[part 7 of 12: package /Cluster]
AUTOSAR XML (schema 4-3-0)
package /Cluster  (continued)
  can cluster HCP5_CANFD01: baudrate=500000, protocol-name=CAN, protocol-version=2.0, bus-off-recovery={bor-counter-l-1-to-l-2=1, bor-time-l-1=0.05, bor-time-l-2=0.2}, can-fd-baudrate=2000000  (continued)
    can physical channel CHNL: comm-connectors=CN_HCP5_CANFD01  (continued)
      frame XCP_Hybrid_01_DTO_01_FD_XIX_HCP5_CANFD01: id 0x1BFC6701, from BMC_HV, frame-length=64, can-addressing-mode=EXTENDED, can-frame-rx-behavior=CAN-FD, can-frame-tx-behavior=CAN-FD
        general purpose i pdu XCP_Hybrid_01_DTO_01_FD_XIX_HCP5_CANFD01: category=XCP, length=64
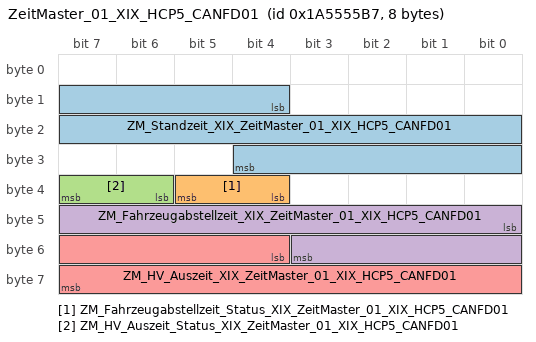
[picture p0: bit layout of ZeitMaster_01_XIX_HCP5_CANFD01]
      frame ZeitMaster_01_XIX_HCP5_CANFD01: id 0x1A5555B7, to BMC_HV, frame-length=8, can-addressing-mode=EXTENDED, can-frame-rx-behavior=CAN-FD, can-frame-tx-behavior=CAN-FD
        pdu ZeitMaster_01_XIX_HCP5_CANFD01: length=8, transmission-mode-true-timing=cyclic-timing={time-offset=0, time-period=1}, unused-bit-pattern=0
          signal ZM_Standzeit_XIX_ZeitMaster_01_XIX_HCP5_CANFD01: start 12, 17 bit, little-endian, data-type-policy=OVERRIDE, i-signal-type=PRIMITIVE, init-value=131070, base-type=BT_ZM_Standzeit, invalid-value=Invalid_ZM_Standzeit_XIX_ZeitMaster_01_XIX_HCP5_CANFD01:131071, compu {phys=raw for raw 0..131068, 131069=Cx1fffd_nicht_verfuegbar (CM_ZM_Standzeit_Cx1fffd_nicht_verfuegbar), 131070=Cx1fffe_Init (CM_ZM_Standzeit_Cx1fffe_Init), 131071=Cx1ffff_Fehler (CM_ZM_Standzeit_Cx1ffff_Fehler); unit Unit_Secon}, range phys 0..131068 Unit_Secon, raw 0..131071, unit=Unit_Secon, transfer-property=PENDING  # Standzeit des Fahrzeugs
          signal ZM_Fahrzeugabstellzeit_Status_XIX_ZeitMaster_01_XIX_HCP5_CANFD01: start 36, 2 bit, little-endian, data-type-policy=OVERRIDE, i-signal-type=PRIMITIVE, init-value=0, base-type=BT_ZM_Fahrzeugabstellzeit_Status, compu {0=Cx0_Abstellzeit_nicht_berechnet (CM_ZM_Fahrzeugabstellzeit_Status_Cx0_Abstellzeit_nicht_berechnet), 1=Cx1_Abstellzeit_berechnet (CM_ZM_Fahrzeugabstellzeit_Status_Cx1_Abstellzeit_berechnet), 2=Cx2_Abstellzeit_Minimalwert (CM_ZM_Fahrzeugabstellzeit_Status_Cx2_Abstellzeit_Minimalwert), 3=Cx3_Abstellzeit_ungueltig (CM_ZM_Fahrzeugabstellzeit_Status_Cx3_Abstellzeit_ungueltig)}, range raw 0..3, transfer-property=PENDING  # Status Fahrzeugabstellzeit
          signal ZM_HV_Auszeit_Status_XIX_ZeitMaster_01_XIX_HCP5_CANFD01: start 38, 2 bit, little-endian, data-type-policy=OVERRIDE, i-signal-type=PRIMITIVE, init-value=0, base-type=BT_ZM_HV_Auszeit_Status, compu {0=Cx0_nicht_berechnet (CM_ZM_HV_Auszeit_Status_Cx0_nicht_berechnet), 1=Cx1_berechnet (CM_ZM_HV_Auszeit_Status_Cx1_berechnet), 2=Cx2_Minimalwert (CM_ZM_HV_Auszeit_Status_Cx2_Minimalwert), 3=Cx3_ungueltig (CM_ZM_HV_Auszeit_Status_Cx3_ungueltig)}, range raw 0..3, transfer-property=PENDING, to BMC_HV(timeout 5 s)  # Status HV-Auszeit
          signal ZM_Fahrzeugabstellzeit_XIX_ZeitMaster_01_XIX_HCP5_CANFD01: start 40, 12 bit, little-endian, data-type-policy=OVERRIDE, i-signal-type=PRIMITIVE, init-value=4094, base-type=BT_ZM_Fahrzeugabstellzeit, invalid-value=Invalid_ZM_Fahrzeugabstellzeit_XIX_ZeitMaster_01_XIX_HCP5_CANFD01:4095, compu {phys=raw*4 for raw 0..4093, 4094=Cxffe_Init (CM_ZM_Fahrzeugabstellzeit_Cxffe_Init), 4095=Cxfff_Fehler (CM_ZM_Fahrzeugabstellzeit_Cxfff_Fehler); unit Unit_Minut}, range phys 0..16372 Unit_Minut, raw 0..4095, unit=Unit_Minut, transfer-property=PENDING  # Zeit seit letzter Fahrbereitschaft
          signal ZM_HV_Auszeit_XIX_ZeitMaster_01_XIX_HCP5_CANFD01: start 52, 12 bit, little-endian, data-type-policy=OVERRIDE, i-signal-type=PRIMITIVE, init-value=4094, base-type=BT_ZM_HV_Auszeit, invalid-value=Invalid_ZM_HV_Auszeit_XIX_ZeitMaster_01_XIX_HCP5_CANFD01:4095, compu {phys=raw*4 for raw 0..4093, 4094=Cxffe_Init (CM_ZM_HV_Auszeit_Cxffe_Init), 4095=Cxfff_Fehler (CM_ZM_HV_Auszeit_Cxfff_Fehler); unit Unit_Minut}, range phys 0..16372 Unit_Minut, raw 0..4095, unit=Unit_Minut, transfer-property=PENDING, to BMC_HV(timeout 5 s)  # Zeit seit letzter Hochvoltaktivität
      frame Zeitmaster_05_XIX_HCP5_CANFD01: id 0x1A5555AA, to BMC_HV, frame-length=8, can-addressing-mode=EXTENDED, can-frame-rx-behavior=CAN-FD, can-frame-tx-behavior=CAN-FD
        pdu Zeitmaster_05_XIX_HCP5_CANFD01: length=8, transmission-mode-true-timing=cyclic-timing={time-offset=0, time-period=0.5}, unused-bit-pattern=0
          signal ZM_HV_Auszeit_HiRes_XIX_Zeitmaster_05_XIX_HCP5_CANFD01: start 32, 16 bit, little-endian, data-type-policy=OVERRIDE, i-signal-type=PRIMITIVE, init-value=65534, base-type=BT_ZM_HV_Auszeit_HiRes, invalid-value=Invalid_ZM_HV_Auszeit_HiRes_XIX_Zeitmaster_05_XIX_HCP5_CANFD01:65535, compu {phys=raw*0.5 for raw 0..65533, 65534=Cxfffe_Init (CM_ZM_HV_Auszeit_HiRes_Cxfffe_Init), 65535=Cxffff_Fehler (CM_ZM_HV_Auszeit_HiRes_Cxffff_Fehler); unit Unit_Minut}, range phys 0..32766.5 Unit_Minut, raw 0..65535, unit=Unit_Minut, transfer-property=PENDING, to BMC_HV(timeout 5 s)  # Zeit seit letzter Hochvoltaktivität (Erweiterter Wertebereich)
          signal ZM_Fahrzeugabstellzeit_HiRes_XIX_Zeitmaster_05_XIX_HCP5_CANFD01: start 48, 16 bit, little-endian, data-type-policy=OVERRIDE, i-signal-type=PRIMITIVE, init-value=65534, base-type=BT_ZM_Fahrzeugabstellzeit_HiRes, invalid-value=Invalid_ZM_Fahrzeugabstellzeit_HiRes_XIX_Zeitmaster_05_XIX_HCP5_CANFD01:65535, compu {phys=raw*10 for raw 0..65330, 65534=Cxfffe_Init (CM_ZM_Fahrzeugabstellzeit_HiRes_Cxfffe_Init), 65535=Cxffff_Fehler (CM_ZM_Fahrzeugabstellzeit_HiRes_Cxffff_Fehler); unit Unit_Secon}, range phys 0..653300 Unit_Secon, raw 0..65535, unit=Unit_Secon, transfer-property=PENDING  # Zeit seit letzter Fahrbereitschaft (Erweiterter Wertebereich)
      pdu triggering PT_BMC_HV_01_E2E: pdu=BMC_HV_01_XIX_HCP5_CANFD01_E2E, from BMC_HV
      pdu triggering PT_BMC_HV_02_E2E: pdu=BMC_HV_02_XIX_HCP5_CANFD01_E2E, from BMC_HV
      pdu triggering PT_BMC_HV_{06..09}: pdu=BMC_HV_{06..09}_XIX_HCP5_CANFD01, from BMC_HV
      pdu triggering PT_BMC_HV_14: pdu=BMC_HV_14_XIX_HCP5_CANFD01, from BMC_HV
      pdu triggering PT_HCP5_CANFD01_XIX_TPCHType_CANFD_DAAP_XIX_0x1C403F7B_XIX_0x1C423F7B_XIX_Physical: pdu=CDD_HCP5_CANFD01_XIX_TPCHType_CANFD_DAAP_XIX_0x1C403F7B_XIX_0x1C423F7B_XIX_Physical, to BMC_HV
      pdu triggering PT_HCP5_CANFD01_XIX_TPCHType_CANFD_DAAP_XIX_0x1C413FDD_XIX_Functional: pdu=CDD_HCP5_CANFD01_XIX_TPCHType_CANFD_DAAP_XIX_0x1C413FDD_XIX_Functional, to BMC_HV
      pdu triggering PT_HCP5_CANFD01_XIX_TPCHType_CANFD_DAAP_XIX_0x1C423F7B_XIX_0x1C403F7B_XIX_Physical: pdu=CDD_HCP5_CANFD01_XIX_TPCHType_CANFD_DAAP_XIX_0x1C423F7B_XIX_0x1C403F7B_XIX_Physical, from BMC_HV
      pdu triggering PT_HCP5_CANFD01_XIX_TPCHType_CANFD_ISO_Diagnose_XIX_0x1C40007B_XIX_0x1C42007B_XIX_Physical: pdu=DCM_HCP5_CANFD01_XIX_TPCHType_CANFD_ISO_Diagnose_XIX_0x1C40007B_XIX_0x1C42007B_XIX_Physical, to BMC_HV
      pdu triggering PT_HCP5_CANFD01_XIX_TPCHType_CANFD_ISO_Diagnose_XIX_0x1C410000_XIX_Functional: pdu=DCM_HCP5_CANFD01_XIX_TPCHType_CANFD_ISO_Diagnose_XIX_0x1C410000_XIX_Functional, to BMC_HV
      pdu triggering PT_HCP5_CANFD01_XIX_TPCHType_CANFD_ISO_Diagnose_XIX_0x1C42007B_XIX_0x1C40007B_XIX_Physical: pdu=DCM_HCP5_CANFD01_XIX_TPCHType_CANFD_ISO_Diagnose_XIX_0x1C42007B_XIX_0x1C40007B_XIX_Physical, from BMC_HV
      pdu triggering PT_HCP5_CANFD01_XIX_TPCHType_CANFD_OBDC_Diagnose_XIX_0x1C40027B_XIX_0x1C42027B_XIX_Physical: pdu=DCM_HCP5_CANFD01_XIX_TPCHType_CANFD_OBDC_Diagnose_XIX_0x1C40027B_XIX_0x1C42027B_XIX_Physical, to BMC_HV
      pdu triggering PT_HCP5_CANFD01_XIX_TPCHType_CANFD_OBDC_Diagnose_XIX_0x1C410200_XIX_Functional: pdu=DCM_HCP5_CANFD01_XIX_TPCHType_CANFD_OBDC_Diagnose_XIX_0x1C410200_XIX_Functional, to BMC_HV
      pdu triggering PT_HCP5_CANFD01_XIX_TPCHType_CANFD_OBDC_Diagnose_XIX_0x1C42027B_XIX_0x1C40027B_XIX_Physical: pdu=DCM_HCP5_CANFD01_XIX_TPCHType_CANFD_OBDC_Diagnose_XIX_0x1C42027B_XIX_0x1C40027B_XIX_Physical, from BMC_HV
      pdu triggering PT_HCP5_CANFD01_XIX_TPCHType_CANHS_Flash_DIA_XIX_0x17FC16D0_XIX_0x17FE16D0_XIX_Physical: pdu=DCM_HCP5_CANFD01_XIX_TPCHType_CANHS_Flash_DIA_XIX_0x17FC16D0_XIX_0x17FE16D0_XIX_Physical, to BMC_HV
      pdu triggering PT_HCP5_CANFD01_XIX_TPCHType_CANHS_Flash_DIA_XIX_0x17FC17B1_XIX_0x17FE17B1_XIX_Physical: pdu=DCM_HCP5_CANFD01_XIX_TPCHType_CANHS_Flash_DIA_XIX_0x17FC17B1_XIX_0x17FE17B1_XIX_Physical, to BMC_HV
      pdu triggering PT_HCP5_CANFD01_XIX_TPCHType_CANHS_Flash_DIA_XIX_0x17FC17B2_XIX_0x17FE17B2_XIX_Physical: pdu=DCM_HCP5_CANFD01_XIX_TPCHType_CANHS_Flash_DIA_XIX_0x17FC17B2_XIX_0x17FE17B2_XIX_Physical, to BMC_HV
      pdu triggering PT_HCP5_CANFD01_XIX_TPCHType_CANHS_Flash_DIA_XIX_0x17FE16D0_XIX_0x17FC16D0_XIX_Physical: pdu=DCM_HCP5_CANFD01_XIX_TPCHType_CANHS_Flash_DIA_XIX_0x17FE16D0_XIX_0x17FC16D0_XIX_Physical, from BMC_HV
      pdu triggering PT_HCP5_CANFD01_XIX_TPCHType_CANHS_Flash_DIA_XIX_0x17FE17B1_XIX_0x17FC17B1_XIX_Physical: pdu=DCM_HCP5_CANFD01_XIX_TPCHType_CANHS_Flash_DIA_XIX_0x17FE17B1_XIX_0x17FC17B1_XIX_Physical, from BMC_HV
      pdu triggering PT_HCP5_CANFD01_XIX_TPCHType_CANHS_Flash_DIA_XIX_0x17FE17B2_XIX_0x17FC17B2_XIX_Physical: pdu=DCM_HCP5_CANFD01_XIX_TPCHType_CANHS_Flash_DIA_XIX_0x17FE17B2_XIX_0x17FC17B2_XIX_Physical, from BMC_HV
      pdu triggering PT_HCP5_CANFD01_XIX_TPCHType_CANHS_ISO_Diagnose_XIX_0x17FC007B_XIX_0x17FE007B_XIX_Physical: pdu=DCM_HCP5_CANFD01_XIX_TPCHType_CANHS_ISO_Diagnose_XIX_0x17FC007B_XIX_0x17FE007B_XIX_Physical, to BMC_HV
      pdu triggering PT_HCP5_CANFD01_XIX_TPCHType_CANHS_ISO_Diagnose_XIX_0x17FE007B_XIX_0x17FC007B_XIX_Physical: pdu=DCM_HCP5_CANFD01_XIX_TPCHType_CANHS_ISO_Diagnose_XIX_0x17FE007B_XIX_0x17FC007B_XIX_Physical, from BMC_HV
      pdu triggering PT_HCP5_CANFD01_XIX_TPCHType_CANHS_ISO_Diagnose_XIX_0x700_XIX_Functional: pdu=DCM_HCP5_CANFD01_XIX_TPCHType_CANHS_ISO_Diagnose_XIX_0x700_XIX_Functional, to BMC_HV
      pdu triggering PT_HCP5_CANFD01_XIX_TPCHType_CANHS_OBDC_SSN_Diagnose_XIX_0x17FC70D0_XIX_0x17FE70D0_XIX_Physical: pdu=DCM_HCP5_CANFD01_XIX_TPCHType_CANHS_OBDC_SSN_Diagnose_XIX_0x17FC70D0_XIX_0x17FE70D0_XIX_Physical, to BMC_HV
      pdu triggering PT_HCP5_CANFD01_XIX_TPCHType_CANHS_OBDC_SSN_Diagnose_XIX_0x17FC71B1_XIX_0x17FE71B1_XIX_Physical: pdu=DCM_HCP5_CANFD01_XIX_TPCHType_CANHS_OBDC_SSN_Diagnose_XIX_0x17FC71B1_XIX_0x17FE71B1_XIX_Physical, to BMC_HV
      pdu triggering PT_HCP5_CANFD01_XIX_TPCHType_CANHS_OBDC_SSN_Diagnose_XIX_0x17FC71B2_XIX_0x17FE71B2_XIX_Physical: pdu=DCM_HCP5_CANFD01_XIX_TPCHType_CANHS_OBDC_SSN_Diagnose_XIX_0x17FC71B2_XIX_0x17FE71B2_XIX_Physical, to BMC_HV
      pdu triggering PT_HCP5_CANFD01_XIX_TPCHType_CANHS_OBDC_SSN_Diagnose_XIX_0x17FE70D0_XIX_0x17FC70D0_XIX_Physical: pdu=DCM_HCP5_CANFD01_XIX_TPCHType_CANHS_OBDC_SSN_Diagnose_XIX_0x17FE70D0_XIX_0x17FC70D0_XIX_Physical, from BMC_HV
      pdu triggering PT_HCP5_CANFD01_XIX_TPCHType_CANHS_OBDC_SSN_Diagnose_XIX_0x17FE71B1_XIX_0x17FC71B1_XIX_Physical: pdu=DCM_HCP5_CANFD01_XIX_TPCHType_CANHS_OBDC_SSN_Diagnose_XIX_0x17FE71B1_XIX_0x17FC71B1_XIX_Physical, from BMC_HV
      pdu triggering PT_HCP5_CANFD01_XIX_TPCHType_CANHS_OBDC_SSN_Diagnose_XIX_0x17FE71B2_XIX_0x17FC71B2_XIX_Physical: pdu=DCM_HCP5_CANFD01_XIX_TPCHType_CANHS_OBDC_SSN_Diagnose_XIX_0x17FE71B2_XIX_0x17FC71B2_XIX_Physical, from BMC_HV
      pdu triggering PT_HCP5_CANFD01_XIX_TPCHType_CANHS_OBDx_XIX_0x18DA05F1_XIX_0x18DAF105_XIX_Physical: pdu=DCM_HCP5_CANFD01_XIX_TPCHType_CANHS_OBDx_XIX_0x18DA05F1_XIX_0x18DAF105_XIX_Physical, to BMC_HV
      pdu triggering PT_HCP5_CANFD01_XIX_TPCHType_CANHS_OBDx_XIX_0x18DAF105_XIX_0x18DA05F1_XIX_Physical: pdu=DCM_HCP5_CANFD01_XIX_TPCHType_CANHS_OBDx_XIX_0x18DAF105_XIX_0x18DA05F1_XIX_Physical, from BMC_HV
      pdu triggering PT_HCP5_CANFD01_XIX_TPCHType_CANHS_OBDx_XIX_0x18DB33F1_XIX_Functional: pdu=DCM_HCP5_CANFD01_XIX_TPCHType_CANHS_OBDx_XIX_0x18DB33F1_XIX_Functional, to BMC_HV
      pdu triggering PT_HVK_03_E2E: pdu=HVK_03_XIX_HCP5_CANFD01_E2E, to BMC_HV
      pdu triggering PT_OBD_HCP1: pdu=OBD_HCP1_XIX_HCP5_CANFD01, to BMC_HV
      pdu triggering PT_OBD_Hybrid_01: pdu=OBD_Hybrid_01_XIX_HCP5_CANFD01, from BMC_HV
      pdu triggering PT_SOK_Zeit_Hybrid_01_Resp_01: pdu=SOK_Zeit_Hybrid_01_Resp_01_XIX_HCP5_CANFD01, to BMC_HV
  can cluster BMC_CAN01: baudrate=500000, protocol-name=CAN, protocol-version=2.0, bus-off-recovery={bor-counter-l-1-to-l-2=1, bor-time-l-1=0.05, bor-time-l-2=0.2}
    can physical channel CHNL: comm-connectors=CN_BMC_CAN01
      frame BJB_08_XIX_BMC_CAN01: id 0x12DD556E, to BMC_HV, frame-length=8, can-addressing-mode=EXTENDED, can-frame-rx-behavior=CAN-20, can-frame-tx-behavior=CAN-20
        pdu BJB_08_XIX_BMC_CAN01: length=8, transmission-mode-true-timing=cyclic-timing={time-offset=0, time-period=0.1}, unused-bit-pattern=0
          signal BJB_ErrMem_State_XIX_BJB_08_XIX_BMC_CAN01: start 12, 2 bit, little-endian, data-type-policy=OVERRIDE, i-signal-type=PRIMITIVE, init-value=2, base-type=BT_BJB_ErrMem_State, compu {1=Cx1_ErrMem_Active (CM_BJB_ErrMem_State_Cx1_ErrMem_Active), 2=Cx2_ErrMem_Init_Progress (CM_BJB_ErrMem_State_Cx2_ErrMem_Init_Progress), 3=Cx3_ErrMem_Init_Done (CM_BJB_ErrMem_State_Cx3_ErrMem_Init_Done)}, range raw 1..3, transfer-property=PENDING, to BMC_HV(timeout 1 s)  # Error Memory State
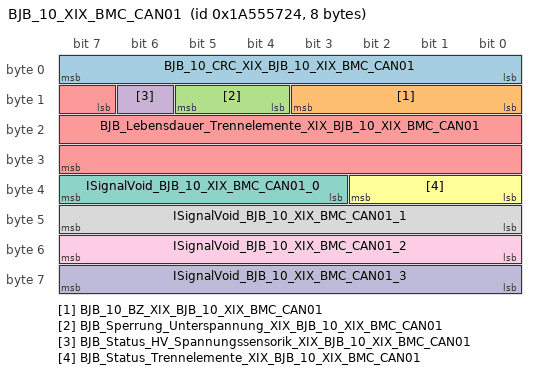
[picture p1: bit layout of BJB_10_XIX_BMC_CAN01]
      frame BJB_10_XIX_BMC_CAN01: id 0x1A555724, to BMC_HV, frame-length=8, can-addressing-mode=EXTENDED, can-frame-rx-behavior=CAN-20, can-frame-tx-behavior=CAN-20
        pdu BJB_10_XIX_BMC_CAN01_E2E: length=8, transmission-mode-true-timing=event-controlled-timing={number-of-repetitions=0, repetition-period=0}, unused-bit-pattern=0  # Fuer die Botschaft ist das Cyclic-Timing 1.0 zu verwenden.
          signal BJB_10_CRC_XIX_BJB_10_XIX_BMC_CAN01: start 0, 8 bit, little-endian, data-type-policy=OVERRIDE, i-signal-type=PRIMITIVE, init-value=0, base-type=BT_BJB_10_CRC, to BMC_HV(timeout 5 s)
          signal BJB_10_BZ_XIX_BJB_10_XIX_BMC_CAN01: start 8, 4 bit, little-endian, data-type-policy=OVERRIDE, i-signal-type=PRIMITIVE, init-value=0, base-type=BT_BJB_10_BZ, to BMC_HV(timeout 5 s)
          signal BJB_Sperrung_Unterspannung_XIX_BJB_10_XIX_BMC_CAN01: start 12, 2 bit, little-endian, data-type-policy=OVERRIDE, i-signal-type=PRIMITIVE, init-value=2, base-type=BT_BJB_Sperrung_Unterspannung, invalid-value=Invalid_BJB_Sperrung_Unterspannung_XIX_BJB_10_XIX_BMC_CAN01:3, compu {0=Cx0_keine_Sperrung (CM_BJB_Sperrung_Unterspannung_Cx0_keine_Sperrung), 1=Cx1_Sperrung (CM_BJB_Sperrung_Unterspannung_Cx1_Sperrung), 2=Cx2_InitWert (CM_BJB_Sperrung_Unterspannung_Cx2_InitWert), 3=Cx3_Fehler (CM_BJB_Sperrung_Unterspannung_Cx3_Fehler)}, range raw 0..3, to BMC_HV(timeout 5 s)  # Status Sperrung durch Unterspannung zum Datenaustausch für redundante Datenspeicherung
          signal BJB_Status_HV_Spannungssensorik_XIX_BJB_10_XIX_BMC_CAN01: start 14, 1 bit, little-endian, data-type-policy=OVERRIDE, i-signal-type=PRIMITIVE, init-value=0, base-type=BT_BJB_Status_HV_Spannungssensorik, invalid-value=Invalid_BJB_Status_HV_Spannungssensorik_XIX_BJB_10_XIX_BMC_CAN01:1, compu {0=Cx0_InitWert_kein_Fehler (CM_BJB_Status_HV_Spannungssensorik_Cx0_InitWert_kein_Fehler), 1=Cx1_Fehler (CM_BJB_Status_HV_Spannungssensorik_Cx1_Fehler)}, range raw 0..1, to BMC_HV(timeout 5 s)  # Status HV Spannungssensorik zum Datenaustausch für redundante Datenspeicherung
          signal BJB_Lebensdauer_Trennelemente_XIX_BJB_10_XIX_BMC_CAN01: start 15, 17 bit, little-endian, data-type-policy=OVERRIDE, i-signal-type=PRIMITIVE, init-value=131070, base-type=BT_BJB_Lebensdauer_Trennelemente, invalid-value=Invalid_BJB_Lebensdauer_Trennelemente_XIX_BJB_10_XIX_BMC_CAN01:131071, compu {phys=raw for raw 0..100000, 131070=Cx1fffe_InitWert (CM_BJB_Lebensdauer_Trennelemente_Cx1fffe_InitWert), 131071=Cx1ffff_Fehler (CM_BJB_Lebensdauer_Trennelemente_Cx1ffff_Fehler); unit Unit_None}, range phys 0..100000 Unit_None, raw 0..131071, unit=Unit_None, to BMC_HV(timeout 5 s)  # Lebensdauerzähler Trennelemente zum Datenaustausch für redundante Datenspeicherung
          signal BJB_Status_Trennelemente_XIX_BJB_10_XIX_BMC_CAN01: start 32, 3 bit, little-endian, data-type-policy=OVERRIDE, i-signal-type=PRIMITIVE, init-value=6, base-type=BT_BJB_Status_Trennelemente, invalid-value=Invalid_BJB_Status_Trennelemente_XIX_BJB_10_XIX_BMC_CAN01:7, compu {0=Cx0_kein_Fehler (CM_BJB_Status_Trennelemente_Cx0_kein_Fehler), 1=Cx1_Haupt_TrEl_klemmt_geschl (CM_BJB_Status_Trennelemente_Cx1_Haupt_TrEl_klemmt_geschl), 2=Cx2_AC_TrEl_klemmt_geschl (CM_BJB_Status_Trennelemente_Cx2_AC_TrEl_klemmt_geschl), 3=Cx3_Haupt_und_AC_TrEl_klemmt_geschl (CM_BJB_Status_Trennelemente_Cx3_Haupt_und_AC_TrEl_klemmt_geschl), 6=Cx6_InitWert (CM_BJB_Status_Trennelemente_Cx6_InitWert), 7=Cx7_Fehler (CM_BJB_Status_Trennelemente_Cx7_Fehler)}, range raw 0..7, to BMC_HV(timeout 5 s)  # Status Trennelemente zum Datenaustausch für redundante Datenspeicherung
          signal ISignalVoid_BJB_10_XIX_BMC_CAN01_0: start 35, 5 bit, little-endian, system signal SignalVoid_BJB_10_0, data-type-policy=OVERRIDE, i-signal-type=PRIMITIVE, base-type=BT_SignalVoid
          signal ISignalVoid_BJB_10_XIX_BMC_CAN01_1: start 40, 8 bit, little-endian, system signal SignalVoid_BJB_10_1, data-type-policy=OVERRIDE, i-signal-type=PRIMITIVE, base-type=BT_SignalVoid
          signal ISignalVoid_BJB_10_XIX_BMC_CAN01_2: start 48, 8 bit, little-endian, system signal SignalVoid_BJB_10_2, data-type-policy=OVERRIDE, i-signal-type=PRIMITIVE, base-type=BT_SignalVoid
          signal ISignalVoid_BJB_10_XIX_BMC_CAN01_3: start 56, 8 bit, little-endian, system signal SignalVoid_BJB_10_3, data-type-policy=OVERRIDE, i-signal-type=PRIMITIVE, base-type=BT_SignalVoid
          mapping SG_BJB_10_XIX_BMC_CAN01: i-signal-group=SG_BJB_10_XIX_BMC_CAN01, transfer-property=TRIGGERED-WITHOUT-REPETITION
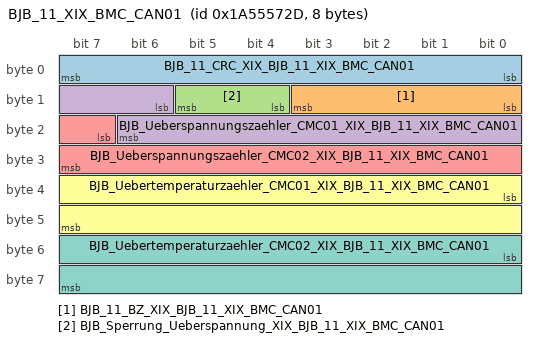
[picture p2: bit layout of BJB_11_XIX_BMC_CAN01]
      frame BJB_11_XIX_BMC_CAN01: id 0x1A55572D, to BMC_HV, frame-length=8, can-addressing-mode=EXTENDED, can-frame-rx-behavior=CAN-20, can-frame-tx-behavior=CAN-20
        pdu BJB_11_XIX_BMC_CAN01_E2E: length=8, transmission-mode-true-timing=event-controlled-timing={number-of-repetitions=0, repetition-period=0}, unused-bit-pattern=0  # Fuer die Botschaft ist das Cyclic-Timing 1.0 zu verwenden.
          signal BJB_11_CRC_XIX_BJB_11_XIX_BMC_CAN01: start 0, 8 bit, little-endian, data-type-policy=OVERRIDE, i-signal-type=PRIMITIVE, init-value=0, base-type=BT_BJB_11_CRC, to BMC_HV(timeout 5 s)
          signal BJB_11_BZ_XIX_BJB_11_XIX_BMC_CAN01: start 8, 4 bit, little-endian, data-type-policy=OVERRIDE, i-signal-type=PRIMITIVE, init-value=0, base-type=BT_BJB_11_BZ, to BMC_HV(timeout 5 s)
          signal BJB_Sperrung_Ueberspannung_XIX_BJB_11_XIX_BMC_CAN01: start 12, 2 bit, little-endian, data-type-policy=OVERRIDE, i-signal-type=PRIMITIVE, init-value=2, base-type=BT_BJB_Sperrung_Ueberspannung, invalid-value=Invalid_BJB_Sperrung_Ueberspannung_XIX_BJB_11_XIX_BMC_CAN01:3, compu {0=Cx0_keine_Sperrung (CM_BJB_Sperrung_Ueberspannung_Cx0_keine_Sperrung), 1=Cx1_Sperrung (CM_BJB_Sperrung_Ueberspannung_Cx1_Sperrung), 2=Cx2_InitWert (CM_BJB_Sperrung_Ueberspannung_Cx2_InitWert), 3=Cx3_Fehler (CM_BJB_Sperrung_Ueberspannung_Cx3_Fehler)}, range raw 0..3, to BMC_HV(timeout 5 s)  # Status Sperrung durch Ueberspannung zum Datenaustausch für redundante Datenspeicherung
          signal BJB_Ueberspannungszaehler_CMC01_XIX_BJB_11_XIX_BMC_CAN01: start 14, 9 bit, little-endian, data-type-policy=OVERRIDE, i-signal-type=PRIMITIVE, init-value=510, base-type=BT_BJB_Ueberspannungszaehler_CMC01, invalid-value=Invalid_BJB_Ueberspannungszaehler_CMC01_XIX_BJB_11_XIX_BMC_CAN01:511, compu {phys=raw for raw 0..400, 510=Cx1fe_InitWert (CM_BJB_Ueberspannungszaehler_CMC01_Cx1fe_InitWert), 511=Cx1ff_Fehler (CM_BJB_Ueberspannungszaehler_CMC01_Cx1ff_Fehler); unit Unit_None}, range phys 0..400 Unit_None, raw 0..511, unit=Unit_None, to BMC_HV(timeout 5 s)  # Überspannungszähler zum Datenaustausch für redundante Datenspeicherung
          signal BJB_Ueberspannungszaehler_CMC02_XIX_BJB_11_XIX_BMC_CAN01: start 23, 9 bit, little-endian, data-type-policy=OVERRIDE, i-signal-type=PRIMITIVE, init-value=510, base-type=BT_BJB_Ueberspannungszaehler_CMC02, invalid-value=Invalid_BJB_Ueberspannungszaehler_CMC02_XIX_BJB_11_XIX_BMC_CAN01:511, compu {phys=raw for raw 0..400, 510=Cx1fe_InitWert (CM_BJB_Ueberspannungszaehler_CMC02_Cx1fe_InitWert), 511=Cx1ff_Fehler (CM_BJB_Ueberspannungszaehler_CMC02_Cx1ff_Fehler); unit Unit_None}, range phys 0..400 Unit_None, raw 0..511, unit=Unit_None, to BMC_HV(timeout 5 s)  # Überspannungszähler zum Datenaustausch für redundante Datenspeicherung
          signal BJB_Uebertemperaturzaehler_CMC01_XIX_BJB_11_XIX_BMC_CAN01: start 32, 16 bit, little-endian, data-type-policy=OVERRIDE, i-signal-type=PRIMITIVE, init-value=65534, base-type=BT_BJB_Uebertemperaturzaehler_CMC01, invalid-value=Invalid_BJB_Uebertemperaturzaehler_CMC01_XIX_BJB_11_XIX_BMC_CAN01:65535, compu {phys=raw*10 for raw 0..60480, 65534=Cxfffe_InitWert (CM_BJB_Uebertemperaturzaehler_CMC01_Cxfffe_InitWert), 65535=Cxffff_Fehler (CM_BJB_Uebertemperaturzaehler_CMC01_Cxffff_Fehler); unit Unit_None}, range phys 0..604800 Unit_None, raw 0..65535, unit=Unit_None, to BMC_HV(timeout 5 s)  # Übertemperaturzähler zum Datenaustausch für redundante Datenspeicherung
          signal BJB_Uebertemperaturzaehler_CMC02_XIX_BJB_11_XIX_BMC_CAN01: start 48, 16 bit, little-endian, data-type-policy=OVERRIDE, i-signal-type=PRIMITIVE, init-value=65534, base-type=BT_BJB_Uebertemperaturzaehler_CMC02, invalid-value=Invalid_BJB_Uebertemperaturzaehler_CMC02_XIX_BJB_11_XIX_BMC_CAN01:65535, compu {phys=raw*10 for raw 0..60480, 65534=Cxfffe_InitWert (CM_BJB_Uebertemperaturzaehler_CMC02_Cxfffe_InitWert), 65535=Cxffff_Fehler (CM_BJB_Uebertemperaturzaehler_CMC02_Cxffff_Fehler); unit Unit_None}, range phys 0..604800 Unit_None, raw 0..65535, unit=Unit_None, to BMC_HV(timeout 5 s)  # Übertemperaturzähler zum Datenaustausch für redundante Datenspeicherung
          mapping SG_BJB_11_XIX_BMC_CAN01: i-signal-group=SG_BJB_11_XIX_BMC_CAN01, transfer-property=TRIGGERED-WITHOUT-REPETITION
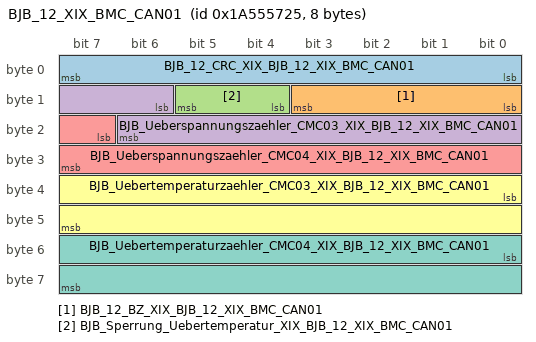
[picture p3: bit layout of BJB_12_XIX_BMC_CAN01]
      frame BJB_12_XIX_BMC_CAN01: id 0x1A555725, to BMC_HV, frame-length=8, can-addressing-mode=EXTENDED, can-frame-rx-behavior=CAN-20, can-frame-tx-behavior=CAN-20
        pdu BJB_12_XIX_BMC_CAN01_E2E: length=8, transmission-mode-true-timing=event-controlled-timing={number-of-repetitions=0, repetition-period=0}, unused-bit-pattern=0  # Fuer die Botschaft ist das Cyclic-Timing 1.0 zu verwenden.
          signal BJB_12_CRC_XIX_BJB_12_XIX_BMC_CAN01: start 0, 8 bit, little-endian, data-type-policy=OVERRIDE, i-signal-type=PRIMITIVE, init-value=0, base-type=BT_BJB_12_CRC, to BMC_HV(timeout 5 s)
          signal BJB_12_BZ_XIX_BJB_12_XIX_BMC_CAN01: start 8, 4 bit, little-endian, data-type-policy=OVERRIDE, i-signal-type=PRIMITIVE, init-value=0, base-type=BT_BJB_12_BZ, to BMC_HV(timeout 5 s)
          signal BJB_Sperrung_Uebertemperatur_XIX_BJB_12_XIX_BMC_CAN01: start 12, 2 bit, little-endian, data-type-policy=OVERRIDE, i-signal-type=PRIMITIVE, init-value=2, base-type=BT_BJB_Sperrung_Uebertemperatur, invalid-value=Invalid_BJB_Sperrung_Uebertemperatur_XIX_BJB_12_XIX_BMC_CAN01:3, compu {0=Cx0_keine_Sperrung (CM_BJB_Sperrung_Uebertemperatur_Cx0_keine_Sperrung), 1=Cx1_Sperrung (CM_BJB_Sperrung_Uebertemperatur_Cx1_Sperrung), 2=Cx2_InitWert (CM_BJB_Sperrung_Uebertemperatur_Cx2_InitWert), 3=Cx3_Fehler (CM_BJB_Sperrung_Uebertemperatur_Cx3_Fehler)}, range raw 0..3, to BMC_HV(timeout 5 s)  # Status Sperrung durch Uebertemperatur zum Datenaustausch für redundante Datenspeicherung
          signal BJB_Ueberspannungszaehler_CMC03_XIX_BJB_12_XIX_BMC_CAN01: start 14, 9 bit, little-endian, data-type-policy=OVERRIDE, i-signal-type=PRIMITIVE, init-value=510, base-type=BT_BJB_Ueberspannungszaehler_CMC03, invalid-value=Invalid_BJB_Ueberspannungszaehler_CMC03_XIX_BJB_12_XIX_BMC_CAN01:511, compu {phys=raw for raw 0..400, 510=Cx1fe_InitWert (CM_BJB_Ueberspannungszaehler_CMC03_Cx1fe_InitWert), 511=Cx1ff_Fehler (CM_BJB_Ueberspannungszaehler_CMC03_Cx1ff_Fehler); unit Unit_None}, range phys 0..400 Unit_None, raw 0..511, unit=Unit_None, to BMC_HV(timeout 5 s)  # Überspannungszähler zum Datenaustausch für redundante Datenspeicherung
          signal BJB_Ueberspannungszaehler_CMC04_XIX_BJB_12_XIX_BMC_CAN01: start 23, 9 bit, little-endian, data-type-policy=OVERRIDE, i-signal-type=PRIMITIVE, init-value=510, base-type=BT_BJB_Ueberspannungszaehler_CMC04, invalid-value=Invalid_BJB_Ueberspannungszaehler_CMC04_XIX_BJB_12_XIX_BMC_CAN01:511, compu {phys=raw for raw 0..400, 510=Cx1fe_InitWert (CM_BJB_Ueberspannungszaehler_CMC04_Cx1fe_InitWert), 511=Cx1ff_Fehler (CM_BJB_Ueberspannungszaehler_CMC04_Cx1ff_Fehler); unit Unit_None}, range phys 0..400 Unit_None, raw 0..511, unit=Unit_None, to BMC_HV(timeout 5 s)  # Überspannungszähler zum Datenaustausch für redundante Datenspeicherung
          signal BJB_Uebertemperaturzaehler_CMC03_XIX_BJB_12_XIX_BMC_CAN01: start 32, 16 bit, little-endian, data-type-policy=OVERRIDE, i-signal-type=PRIMITIVE, init-value=65534, base-type=BT_BJB_Uebertemperaturzaehler_CMC03, invalid-value=Invalid_BJB_Uebertemperaturzaehler_CMC03_XIX_BJB_12_XIX_BMC_CAN01:65535, compu {phys=raw*10 for raw 0..60480, 65534=Cxfffe_InitWert (CM_BJB_Uebertemperaturzaehler_CMC03_Cxfffe_InitWert), 65535=Cxffff_Fehler (CM_BJB_Uebertemperaturzaehler_CMC03_Cxffff_Fehler); unit Unit_None}, range phys 0..604800 Unit_None, raw 0..65535, unit=Unit_None, to BMC_HV(timeout 5 s)  # Übertemperaturzähler zum Datenaustausch für redundante Datenspeicherung
          signal BJB_Uebertemperaturzaehler_CMC04_XIX_BJB_12_XIX_BMC_CAN01: start 48, 16 bit, little-endian, data-type-policy=OVERRIDE, i-signal-type=PRIMITIVE, init-value=65534, base-type=BT_BJB_Uebertemperaturzaehler_CMC04, invalid-value=Invalid_BJB_Uebertemperaturzaehler_CMC04_XIX_BJB_12_XIX_BMC_CAN01:65535, compu {phys=raw*10 for raw 0..60480, 65534=Cxfffe_InitWert (CM_BJB_Uebertemperaturzaehler_CMC04_Cxfffe_InitWert), 65535=Cxffff_Fehler (CM_BJB_Uebertemperaturzaehler_CMC04_Cxffff_Fehler); unit Unit_None}, range phys 0..604800 Unit_None, raw 0..65535, unit=Unit_None, to BMC_HV(timeout 5 s)  # Übertemperaturzähler zum Datenaustausch für redundante Datenspeicherung
          mapping SG_BJB_12_XIX_BMC_CAN01: i-signal-group=SG_BJB_12_XIX_BMC_CAN01, transfer-property=TRIGGERED-WITHOUT-REPETITION
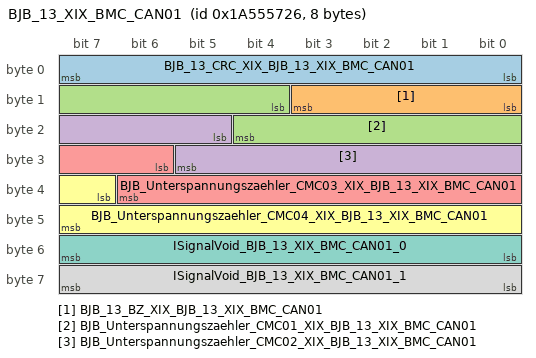
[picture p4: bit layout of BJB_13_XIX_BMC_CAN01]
      frame BJB_13_XIX_BMC_CAN01: id 0x1A555726, to BMC_HV, frame-length=8, can-addressing-mode=EXTENDED, can-frame-rx-behavior=CAN-20, can-frame-tx-behavior=CAN-20
        pdu BJB_13_XIX_BMC_CAN01_E2E: length=8, transmission-mode-true-timing=event-controlled-timing={number-of-repetitions=0, repetition-period=0}, unused-bit-pattern=0  # Fuer die Botschaft ist das Cyclic-Timing 1.0 zu verwenden.
          signal BJB_13_CRC_XIX_BJB_13_XIX_BMC_CAN01: start 0, 8 bit, little-endian, data-type-policy=OVERRIDE, i-signal-type=PRIMITIVE, init-value=0, base-type=BT_BJB_13_CRC, to BMC_HV(timeout 5 s)
          signal BJB_13_BZ_XIX_BJB_13_XIX_BMC_CAN01: start 8, 4 bit, little-endian, data-type-policy=OVERRIDE, i-signal-type=PRIMITIVE, init-value=0, base-type=BT_BJB_13_BZ, to BMC_HV(timeout 5 s)
          signal BJB_Unterspannungszaehler_CMC01_XIX_BJB_13_XIX_BMC_CAN01: start 12, 9 bit, little-endian, data-type-policy=OVERRIDE, i-signal-type=PRIMITIVE, init-value=510, base-type=BT_BJB_Unterspannungszaehler_CMC01, invalid-value=Invalid_BJB_Unterspannungszaehler_CMC01_XIX_BJB_13_XIX_BMC_CAN01:511, compu {phys=raw for raw 0..400, 510=Cx1fe_InitWert (CM_BJB_Unterspannungszaehler_CMC01_Cx1fe_InitWert), 511=Cx1ff_Fehler (CM_BJB_Unterspannungszaehler_CMC01_Cx1ff_Fehler); unit Unit_None}, range phys 0..400 Unit_None, raw 0..511, unit=Unit_None, to BMC_HV(timeout 5 s)  # Unterspannungszähler zum Datenaustausch für redundante Datenspeicherung
          signal BJB_Unterspannungszaehler_CMC02_XIX_BJB_13_XIX_BMC_CAN01: start 21, 9 bit, little-endian, data-type-policy=OVERRIDE, i-signal-type=PRIMITIVE, init-value=510, base-type=BT_BJB_Unterspannungszaehler_CMC02, invalid-value=Invalid_BJB_Unterspannungszaehler_CMC02_XIX_BJB_13_XIX_BMC_CAN01:511, compu {phys=raw for raw 0..400, 510=Cx1fe_InitWert (CM_BJB_Unterspannungszaehler_CMC02_Cx1fe_InitWert), 511=Cx1ff_Fehler (CM_BJB_Unterspannungszaehler_CMC02_Cx1ff_Fehler); unit Unit_None}, range phys 0..400 Unit_None, raw 0..511, unit=Unit_None, to BMC_HV(timeout 5 s)  # Unterspannungszähler zum Datenaustausch für redundante Datenspeicherung
          signal BJB_Unterspannungszaehler_CMC03_XIX_BJB_13_XIX_BMC_CAN01: start 30, 9 bit, little-endian, data-type-policy=OVERRIDE, i-signal-type=PRIMITIVE, init-value=510, base-type=BT_BJB_Unterspannungszaehler_CMC03, invalid-value=Invalid_BJB_Unterspannungszaehler_CMC03_XIX_BJB_13_XIX_BMC_CAN01:511, compu {phys=raw for raw 0..400, 510=Cx1fe_InitWert (CM_BJB_Unterspannungszaehler_CMC03_Cx1fe_InitWert), 511=Cx1ff_Fehler (CM_BJB_Unterspannungszaehler_CMC03_Cx1ff_Fehler); unit Unit_None}, range phys 0..400 Unit_None, raw 0..511, unit=Unit_None, to BMC_HV(timeout 5 s)  # Unterspannungszähler zum Datenaustausch für redundante Datenspeicherung
          signal BJB_Unterspannungszaehler_CMC04_XIX_BJB_13_XIX_BMC_CAN01: start 39, 9 bit, little-endian, data-type-policy=OVERRIDE, i-signal-type=PRIMITIVE, init-value=510, base-type=BT_BJB_Unterspannungszaehler_CMC04, invalid-value=Invalid_BJB_Unterspannungszaehler_CMC04_XIX_BJB_13_XIX_BMC_CAN01:511, compu {phys=raw for raw 0..400, 510=Cx1fe_InitWert (CM_BJB_Unterspannungszaehler_CMC04_Cx1fe_InitWert), 511=Cx1ff_Fehler (CM_BJB_Unterspannungszaehler_CMC04_Cx1ff_Fehler); unit Unit_None}, range phys 0..400 Unit_None, raw 0..511, unit=Unit_None, to BMC_HV(timeout 5 s)  # Unterspannungszähler zum Datenaustausch für redundante Datenspeicherung
          signal ISignalVoid_BJB_13_XIX_BMC_CAN01_0: start 48, 8 bit, little-endian, system signal SignalVoid_BJB_13_0, data-type-policy=OVERRIDE, i-signal-type=PRIMITIVE, base-type=BT_SignalVoid
          signal ISignalVoid_BJB_13_XIX_BMC_CAN01_1: start 56, 8 bit, little-endian, system signal SignalVoid_BJB_13_1, data-type-policy=OVERRIDE, i-signal-type=PRIMITIVE, base-type=BT_SignalVoid
          mapping SG_BJB_13_XIX_BMC_CAN01: i-signal-group=SG_BJB_13_XIX_BMC_CAN01, transfer-property=TRIGGERED-WITHOUT-REPETITION
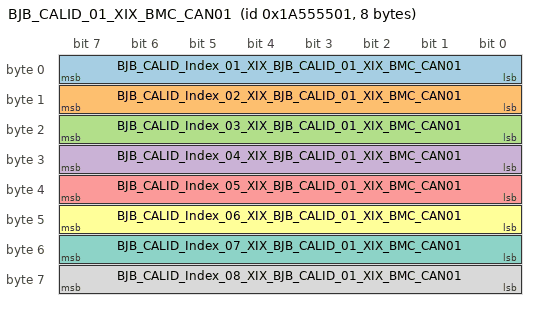
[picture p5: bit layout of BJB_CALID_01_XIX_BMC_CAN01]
      frame BJB_CALID_01_XIX_BMC_CAN01: id 0x1A555501, to BMC_HV, frame-length=8, can-addressing-mode=EXTENDED, can-frame-rx-behavior=CAN-20, can-frame-tx-behavior=CAN-20
        pdu BJB_CALID_01_XIX_BMC_CAN01: length=8, transmission-mode-true-timing=cyclic-timing={time-offset=0, time-period=1}, unused-bit-pattern=0
          signal BJB_CALID_Index_01_XIX_BJB_CALID_01_XIX_BMC_CAN01: start 0, 8 bit, little-endian, data-type-policy=OVERRIDE, i-signal-type=PRIMITIVE, init-value=63, base-type=BT_BJB_CALID_Index_01, compu {0=Cx0_Init (CM_BJB_CALID_Index_01_Cx0_Init)}, range raw 0, transfer-property=PENDING, to BMC_HV(timeout 5 s)  # Calibration-Identification Index_01
          signal BJB_CALID_Index_02_XIX_BJB_CALID_01_XIX_BMC_CAN01: start 8, 8 bit, little-endian, data-type-policy=OVERRIDE, i-signal-type=PRIMITIVE, init-value=63, base-type=BT_BJB_CALID_Index_02, compu {0=Cx0_Init (CM_BJB_CALID_Index_02_Cx0_Init)}, range raw 0, transfer-property=PENDING, to BMC_HV(timeout 5 s)  # Calibration-Identification Index_02
          signal BJB_CALID_Index_03_XIX_BJB_CALID_01_XIX_BMC_CAN01: start 16, 8 bit, little-endian, data-type-policy=OVERRIDE, i-signal-type=PRIMITIVE, init-value=63, base-type=BT_BJB_CALID_Index_03, compu {0=Cx0_Init (CM_BJB_CALID_Index_03_Cx0_Init)}, range raw 0, transfer-property=PENDING, to BMC_HV(timeout 5 s)  # Calibration-Identification Index_03
          signal BJB_CALID_Index_04_XIX_BJB_CALID_01_XIX_BMC_CAN01: start 24, 8 bit, little-endian, data-type-policy=OVERRIDE, i-signal-type=PRIMITIVE, init-value=63, base-type=BT_BJB_CALID_Index_04, compu {0=Cx0_Init (CM_BJB_CALID_Index_04_Cx0_Init)}, range raw 0, transfer-property=PENDING, to BMC_HV(timeout 5 s)  # Calibration-Identification Index_04
          signal BJB_CALID_Index_05_XIX_BJB_CALID_01_XIX_BMC_CAN01: start 32, 8 bit, little-endian, data-type-policy=OVERRIDE, i-signal-type=PRIMITIVE, init-value=63, base-type=BT_BJB_CALID_Index_05, compu {0=Cx0_Init (CM_BJB_CALID_Index_05_Cx0_Init)}, range raw 0, transfer-property=PENDING, to BMC_HV(timeout 5 s)  # Calibration-Identification Index_05
          signal BJB_CALID_Index_06_XIX_BJB_CALID_01_XIX_BMC_CAN01: start 40, 8 bit, little-endian, data-type-policy=OVERRIDE, i-signal-type=PRIMITIVE, init-value=63, base-type=BT_BJB_CALID_Index_06, compu {0=Cx0_Init (CM_BJB_CALID_Index_06_Cx0_Init)}, range raw 0, transfer-property=PENDING, to BMC_HV(timeout 5 s)  # Calibration-Identification Index_06
          signal BJB_CALID_Index_07_XIX_BJB_CALID_01_XIX_BMC_CAN01: start 48, 8 bit, little-endian, data-type-policy=OVERRIDE, i-signal-type=PRIMITIVE, init-value=63, base-type=BT_BJB_CALID_Index_07, compu {0=Cx0_Init (CM_BJB_CALID_Index_07_Cx0_Init)}, range raw 0, transfer-property=PENDING, to BMC_HV(timeout 5 s)  # Calibration-Identification Index_07
          signal BJB_CALID_Index_08_XIX_BJB_CALID_01_XIX_BMC_CAN01: start 56, 8 bit, little-endian, data-type-policy=OVERRIDE, i-signal-type=PRIMITIVE, init-value=63, base-type=BT_BJB_CALID_Index_08, compu {0=Cx0_Init (CM_BJB_CALID_Index_08_Cx0_Init)}, range raw 0, transfer-property=PENDING, to BMC_HV(timeout 5 s)  # Calibration-Identification Index_08
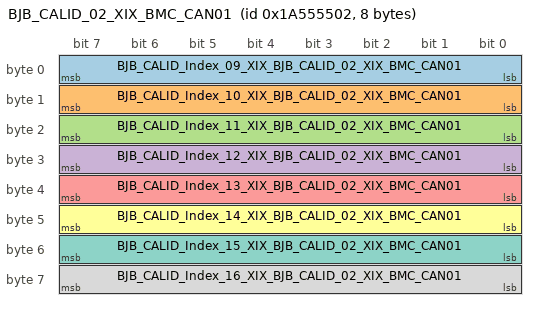
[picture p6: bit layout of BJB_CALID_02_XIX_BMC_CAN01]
      frame BJB_CALID_02_XIX_BMC_CAN01: id 0x1A555502, to BMC_HV, frame-length=8, can-addressing-mode=EXTENDED, can-frame-rx-behavior=CAN-20, can-frame-tx-behavior=CAN-20
        pdu BJB_CALID_02_XIX_BMC_CAN01: length=8, transmission-mode-true-timing=cyclic-timing={time-offset=0, time-period=1}, unused-bit-pattern=0
          signal BJB_CALID_Index_09_XIX_BJB_CALID_02_XIX_BMC_CAN01: start 0, 8 bit, little-endian, data-type-policy=OVERRIDE, i-signal-type=PRIMITIVE, init-value=63, base-type=BT_BJB_CALID_Index_09, compu {0=Cx0_Init (CM_BJB_CALID_Index_09_Cx0_Init)}, range raw 0, transfer-property=PENDING, to BMC_HV(timeout 5 s)  # Calibration-Identification Index_09
          signal BJB_CALID_Index_10_XIX_BJB_CALID_02_XIX_BMC_CAN01: start 8, 8 bit, little-endian, data-type-policy=OVERRIDE, i-signal-type=PRIMITIVE, init-value=63, base-type=BT_BJB_CALID_Index_10, compu {0=Cx0_Init (CM_BJB_CALID_Index_10_Cx0_Init)}, range raw 0, transfer-property=PENDING, to BMC_HV(timeout 5 s)  # Calibration-Identification Index_10
          signal BJB_CALID_Index_11_XIX_BJB_CALID_02_XIX_BMC_CAN01: start 16, 8 bit, little-endian, data-type-policy=OVERRIDE, i-signal-type=PRIMITIVE, init-value=63, base-type=BT_BJB_CALID_Index_11, compu {0=Cx0_Init (CM_BJB_CALID_Index_11_Cx0_Init)}, range raw 0, transfer-property=PENDING, to BMC_HV(timeout 5 s)  # Calibration-Identification Index_01
          signal BJB_CALID_Index_12_XIX_BJB_CALID_02_XIX_BMC_CAN01: start 24, 8 bit, little-endian, data-type-policy=OVERRIDE, i-signal-type=PRIMITIVE, init-value=63, base-type=BT_BJB_CALID_Index_12, compu {0=Cx0_Init (CM_BJB_CALID_Index_12_Cx0_Init)}, range raw 0, transfer-property=PENDING, to BMC_HV(timeout 5 s)  # Calibration-Identification Index_12
          signal BJB_CALID_Index_13_XIX_BJB_CALID_02_XIX_BMC_CAN01: start 32, 8 bit, little-endian, data-type-policy=OVERRIDE, i-signal-type=PRIMITIVE, init-value=63, base-type=BT_BJB_CALID_Index_13, compu {0=Cx0_Init (CM_BJB_CALID_Index_13_Cx0_Init)}, range raw 0, transfer-property=PENDING, to BMC_HV(timeout 5 s)  # Calibration-Identification Index_13
          signal BJB_CALID_Index_14_XIX_BJB_CALID_02_XIX_BMC_CAN01: start 40, 8 bit, little-endian, data-type-policy=OVERRIDE, i-signal-type=PRIMITIVE, init-value=63, base-type=BT_BJB_CALID_Index_14, compu {0=Cx0_Init (CM_BJB_CALID_Index_14_Cx0_Init)}, range raw 0, transfer-property=PENDING, to BMC_HV(timeout 5 s)  # Calibration-Identification Index_14
          signal BJB_CALID_Index_15_XIX_BJB_CALID_02_XIX_BMC_CAN01: start 48, 8 bit, little-endian, data-type-policy=OVERRIDE, i-signal-type=PRIMITIVE, init-value=63, base-type=BT_BJB_CALID_Index_15, compu {0=Cx0_Init (CM_BJB_CALID_Index_15_Cx0_Init)}, range raw 0, transfer-property=PENDING, to BMC_HV(timeout 5 s)  # Calibration-Identification Index_15
          signal BJB_CALID_Index_16_XIX_BJB_CALID_02_XIX_BMC_CAN01: start 56, 8 bit, little-endian, data-type-policy=OVERRIDE, i-signal-type=PRIMITIVE, init-value=63, base-type=BT_BJB_CALID_Index_16, compu {0=Cx0_Init (CM_BJB_CALID_Index_16_Cx0_Init)}, range raw 0, transfer-property=PENDING, to BMC_HV(timeout 5 s)  # Calibration-Identification Index_16
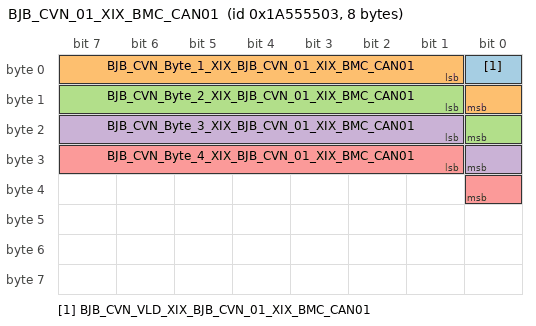
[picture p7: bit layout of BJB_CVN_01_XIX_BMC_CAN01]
      frame BJB_CVN_01_XIX_BMC_CAN01: id 0x1A555503, to BMC_HV, frame-length=8, can-addressing-mode=EXTENDED, can-frame-rx-behavior=CAN-20, can-frame-tx-behavior=CAN-20
        pdu BJB_CVN_01_XIX_BMC_CAN01: length=8, transmission-mode-true-timing=cyclic-timing={time-offset=0, time-period=1}, unused-bit-pattern=0
          signal BJB_CVN_VLD_XIX_BJB_CVN_01_XIX_BMC_CAN01: start 0, 1 bit, little-endian, data-type-policy=OVERRIDE, i-signal-type=PRIMITIVE, init-value=0, base-type=BT_BJB_CVN_VLD, compu {0=Cx0_Ungueltig (CM_BJB_CVN_VLD_Cx0_Ungueltig), 1=Cx1_Gueltig (CM_BJB_CVN_VLD_Cx1_Gueltig)}, range raw 0..1, transfer-property=PENDING, to BMC_HV(timeout 5 s)  # Über dieses Signal wird gekennzeichnet, ob die Berechnung der CVN im SecondaryOBDECU abgeschlossen ist.
          signal BJB_CVN_Byte_1_XIX_BJB_CVN_01_XIX_BMC_CAN01: start 1, 8 bit, little-endian, data-type-policy=OVERRIDE, i-signal-type=PRIMITIVE, init-value=0, base-type=BT_BJB_CVN_Byte_1, compu {phys=raw for raw 0..255}, range phys 0..255, raw 0..255, transfer-property=PENDING, to BMC_HV(timeout 5 s)  # Calibration Verification Number
          signal BJB_CVN_Byte_2_XIX_BJB_CVN_01_XIX_BMC_CAN01: start 9, 8 bit, little-endian, data-type-policy=OVERRIDE, i-signal-type=PRIMITIVE, init-value=0, base-type=BT_BJB_CVN_Byte_2, compu {phys=raw for raw 0..255}, range phys 0..255, raw 0..255, transfer-property=PENDING, to BMC_HV(timeout 5 s)  # Calibration Verification Number
          signal BJB_CVN_Byte_3_XIX_BJB_CVN_01_XIX_BMC_CAN01: start 17, 8 bit, little-endian, data-type-policy=OVERRIDE, i-signal-type=PRIMITIVE, init-value=0, base-type=BT_BJB_CVN_Byte_3, compu {phys=raw for raw 0..255}, range phys 0..255, raw 0..255, transfer-property=PENDING, to BMC_HV(timeout 5 s)  # Calibration Verification Number
          signal BJB_CVN_Byte_4_XIX_BJB_CVN_01_XIX_BMC_CAN01: start 25, 8 bit, little-endian, data-type-policy=OVERRIDE, i-signal-type=PRIMITIVE, init-value=0, base-type=BT_BJB_CVN_Byte_4, compu {phys=raw for raw 0..255}, range phys 0..255, raw 0..255, transfer-property=PENDING, to BMC_HV(timeout 5 s)  # Calibration Verification Number
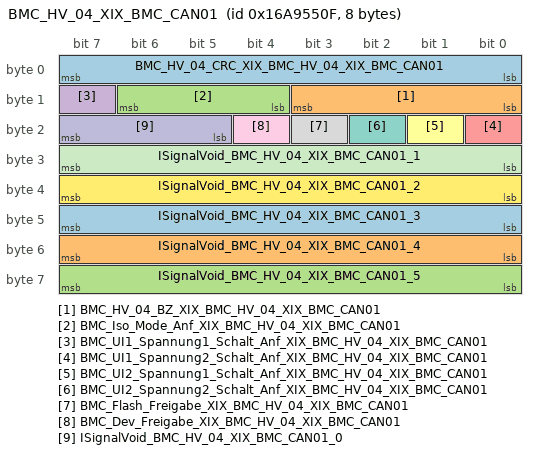
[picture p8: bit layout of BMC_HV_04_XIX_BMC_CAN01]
      frame BMC_HV_04_XIX_BMC_CAN01: id 0x16A9550F, from BMC_HV, frame-length=8, can-addressing-mode=EXTENDED, can-frame-rx-behavior=CAN-20, can-frame-tx-behavior=CAN-20
        pdu BMC_HV_04_XIX_BMC_CAN01_E2E: length=8, minimum-delay=0.05, transmission-mode-true-timing=event-controlled-timing={number-of-repetitions=0, repetition-period=0}, unused-bit-pattern=0  # Fuer die Botschaft ist das Cyclic-Timing 1.0 zu verwenden.
          signal BMC_HV_04_CRC_XIX_BMC_HV_04_XIX_BMC_CAN01: start 0, 8 bit, little-endian, data-type-policy=OVERRIDE, i-signal-type=PRIMITIVE, init-value=0, base-type=BT_BMC_HV_04_CRC, compu {phys=raw for raw 0..255}, range phys 0..255, raw 0..255
          signal BMC_HV_04_BZ_XIX_BMC_HV_04_XIX_BMC_CAN01: start 8, 4 bit, little-endian, data-type-policy=OVERRIDE, i-signal-type=PRIMITIVE, init-value=0, base-type=BT_BMC_HV_04_BZ, compu {phys=raw for raw 0..15}, range phys 0..15, raw 0..15
          signal BMC_Iso_Mode_Anf_XIX_BMC_HV_04_XIX_BMC_CAN01: start 12, 3 bit, little-endian, data-type-policy=OVERRIDE, i-signal-type=PRIMITIVE, init-value=0, base-type=BT_BMC_Iso_Mode_Anf, compu {0=Cx0_Init (CM_BMC_Iso_Mode_Anf_Cx0_Init), 1=Cx1_zyklisch_Zeit1 (CM_BMC_Iso_Mode_Anf_Cx1_zyklisch_Zeit1), 2=Cx2_zyklisch_Zeit2 (CM_BMC_Iso_Mode_Anf_Cx2_zyklisch_Zeit2), 3=Cx3_zyklisch_Zeit3 (CM_BMC_Iso_Mode_Anf_Cx3_zyklisch_Zeit3), 4=Cx4_Pause (CM_BMC_Iso_Mode_Anf_Cx4_Pause), 5=Cx5_Einzelmessung (CM_BMC_Iso_Mode_Anf_Cx5_Einzelmessung), 6=Cx6_Schnellmessung (CM_BMC_Iso_Mode_Anf_Cx6_Schnellmessung), 7=Cx7_Aus (CM_BMC_Iso_Mode_Anf_Cx7_Aus)}, range raw 0..7  # Anforderung Isolationsmessung an UI-Sensor
          signal BMC_UI1_Spannung1_Schalt_Anf_XIX_BMC_HV_04_XIX_BMC_CAN01: start 15, 1 bit, little-endian, data-type-policy=OVERRIDE, i-signal-type=PRIMITIVE, init-value=0, base-type=BT_BMC_UI1_Spannung1_Schalt_Anf, compu {0=Cx0_aus (CM_BMC_UI1_Spannung1_Schalt_Anf_Cx0_aus), 1=Cx1_ein (CM_BMC_UI1_Spannung1_Schalt_Anf_Cx1_ein)}, range raw 0..1  # Aktivierung des Spannungsmesskanals1
          signal BMC_UI1_Spannung2_Schalt_Anf_XIX_BMC_HV_04_XIX_BMC_CAN01: start 16, 1 bit, little-endian, data-type-policy=OVERRIDE, i-signal-type=PRIMITIVE, init-value=0, base-type=BT_BMC_UI1_Spannung2_Schalt_Anf, compu {0=Cx0_aus (CM_BMC_UI1_Spannung2_Schalt_Anf_Cx0_aus), 1=Cx1_ein (CM_BMC_UI1_Spannung2_Schalt_Anf_Cx1_ein)}, range raw 0..1  # Aktivierung des Spannungsmesskanals2
          signal BMC_UI2_Spannung1_Schalt_Anf_XIX_BMC_HV_04_XIX_BMC_CAN01: start 17, 1 bit, little-endian, data-type-policy=OVERRIDE, i-signal-type=PRIMITIVE, init-value=0, base-type=BT_BMC_UI2_Spannung1_Schalt_Anf, compu {0=Cx0_aus (CM_BMC_UI2_Spannung1_Schalt_Anf_Cx0_aus), 1=Cx1_ein (CM_BMC_UI2_Spannung1_Schalt_Anf_Cx1_ein)}, range raw 0..1  # Aktivierung des Spannungsmesskanals1
          signal BMC_UI2_Spannung2_Schalt_Anf_XIX_BMC_HV_04_XIX_BMC_CAN01: start 18, 1 bit, little-endian, data-type-policy=OVERRIDE, i-signal-type=PRIMITIVE, init-value=0, base-type=BT_BMC_UI2_Spannung2_Schalt_Anf, compu {0=Cx0_aus (CM_BMC_UI2_Spannung2_Schalt_Anf_Cx0_aus), 1=Cx1_ein (CM_BMC_UI2_Spannung2_Schalt_Anf_Cx1_ein)}, range raw 0..1  # Aktivierung des Spannungsmesskanals2
          signal BMC_Flash_Freigabe_XIX_BMC_HV_04_XIX_BMC_CAN01: start 19, 1 bit, little-endian, data-type-policy=OVERRIDE, i-signal-type=PRIMITIVE, init-value=0, base-type=BT_BMC_Flash_Freigabe, compu {0=Cx0_keine_Freigabe (CM_BMC_Flash_Freigabe_Cx0_keine_Freigabe), 1=Cx1_Freigabe (CM_BMC_Flash_Freigabe_Cx1_Freigabe)}, range raw 0..1
          signal BMC_Dev_Freigabe_XIX_BMC_HV_04_XIX_BMC_CAN01: start 20, 1 bit, little-endian, data-type-policy=OVERRIDE, i-signal-type=PRIMITIVE, init-value=0, base-type=BT_BMC_Dev_Freigabe, compu {0=Cx0_keine_Freigabe (CM_BMC_Dev_Freigabe_Cx0_keine_Freigabe), 1=Cx1_Freigabe (CM_BMC_Dev_Freigabe_Cx1_Freigabe)}, range raw 0..1  # Aktivierung der Entwicklerbotschaften von BMC Subkomponenten
          signal ISignalVoid_BMC_HV_04_XIX_BMC_CAN01_0: start 21, 3 bit, little-endian, system signal SignalVoid_BMC_HV_04_0, data-type-policy=OVERRIDE, i-signal-type=PRIMITIVE, base-type=BT_SignalVoid
          signal ISignalVoid_BMC_HV_04_XIX_BMC_CAN01_1: start 24, 8 bit, little-endian, system signal SignalVoid_BMC_HV_04_1, data-type-policy=OVERRIDE, i-signal-type=PRIMITIVE, base-type=BT_SignalVoid
          signal ISignalVoid_BMC_HV_04_XIX_BMC_CAN01_2: start 32, 8 bit, little-endian, system signal SignalVoid_BMC_HV_04_2, data-type-policy=OVERRIDE, i-signal-type=PRIMITIVE, base-type=BT_SignalVoid
          signal ISignalVoid_BMC_HV_04_XIX_BMC_CAN01_3: start 40, 8 bit, little-endian, system signal SignalVoid_BMC_HV_04_3, data-type-policy=OVERRIDE, i-signal-type=PRIMITIVE, base-type=BT_SignalVoid
          signal ISignalVoid_BMC_HV_04_XIX_BMC_CAN01_4: start 48, 8 bit, little-endian, system signal SignalVoid_BMC_HV_04_4, data-type-policy=OVERRIDE, i-signal-type=PRIMITIVE, base-type=BT_SignalVoid
          signal ISignalVoid_BMC_HV_04_XIX_BMC_CAN01_5: start 56, 8 bit, little-endian, system signal SignalVoid_BMC_HV_04_5, data-type-policy=OVERRIDE, i-signal-type=PRIMITIVE, base-type=BT_SignalVoid
          mapping SG_BMC_HV_04_XIX_BMC_CAN01: i-signal-group=SG_BMC_HV_04_XIX_BMC_CAN01, transfer-property=TRIGGERED-WITHOUT-REPETITION
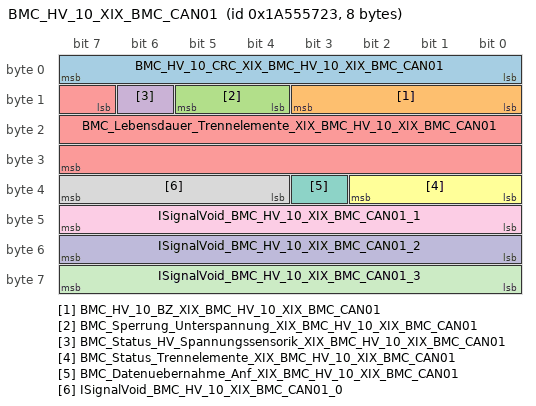
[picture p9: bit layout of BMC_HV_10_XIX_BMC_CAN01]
      frame BMC_HV_10_XIX_BMC_CAN01: id 0x1A555723, from BMC_HV, frame-length=8, can-addressing-mode=EXTENDED, can-frame-rx-behavior=CAN-20, can-frame-tx-behavior=CAN-20
        pdu BMC_HV_10_XIX_BMC_CAN01_E2E: length=8, transmission-mode-true-timing=event-controlled-timing={number-of-repetitions=0, repetition-period=0}, unused-bit-pattern=0  # Fuer die Botschaft ist das Cyclic-Timing 1.0 zu verwenden.
          signal BMC_HV_10_CRC_XIX_BMC_HV_10_XIX_BMC_CAN01: start 0, 8 bit, little-endian, data-type-policy=OVERRIDE, i-signal-type=PRIMITIVE, init-value=0, base-type=BT_BMC_HV_10_CRC
          signal BMC_HV_10_BZ_XIX_BMC_HV_10_XIX_BMC_CAN01: start 8, 4 bit, little-endian, data-type-policy=OVERRIDE, i-signal-type=PRIMITIVE, init-value=0, base-type=BT_BMC_HV_10_BZ
          signal BMC_Sperrung_Unterspannung_XIX_BMC_HV_10_XIX_BMC_CAN01: start 12, 2 bit, little-endian, data-type-policy=OVERRIDE, i-signal-type=PRIMITIVE, init-value=2, base-type=BT_BMC_Sperrung_Unterspannung, invalid-value=Invalid_BMC_Sperrung_Unterspannung_XIX_BMC_HV_10_XIX_BMC_CAN01:3, compu {0=Cx0_keine_Sperrung (CM_BMC_Sperrung_Unterspannung_Cx0_keine_Sperrung), 1=Cx1_Sperrung (CM_BMC_Sperrung_Unterspannung_Cx1_Sperrung), 2=Cx2_InitWert (CM_BMC_Sperrung_Unterspannung_Cx2_InitWert), 3=Cx3_Fehler (CM_BMC_Sperrung_Unterspannung_Cx3_Fehler)}, range raw 0..3  # Status Sperrung durch Unterspannung zum Datenaustausch für redundante Datenspeicherung
          signal BMC_Status_HV_Spannungssensorik_XIX_BMC_HV_10_XIX_BMC_CAN01: start 14, 1 bit, little-endian, data-type-policy=OVERRIDE, i-signal-type=PRIMITIVE, init-value=0, base-type=BT_BMC_Status_HV_Spannungssensorik, invalid-value=Invalid_BMC_Status_HV_Spannungssensorik_XIX_BMC_HV_10_XIX_BMC_CAN01:1, compu {0=Cx0_InitWert_kein_Fehler (CM_BMC_Status_HV_Spannungssensorik_Cx0_InitWert_kein_Fehler), 1=Cx1_Fehler (CM_BMC_Status_HV_Spannungssensorik_Cx1_Fehler)}, range raw 0..1  # Status HV Spannungssensorik zum Datenaustausch für redundante Datenspeicherung
          signal BMC_Lebensdauer_Trennelemente_XIX_BMC_HV_10_XIX_BMC_CAN01: start 15, 17 bit, little-endian, data-type-policy=OVERRIDE, i-signal-type=PRIMITIVE, init-value=131070, base-type=BT_BMC_Lebensdauer_Trennelemente, invalid-value=Invalid_BMC_Lebensdauer_Trennelemente_XIX_BMC_HV_10_XIX_BMC_CAN01:131071, compu {phys=raw for raw 0..100000, 131070=Cx1fffe_InitWert (CM_BMC_Lebensdauer_Trennelemente_Cx1fffe_InitWert), 131071=Cx1ffff_Fehler (CM_BMC_Lebensdauer_Trennelemente_Cx1ffff_Fehler); unit Unit_None}, range phys 0..100000 Unit_None, raw 0..131071, unit=Unit_None  # Lebensdauerzähler Trennelemente zum Datenaustausch für redundante Datenspeicherung
          signal BMC_Status_Trennelemente_XIX_BMC_HV_10_XIX_BMC_CAN01: start 32, 3 bit, little-endian, data-type-policy=OVERRIDE, i-signal-type=PRIMITIVE, init-value=6, base-type=BT_BMC_Status_Trennelemente, invalid-value=Invalid_BMC_Status_Trennelemente_XIX_BMC_HV_10_XIX_BMC_CAN01:7, compu {0=Cx0_kein_Fehler (CM_BMC_Status_Trennelemente_Cx0_kein_Fehler), 1=Cx1_Haupt_TrEl_klemmt_geschl (CM_BMC_Status_Trennelemente_Cx1_Haupt_TrEl_klemmt_geschl), 2=Cx2_AC_TrEl_klemmt_geschl (CM_BMC_Status_Trennelemente_Cx2_AC_TrEl_klemmt_geschl), 3=Cx3_Haupt_und_AC_TrEl_klemmt_geschl (CM_BMC_Status_Trennelemente_Cx3_Haupt_und_AC_TrEl_klemmt_geschl), 6=Cx6_InitWert (CM_BMC_Status_Trennelemente_Cx6_InitWert), 7=Cx7_Fehler (CM_BMC_Status_Trennelemente_Cx7_Fehler)}, range raw 0..7  # Status Trennelemente zum Datenaustausch für redundante Datenspeicherung
          signal BMC_Datenuebernahme_Anf_XIX_BMC_HV_10_XIX_BMC_CAN01: start 35, 1 bit, little-endian, data-type-policy=OVERRIDE, i-signal-type=PRIMITIVE, init-value=0, base-type=BT_BMC_Datenuebernahme_Anf, compu {0=Cx0_Daten_nicht_uebernehmen (CM_BMC_Datenuebernahme_Anf_Cx0_Daten_nicht_uebernehmen), 1=Cx1_Daten_uebernehmen (CM_BMC_Datenuebernahme_Anf_Cx1_Daten_uebernehmen)}, range raw 0..1  # Trigger zur Datenuebernahme für redundante Datenspeicherung
          signal ISignalVoid_BMC_HV_10_XIX_BMC_CAN01_0: start 36, 4 bit, little-endian, system signal SignalVoid_BMC_HV_10_0, data-type-policy=OVERRIDE, i-signal-type=PRIMITIVE, base-type=BT_SignalVoid
          signal ISignalVoid_BMC_HV_10_XIX_BMC_CAN01_1: start 40, 8 bit, little-endian, system signal SignalVoid_BMC_HV_10_1, data-type-policy=OVERRIDE, i-signal-type=PRIMITIVE, base-type=BT_SignalVoid
          signal ISignalVoid_BMC_HV_10_XIX_BMC_CAN01_2: start 48, 8 bit, little-endian, system signal SignalVoid_BMC_HV_10_2, data-type-policy=OVERRIDE, i-signal-type=PRIMITIVE, base-type=BT_SignalVoid
          signal ISignalVoid_BMC_HV_10_XIX_BMC_CAN01_3: start 56, 8 bit, little-endian, system signal SignalVoid_BMC_HV_10_3, data-type-policy=OVERRIDE, i-signal-type=PRIMITIVE, base-type=BT_SignalVoid
          mapping SG_BMC_HV_10_XIX_BMC_CAN01: i-signal-group=SG_BMC_HV_10_XIX_BMC_CAN01, transfer-property=TRIGGERED-WITHOUT-REPETITION
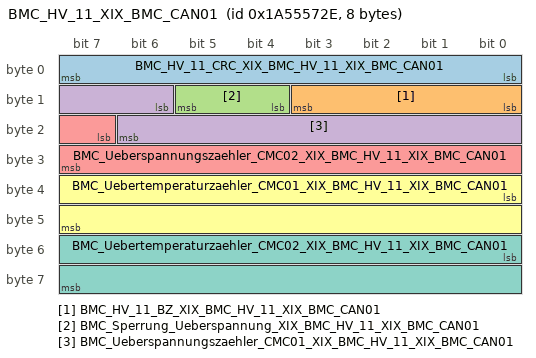
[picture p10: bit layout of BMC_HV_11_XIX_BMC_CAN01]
      frame BMC_HV_11_XIX_BMC_CAN01: id 0x1A55572E, from BMC_HV, frame-length=8, can-addressing-mode=EXTENDED, can-frame-rx-behavior=CAN-20, can-frame-tx-behavior=CAN-20
        pdu BMC_HV_11_XIX_BMC_CAN01_E2E: length=8, transmission-mode-true-timing=event-controlled-timing={number-of-repetitions=0, repetition-period=0}, unused-bit-pattern=0
          signal BMC_HV_11_CRC_XIX_BMC_HV_11_XIX_BMC_CAN01: start 0, 8 bit, little-endian, data-type-policy=OVERRIDE, i-signal-type=PRIMITIVE, init-value=0, base-type=BT_BMC_HV_11_CRC
          signal BMC_HV_11_BZ_XIX_BMC_HV_11_XIX_BMC_CAN01: start 8, 4 bit, little-endian, data-type-policy=OVERRIDE, i-signal-type=PRIMITIVE, init-value=0, base-type=BT_BMC_HV_11_BZ
          signal BMC_Sperrung_Ueberspannung_XIX_BMC_HV_11_XIX_BMC_CAN01: start 12, 2 bit, little-endian, data-type-policy=OVERRIDE, i-signal-type=PRIMITIVE, init-value=2, base-type=BT_BMC_Sperrung_Ueberspannung, invalid-value=Invalid_BMC_Sperrung_Ueberspannung_XIX_BMC_HV_11_XIX_BMC_CAN01:3, compu {0=Cx0_keine_Sperrung (CM_BMC_Sperrung_Ueberspannung_Cx0_keine_Sperrung), 1=Cx1_Sperrung (CM_BMC_Sperrung_Ueberspannung_Cx1_Sperrung), 2=Cx2_InitWert (CM_BMC_Sperrung_Ueberspannung_Cx2_InitWert), 3=Cx3_Fehler (CM_BMC_Sperrung_Ueberspannung_Cx3_Fehler)}, range raw 0..3  # Status Sperrung durch Ueberspannung zum Datenaustausch für redundante Datenspeicherung
          signal BMC_Ueberspannungszaehler_CMC01_XIX_BMC_HV_11_XIX_BMC_CAN01: start 14, 9 bit, little-endian, data-type-policy=OVERRIDE, i-signal-type=PRIMITIVE, init-value=510, base-type=BT_BMC_Ueberspannungszaehler_CMC01, invalid-value=Invalid_BMC_Ueberspannungszaehler_CMC01_XIX_BMC_HV_11_XIX_BMC_CAN01:511, compu {phys=raw for raw 0..400, 510=Cx1fe_InitWert (CM_BMC_Ueberspannungszaehler_CMC01_Cx1fe_InitWert), 511=Cx1ff_Fehler (CM_BMC_Ueberspannungszaehler_CMC01_Cx1ff_Fehler); unit Unit_None}, range phys 0..400 Unit_None, raw 0..511, unit=Unit_None  # Überspannungszähler zum Datenaustausch für redundante Datenspeicherung
          signal BMC_Ueberspannungszaehler_CMC02_XIX_BMC_HV_11_XIX_BMC_CAN01: start 23, 9 bit, little-endian, data-type-policy=OVERRIDE, i-signal-type=PRIMITIVE, init-value=510, base-type=BT_BMC_Ueberspannungszaehler_CMC02, invalid-value=Invalid_BMC_Ueberspannungszaehler_CMC02_XIX_BMC_HV_11_XIX_BMC_CAN01:511, compu {phys=raw for raw 0..400, 510=Cx1fe_InitWert (CM_BMC_Ueberspannungszaehler_CMC02_Cx1fe_InitWert), 511=Cx1ff_Fehler (CM_BMC_Ueberspannungszaehler_CMC02_Cx1ff_Fehler); unit Unit_None}, range phys 0..400 Unit_None, raw 0..511, unit=Unit_None  # Überspannungszähler zum Datenaustausch für redundante Datenspeicherung
          signal BMC_Uebertemperaturzaehler_CMC01_XIX_BMC_HV_11_XIX_BMC_CAN01: start 32, 16 bit, little-endian, data-type-policy=OVERRIDE, i-signal-type=PRIMITIVE, init-value=65534, base-type=BT_BMC_Uebertemperaturzaehler_CMC01, invalid-value=Invalid_BMC_Uebertemperaturzaehler_CMC01_XIX_BMC_HV_11_XIX_BMC_CAN01:65535, compu {phys=raw*10 for raw 0..60480, 65534=Cxfffe_InitWert (CM_BMC_Uebertemperaturzaehler_CMC01_Cxfffe_InitWert), 65535=Cxffff_Fehler (CM_BMC_Uebertemperaturzaehler_CMC01_Cxffff_Fehler); unit Unit_None}, range phys 0..604800 Unit_None, raw 0..65535, unit=Unit_None  # Übertemperaturzähler zum Datenaustausch für redundante Datenspeicherung
          signal BMC_Uebertemperaturzaehler_CMC02_XIX_BMC_HV_11_XIX_BMC_CAN01: start 48, 16 bit, little-endian, data-type-policy=OVERRIDE, i-signal-type=PRIMITIVE, init-value=65534, base-type=BT_BMC_Uebertemperaturzaehler_CMC02, invalid-value=Invalid_BMC_Uebertemperaturzaehler_CMC02_XIX_BMC_HV_11_XIX_BMC_CAN01:65535, compu {phys=raw*10 for raw 0..60480, 65534=Cxfffe_InitWert (CM_BMC_Uebertemperaturzaehler_CMC02_Cxfffe_InitWert), 65535=Cxffff_Fehler (CM_BMC_Uebertemperaturzaehler_CMC02_Cxffff_Fehler); unit Unit_None}, range phys 0..604800 Unit_None, raw 0..65535, unit=Unit_None  # Übertemperaturzähler zum Datenaustausch für redundante Datenspeicherung
          mapping SG_BMC_HV_11_XIX_BMC_CAN01: i-signal-group=SG_BMC_HV_11_XIX_BMC_CAN01, transfer-property=TRIGGERED-WITHOUT-REPETITION
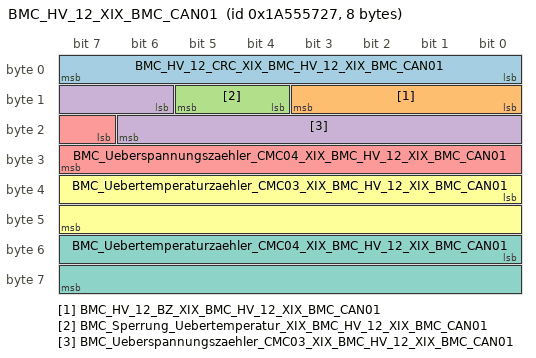
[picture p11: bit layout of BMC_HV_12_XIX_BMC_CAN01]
      frame BMC_HV_12_XIX_BMC_CAN01: id 0x1A555727, from BMC_HV, frame-length=8, can-addressing-mode=EXTENDED, can-frame-rx-behavior=CAN-20, can-frame-tx-behavior=CAN-20
        pdu BMC_HV_12_XIX_BMC_CAN01_E2E: length=8, transmission-mode-true-timing=event-controlled-timing={number-of-repetitions=0, repetition-period=0}, unused-bit-pattern=0
          signal BMC_HV_12_CRC_XIX_BMC_HV_12_XIX_BMC_CAN01: start 0, 8 bit, little-endian, data-type-policy=OVERRIDE, i-signal-type=PRIMITIVE, init-value=0, base-type=BT_BMC_HV_12_CRC
          signal BMC_HV_12_BZ_XIX_BMC_HV_12_XIX_BMC_CAN01: start 8, 4 bit, little-endian, data-type-policy=OVERRIDE, i-signal-type=PRIMITIVE, init-value=0, base-type=BT_BMC_HV_12_BZ
          signal BMC_Sperrung_Uebertemperatur_XIX_BMC_HV_12_XIX_BMC_CAN01: start 12, 2 bit, little-endian, data-type-policy=OVERRIDE, i-signal-type=PRIMITIVE, init-value=2, base-type=BT_BMC_Sperrung_Uebertemperatur, invalid-value=Invalid_BMC_Sperrung_Uebertemperatur_XIX_BMC_HV_12_XIX_BMC_CAN01:3, compu {0=Cx0_keine_Sperrung (CM_BMC_Sperrung_Uebertemperatur_Cx0_keine_Sperrung), 1=Cx1_Sperrung (CM_BMC_Sperrung_Uebertemperatur_Cx1_Sperrung), 2=Cx2_InitWert (CM_BMC_Sperrung_Uebertemperatur_Cx2_InitWert), 3=Cx3_Fehler (CM_BMC_Sperrung_Uebertemperatur_Cx3_Fehler)}, range raw 0..3  # Status Sperrung durch Uebertemperatur zum Datenaustausch für redundante Datenspeicherung
          signal BMC_Ueberspannungszaehler_CMC03_XIX_BMC_HV_12_XIX_BMC_CAN01: start 14, 9 bit, little-endian, data-type-policy=OVERRIDE, i-signal-type=PRIMITIVE, init-value=510, base-type=BT_BMC_Ueberspannungszaehler_CMC03, invalid-value=Invalid_BMC_Ueberspannungszaehler_CMC03_XIX_BMC_HV_12_XIX_BMC_CAN01:511, compu {phys=raw for raw 0..400, 510=Cx1fe_InitWert (CM_BMC_Ueberspannungszaehler_CMC03_Cx1fe_InitWert), 511=Cx1ff_Fehler (CM_BMC_Ueberspannungszaehler_CMC03_Cx1ff_Fehler); unit Unit_None}, range phys 0..400 Unit_None, raw 0..511, unit=Unit_None  # Überspannungszähler zum Datenaustausch für redundante Datenspeicherung
          signal BMC_Ueberspannungszaehler_CMC04_XIX_BMC_HV_12_XIX_BMC_CAN01: start 23, 9 bit, little-endian, data-type-policy=OVERRIDE, i-signal-type=PRIMITIVE, init-value=510, base-type=BT_BMC_Ueberspannungszaehler_CMC04, invalid-value=Invalid_BMC_Ueberspannungszaehler_CMC04_XIX_BMC_HV_12_XIX_BMC_CAN01:511, compu {phys=raw for raw 0..400, 510=Cx1fe_InitWert (CM_BMC_Ueberspannungszaehler_CMC04_Cx1fe_InitWert), 511=Cx1ff_Fehler (CM_BMC_Ueberspannungszaehler_CMC04_Cx1ff_Fehler); unit Unit_None}, range phys 0..400 Unit_None, raw 0..511, unit=Unit_None  # Überspannungszähler zum Datenaustausch für redundante Datenspeicherung
          signal BMC_Uebertemperaturzaehler_CMC03_XIX_BMC_HV_12_XIX_BMC_CAN01: start 32, 16 bit, little-endian, data-type-policy=OVERRIDE, i-signal-type=PRIMITIVE, init-value=65534, base-type=BT_BMC_Uebertemperaturzaehler_CMC03, invalid-value=Invalid_BMC_Uebertemperaturzaehler_CMC03_XIX_BMC_HV_12_XIX_BMC_CAN01:65535, compu {phys=raw*10 for raw 0..60480, 65534=Cxfffe_InitWert (CM_BMC_Uebertemperaturzaehler_CMC03_Cxfffe_InitWert), 65535=Cxffff_Fehler (CM_BMC_Uebertemperaturzaehler_CMC03_Cxffff_Fehler); unit Unit_Ohm}, range phys 0..604800 Unit_Ohm, raw 0..65535, unit=Unit_Ohm  # Übertemperaturzähler zum Datenaustausch für redundante Datenspeicherung
          signal BMC_Uebertemperaturzaehler_CMC04_XIX_BMC_HV_12_XIX_BMC_CAN01: start 48, 16 bit, little-endian, data-type-policy=OVERRIDE, i-signal-type=PRIMITIVE, init-value=65534, base-type=BT_BMC_Uebertemperaturzaehler_CMC04, invalid-value=Invalid_BMC_Uebertemperaturzaehler_CMC04_XIX_BMC_HV_12_XIX_BMC_CAN01:65535, compu {phys=raw*10 for raw 0..60480, 65534=Cxfffe_InitWert (CM_BMC_Uebertemperaturzaehler_CMC04_Cxfffe_InitWert), 65535=Cxffff_Fehler (CM_BMC_Uebertemperaturzaehler_CMC04_Cxffff_Fehler); unit Unit_None}, range phys 0..604800 Unit_None, raw 0..65535, unit=Unit_None  # Übertemperaturzähler zum Datenaustausch für redundante Datenspeicherung
          mapping SG_BMC_HV_12_XIX_BMC_CAN01: i-signal-group=SG_BMC_HV_12_XIX_BMC_CAN01, transfer-property=TRIGGERED-WITHOUT-REPETITION
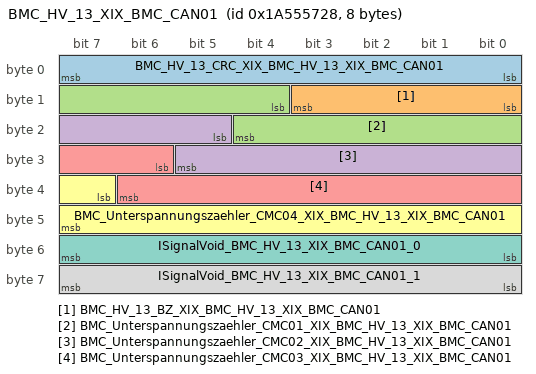
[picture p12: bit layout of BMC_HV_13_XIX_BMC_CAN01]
      frame BMC_HV_13_XIX_BMC_CAN01: id 0x1A555728, from BMC_HV, frame-length=8, can-addressing-mode=EXTENDED, can-frame-rx-behavior=CAN-20, can-frame-tx-behavior=CAN-20
        pdu BMC_HV_13_XIX_BMC_CAN01_E2E: length=8, transmission-mode-true-timing=event-controlled-timing={number-of-repetitions=0, repetition-period=0}, unused-bit-pattern=0
          signal BMC_HV_13_CRC_XIX_BMC_HV_13_XIX_BMC_CAN01: start 0, 8 bit, little-endian, data-type-policy=OVERRIDE, i-signal-type=PRIMITIVE, init-value=0, base-type=BT_BMC_HV_13_CRC
          signal BMC_HV_13_BZ_XIX_BMC_HV_13_XIX_BMC_CAN01: start 8, 4 bit, little-endian, data-type-policy=OVERRIDE, i-signal-type=PRIMITIVE, init-value=0, base-type=BT_BMC_HV_13_BZ
          signal BMC_Unterspannungszaehler_CMC01_XIX_BMC_HV_13_XIX_BMC_CAN01: start 12, 9 bit, little-endian, data-type-policy=OVERRIDE, i-signal-type=PRIMITIVE, init-value=510, base-type=BT_BMC_Unterspannungszaehler_CMC01, invalid-value=Invalid_BMC_Unterspannungszaehler_CMC01_XIX_BMC_HV_13_XIX_BMC_CAN01:511, compu {phys=raw for raw 0..400, 510=Cx1fe_InitWert (CM_BMC_Unterspannungszaehler_CMC01_Cx1fe_InitWert), 511=Cx1ff_Fehler (CM_BMC_Unterspannungszaehler_CMC01_Cx1ff_Fehler); unit Unit_None}, range phys 0..400 Unit_None, raw 0..511, unit=Unit_None  # Unterspannungszähler zum Datenaustausch für redundante Datenspeicherung
          signal BMC_Unterspannungszaehler_CMC02_XIX_BMC_HV_13_XIX_BMC_CAN01: start 21, 9 bit, little-endian, data-type-policy=OVERRIDE, i-signal-type=PRIMITIVE, init-value=510, base-type=BT_BMC_Unterspannungszaehler_CMC02, invalid-value=Invalid_BMC_Unterspannungszaehler_CMC02_XIX_BMC_HV_13_XIX_BMC_CAN01:511, compu {phys=raw for raw 0..400, 510=Cx1fe_InitWert (CM_BMC_Unterspannungszaehler_CMC02_Cx1fe_InitWert), 511=Cx1ff_Fehler (CM_BMC_Unterspannungszaehler_CMC02_Cx1ff_Fehler); unit Unit_None}, range phys 0..400 Unit_None, raw 0..511, unit=Unit_None  # Unterspannungszähler zum Datenaustausch für redundante Datenspeicherung
          signal BMC_Unterspannungszaehler_CMC03_XIX_BMC_HV_13_XIX_BMC_CAN01: start 30, 9 bit, little-endian, data-type-policy=OVERRIDE, i-signal-type=PRIMITIVE, init-value=510, base-type=BT_BMC_Unterspannungszaehler_CMC03, invalid-value=Invalid_BMC_Unterspannungszaehler_CMC03_XIX_BMC_HV_13_XIX_BMC_CAN01:511, compu {phys=raw for raw 0..400, 510=Cx1fe_InitWert (CM_BMC_Unterspannungszaehler_CMC03_Cx1fe_InitWert), 511=Cx1ff_Fehler (CM_BMC_Unterspannungszaehler_CMC03_Cx1ff_Fehler); unit Unit_None}, range phys 0..400 Unit_None, raw 0..511, unit=Unit_None  # Unterspannungszähler zum Datenaustausch für redundante Datenspeicherung
          signal BMC_Unterspannungszaehler_CMC04_XIX_BMC_HV_13_XIX_BMC_CAN01: start 39, 9 bit, little-endian, data-type-policy=OVERRIDE, i-signal-type=PRIMITIVE, init-value=510, base-type=BT_BMC_Unterspannungszaehler_CMC04, invalid-value=Invalid_BMC_Unterspannungszaehler_CMC04_XIX_BMC_HV_13_XIX_BMC_CAN01:511, compu {phys=raw for raw 0..400, 510=Cx1fe_InitWert (CM_BMC_Unterspannungszaehler_CMC04_Cx1fe_InitWert), 511=Cx1ff_Fehler (CM_BMC_Unterspannungszaehler_CMC04_Cx1ff_Fehler); unit Unit_None}, range phys 0..400 Unit_None, raw 0..511, unit=Unit_None  # Unterspannungszähler zum Datenaustausch für redundante Datenspeicherung
          signal ISignalVoid_BMC_HV_13_XIX_BMC_CAN01_0: start 48, 8 bit, little-endian, system signal SignalVoid_BMC_HV_13_0, data-type-policy=OVERRIDE, i-signal-type=PRIMITIVE, base-type=BT_SignalVoid
          signal ISignalVoid_BMC_HV_13_XIX_BMC_CAN01_1: start 56, 8 bit, little-endian, system signal SignalVoid_BMC_HV_13_1, data-type-policy=OVERRIDE, i-signal-type=PRIMITIVE, base-type=BT_SignalVoid
          mapping SG_BMC_HV_13_XIX_BMC_CAN01: i-signal-group=SG_BMC_HV_13_XIX_BMC_CAN01, transfer-property=TRIGGERED-WITHOUT-REPETITION
      frame ClampControl_01_XIX_BMC_CAN01: id 0x12DD54FE, from BMC_HV, frame-length=8, can-addressing-mode=EXTENDED, can-frame-rx-behavior=CAN-20, can-frame-tx-behavior=CAN-20
        pdu ClampControl_01_XIX_BMC_CAN01: length=8, minimum-delay=0.01, transmission-mode-true-timing={cyclic-timing={time-offset=0, time-period=0.1}, event-controlled-timing={number-of-repetitions=0, repetition-period=0}}, unused-bit-pattern=0
          signal ClampControl_01_CRC_XIX_ClampControl_01_XIX_BMC_CAN01: start 0, 8 bit, little-endian, data-type-policy=OVERRIDE, i-signal-type=PRIMITIVE, init-value=0, base-type=BT_ClampControl_01_CRC, compu {phys=raw for raw 0..255}, range phys 0..255, raw 0..255, transfer-property=PENDING  # Für MLB: Berechnung siehe Lastenheft "Kommunikationsabsicherung für FlexRay und CAN" Ab MQB und MLBevo: Berechnung siehe Lastenheft "End-to-End Kommunikationsabsicherung" Endwerte siehe Begleitdokument "S-PDU Kennungsfolgen"
          signal ClampControl_01_BZ_XIX_ClampControl_01_XIX_BMC_CAN01: start 8, 4 bit, little-endian, data-type-policy=OVERRIDE, i-signal-type=PRIMITIVE, init-value=0, base-type=BT_ClampControl_01_BZ, compu {phys=raw for raw 0..15}, range phys 0..15, raw 0..15, transfer-property=PENDING  # 4bit Botschaftszähler, wird mit jeder Sendebotschaft inkrementiert
          signal KST_Warn_P1_ZAT_def_XIX_ClampControl_01_XIX_BMC_CAN01: start 12, 1 bit, little-endian, data-type-policy=OVERRIDE, i-signal-type=PRIMITIVE, init-value=0, base-type=BT_KST_Warn_P1_ZAT_def, compu {0=Cx0_nicht_defekt (CM_KST_Warn_P1_ZAT_def_Cx0_nicht_defekt), 1=Cx1_defekt (CM_KST_Warn_P1_ZAT_def_Cx1_defekt)}, range raw 0..1, transfer-property=TRIGGERED-ON-CHANGE-WITHOUT-REPETITION  # Kombi Prio Warnung Klemmensteuerung Zündschloß defekt, Service aufsuchen!
          signal KST_Warn_P2_ZAT_def_XIX_ClampControl_01_XIX_BMC_CAN01: start 13, 1 bit, little-endian, data-type-policy=OVERRIDE, i-signal-type=PRIMITIVE, init-value=0, base-type=BT_KST_Warn_P2_ZAT_def, compu {0=Cx0_nicht_defekt (CM_KST_Warn_P2_ZAT_def_Cx0_nicht_defekt), 1=Cx1_defekt (CM_KST_Warn_P2_ZAT_def_Cx1_defekt)}, range raw 0..1, transfer-property=TRIGGERED-ON-CHANGE-WITHOUT-REPETITION  # Kombi Prio Warnung Klemmensteuerung Zündschloß defekt!
          signal KST_Deaktivierungs_Trigger_XIX_ClampControl_01_XIX_BMC_CAN01: start 14, 2 bit, little-endian, data-type-policy=OVERRIDE, i-signal-type=PRIMITIVE, init-value=0, base-type=BT_KST_Deaktivierungs_Trigger, compu {0=Cx0_KEINE_DEAKTIVIERUNG_ERFOLGT_0 (CM_KST_Deaktivierungs_Trigger_Cx0_KEINE_DEAKTIVIERUNG_ERFOLGT_0), 1=Cx1_DEAKTIVIERUNG_UEBER_ZAT_1 (CM_KST_Deaktivierungs_Trigger_Cx1_DEAKTIVIERUNG_UEBER_ZAT_1), 2=Cx2_DEAKTIVIERUNG_VEREINFACHT_VLK_2 (CM_KST_Deaktivierungs_Trigger_Cx2_DEAKTIVIERUNG_VEREINFACHT_VLK_2)}, range raw 0..2, transfer-property=TRIGGERED-ON-CHANGE-WITHOUT-REPETITION  # Ausgabe des Deaktivierungstriggers für Funktionen mit Goodbye-Szenario zur Unterscheidung zwischen manueller und automatischer Deaktivierung bei Fzg.-Verlassen
          signal KST_Kl_S_XIX_ClampControl_01_XIX_BMC_CAN01: start 16, 1 bit, little-endian, data-type-policy=OVERRIDE, i-signal-type=PRIMITIVE, init-value=0, base-type=BT_KST_Kl_S, compu {0=Cx0_aus (CM_KST_Kl_S_Cx0_aus), 1=Cx1_S_Kontakt_ein (CM_KST_Kl_S_Cx1_S_Kontakt_ein)}, range raw 0..1, transfer-property=TRIGGERED-ON-CHANGE-WITHOUT-REPETITION  # Klemme S: S-Kontakt (Schluessel steckt)
          signal KST_KL_15_XIX_ClampControl_01_XIX_BMC_CAN01: start 17, 1 bit, little-endian, data-type-policy=OVERRIDE, i-signal-type=PRIMITIVE, init-value=0, base-type=BT_KST_KL_15, compu {0=Cx0_aus (CM_KST_KL_15_Cx0_aus), 1=Cx1_ein (CM_KST_KL_15_Cx1_ein)}, range raw 0..1, transfer-property=TRIGGERED-ON-CHANGE-WITHOUT-REPETITION  # Klemme 15: Zuendung (SW-Kl.15)
          signal KST_Kl_50_Startanforderung_XIX_ClampControl_01_XIX_BMC_CAN01: start 18, 1 bit, little-endian, data-type-policy=OVERRIDE, i-signal-type=PRIMITIVE, init-value=0, base-type=BT_KST_Kl_50_Startanforderung, compu {0=Cx0_aus (CM_KST_Kl_50_Startanforderung_Cx0_aus), 1=Cx1_KL50_ein_Startwunsch_Fahrer (CM_KST_Kl_50_Startanforderung_Cx1_KL50_ein_Startwunsch_Fahrer)}, range raw 0..1, transfer-property=TRIGGERED-ON-CHANGE-WITHOUT-REPETITION  # Klemme 50: Startwunsch Fahrer
          signal KST_Sonderzustand_Status_XIX_ClampControl_01_XIX_BMC_CAN01: start 19, 2 bit, little-endian, data-type-policy=OVERRIDE, i-signal-type=PRIMITIVE, init-value=0, base-type=BT_KST_Sonderzustand_Status, invalid-value=Invalid_KST_Sonderzustand_Status_XIX_ClampControl_01_XIX_BMC_CAN01:3, compu {0=Cx0_Init (CM_KST_Sonderzustand_Status_Cx0_Init), 1=Cx1_Uebergang_neue_Anforderung (CM_KST_Sonderzustand_Status_Cx1_Uebergang_neue_Anforderung), 2=Cx2_Aktiv (CM_KST_Sonderzustand_Status_Cx2_Aktiv), 3=Cx3_Fehler (CM_KST_Sonderzustand_Status_Cx3_Fehler)}, range raw 0..3, transfer-property=TRIGGERED-ON-CHANGE-WITHOUT-REPETITION  # Hiermit wird signalisiert, dass eine Sonderfunktion aktiv ist und die Klemme 15 durch diese angefordert wurde bzw. ein Übergang von Sonderfunktionen stattfindet
          signal KST_Ausstiegswunsch_Status_XIX_ClampControl_01_XIX_BMC_CAN01: start 21, 1 bit, little-endian, data-type-policy=OVERRIDE, i-signal-type=PRIMITIVE, init-value=0, base-type=BT_KST_Ausstiegswunsch_Status, compu {0=Cx0_KEIN_AUSSTIEGSWUNSCH_AKTIV_0 (CM_KST_Ausstiegswunsch_Status_Cx0_KEIN_AUSSTIEGSWUNSCH_AKTIV_0), 1=Cx1_AUSSTIEGSWUNSCH_AKTIV_1 (CM_KST_Ausstiegswunsch_Status_Cx1_AUSSTIEGSWUNSCH_AKTIV_1)}, range raw 0..1, transfer-property=TRIGGERED-ON-CHANGE-WITHOUT-REPETITION  # Ausstiegswunsch über den Funktionen mit Goodbye-Szenario zentral getriggert werden können.
          signal KST_BulbCheckReq_XIX_ClampControl_01_XIX_BMC_CAN01: start 23, 1 bit, little-endian, data-type-policy=OVERRIDE, i-signal-type=PRIMITIVE, init-value=0, base-type=BT_KST_BulbCheckReq, compu {0=Cx0_Keine_Anfrage (CM_KST_BulbCheckReq_Cx0_Keine_Anfrage), 1=Cx1_Anfrage (CM_KST_BulbCheckReq_Cx1_Anfrage)}, range raw 0..1, transfer-property=TRIGGERED-ON-CHANGE-WITHOUT-REPETITION  # Signal fordert eine Lampenaufprüfung (Bulb Check) an.
          signal KST_Kl_X_XIX_ClampControl_01_XIX_BMC_CAN01: start 24, 1 bit, little-endian, data-type-policy=OVERRIDE, i-signal-type=PRIMITIVE, init-value=0, base-type=BT_KST_Kl_X, compu {0=Cx0_aus (CM_KST_Kl_X_Cx0_aus), 1=Cx1_ein (CM_KST_Kl_X_Cx1_ein)}, range raw 0..1, transfer-property=TRIGGERED-ON-CHANGE-WITHOUT-REPETITION  # Ausgabe der Klemme 75 aus Kompatibilitätsgründen für COP-Übernahmen aus MEB.
          signal KST_Ausparken_Betrieb_XIX_ClampControl_01_XIX_BMC_CAN01: start 25, 1 bit, little-endian, data-type-policy=OVERRIDE, i-signal-type=PRIMITIVE, init-value=0, base-type=BT_KST_Ausparken_Betrieb, compu {0=Cx0_kein_Betrieb (CM_KST_Ausparken_Betrieb_Cx0_kein_Betrieb), 1=Cx1_Ausparkvorgang_aktiv (CM_KST_Ausparken_Betrieb_Cx1_Ausparkvorgang_aktiv)}, range raw 0..1, transfer-property=TRIGGERED-ON-CHANGE-WITHOUT-REPETITION  # Anforderung zur erneuten Lampenaufprüfung und Anzeige von Warnhinweisen nach einem pilotierten Ausparkvorgang (Trigger: fallende Flanke)
          signal KST_Fahrerhinweis_1_XIX_ClampControl_01_XIX_BMC_CAN01: start 26, 1 bit, little-endian, data-type-policy=OVERRIDE, i-signal-type=PRIMITIVE, init-value=0, base-type=BT_KST_Fahrerhinweis_1, compu {0=Cx0_inaktiv (CM_KST_Fahrerhinweis_1_Cx0_inaktiv), 1=Cx1_aktiv (CM_KST_Fahrerhinweis_1_Cx1_aktiv)}, range raw 0..1, transfer-property=TRIGGERED-ON-CHANGE-WITHOUT-REPETITION  # Signalisierung Fahrerhinweis 1 der Klemmensteuerung an das Kombi
          signal KST_Fahrerhinweis_2_XIX_ClampControl_01_XIX_BMC_CAN01: start 27, 1 bit, little-endian, data-type-policy=OVERRIDE, i-signal-type=PRIMITIVE, init-value=0, base-type=BT_KST_Fahrerhinweis_2, compu {0=Cx0_inaktiv (CM_KST_Fahrerhinweis_2_Cx0_inaktiv), 1=Cx1_aktiv (CM_KST_Fahrerhinweis_2_Cx1_aktiv)}, range raw 0..1, transfer-property=TRIGGERED-ON-CHANGE-WITHOUT-REPETITION  # Signalisierung Fahrerhinweis 2 der Klemmensteuerung an das Kombi
          signal KST_Fahrerhinweis_3_XIX_ClampControl_01_XIX_BMC_CAN01: start 28, 1 bit, little-endian, data-type-policy=OVERRIDE, i-signal-type=PRIMITIVE, init-value=0, base-type=BT_KST_Fahrerhinweis_3, compu {0=Cx0_inaktiv (CM_KST_Fahrerhinweis_3_Cx0_inaktiv), 1=Cx1_aktiv (CM_KST_Fahrerhinweis_3_Cx1_aktiv)}, range raw 0..1, transfer-property=TRIGGERED-ON-CHANGE-WITHOUT-REPETITION  # Signalisierung Fahrerhinweis 3 der Klemmensteuerung an das Kombi
          signal KST_Fahrerhinweis_4_XIX_ClampControl_01_XIX_BMC_CAN01: start 29, 1 bit, little-endian, data-type-policy=OVERRIDE, i-signal-type=PRIMITIVE, init-value=0, base-type=BT_KST_Fahrerhinweis_4, compu {0=Cx0_inaktiv (CM_KST_Fahrerhinweis_4_Cx0_inaktiv), 1=Cx1_aktiv (CM_KST_Fahrerhinweis_4_Cx1_aktiv)}, range raw 0..1, transfer-property=TRIGGERED-ON-CHANGE-WITHOUT-REPETITION  # Signalisierung Fahrerhinweis 4 der Klemmensteuerung an das Kombi
          signal KST_Fahrerhinweis_5_XIX_ClampControl_01_XIX_BMC_CAN01: start 30, 1 bit, little-endian, data-type-policy=OVERRIDE, i-signal-type=PRIMITIVE, init-value=0, base-type=BT_KST_Fahrerhinweis_5, compu {0=Cx0_inaktiv (CM_KST_Fahrerhinweis_5_Cx0_inaktiv), 1=Cx1_aktiv (CM_KST_Fahrerhinweis_5_Cx1_aktiv)}, range raw 0..1, transfer-property=TRIGGERED-ON-CHANGE-WITHOUT-REPETITION  # Anzeigesignal für RemoteStart
          signal KST_Fahrerhinweis_6_XIX_ClampControl_01_XIX_BMC_CAN01: start 31, 1 bit, little-endian, data-type-policy=OVERRIDE, i-signal-type=PRIMITIVE, init-value=0, base-type=BT_KST_Fahrerhinweis_6, compu {0=Cx0_inaktiv (CM_KST_Fahrerhinweis_6_Cx0_inaktiv), 1=Cx1_aktiv (CM_KST_Fahrerhinweis_6_Cx1_aktiv)}, range raw 0..1, transfer-property=TRIGGERED-ON-CHANGE-WITHOUT-REPETITION  # Signal aktiviert die Kombi-Anzeigeinstrumente (Drehzahl, Tankinhalt, Kühlmitteltemperatur) während aktiviertem RemoteStart-Betrieb
          signal KST_Txt_Panikabschaltung_XIX_ClampControl_01_XIX_BMC_CAN01: start 34, 1 bit, little-endian, data-type-policy=OVERRIDE, i-signal-type=PRIMITIVE, init-value=0, base-type=BT_KST_Txt_Panikabschaltung, compu {0=Cx0_Aus (CM_KST_Txt_Panikabschaltung_Cx0_Aus), 1=Cx1_Ein (CM_KST_Txt_Panikabschaltung_Cx1_Ein)}, range raw 0..1, transfer-property=TRIGGERED-ON-CHANGE-WITHOUT-REPETITION  # Text: 'Notabschaltung''
          signal KST_Anf_Klemmenfreigabe_ELV_XIX_ClampControl_01_XIX_BMC_CAN01: start 41, 1 bit, little-endian, data-type-policy=OVERRIDE, i-signal-type=PRIMITIVE, init-value=0, base-type=BT_KST_Anf_Klemmenfreigabe_ELV, compu {0=Cx0_nicht_angefordert (CM_KST_Anf_Klemmenfreigabe_ELV_Cx0_nicht_angefordert), 1=Cx1_angefordert (CM_KST_Anf_Klemmenfreigabe_ELV_Cx1_angefordert)}, range raw 0..1, transfer-property=PENDING  # Klemmensteuerung fordert Klemmen-Freigabe durch die ELV an.
          signal KST_aut_Abschaltung_Zuendung_XIX_ClampControl_01_XIX_BMC_CAN01: start 42, 1 bit, little-endian, data-type-policy=OVERRIDE, i-signal-type=PRIMITIVE, init-value=0, base-type=BT_KST_aut_Abschaltung_Zuendung, compu {0=Cx0_Zuendung_wird_bei_Verl_nicht_deaktiviert (CM_KST_aut_Abschaltung_Zuendung_Cx0_Zuendung_wird_bei_Verl_nicht_deaktiviert), 1=Cx1_Zuendung_wird_bei_Verl_deaktiviert (CM_KST_aut_Abschaltung_Zuendung_Cx1_Zuendung_wird_bei_Verl_deaktiviert)}, range raw 0..1, transfer-property=TRIGGERED-ON-CHANGE-WITHOUT-REPETITION  # Falls bei eingeschalteter Zündung das Abblendlicht aktiv war, muss nach der automatischen Abschaltung der Kl_15 & Kl_S, dass Standlicht aktiv bleiben. Das Signal sendet die Information, dass eine automatische Abschaltung der Kl_15 und Kl_S erfogt.
          signal KST_StPtAcvReq_XIX_ClampControl_01_XIX_BMC_CAN01: start 43, 2 bit, little-endian, data-type-policy=OVERRIDE, i-signal-type=PRIMITIVE, init-value=0, base-type=BT_KST_StPtAcvReq, compu {0=Cx0_NoActivationRequest (CM_KST_StPtAcvReq_Cx0_NoActivationRequest), 1=Cx1_StoredActivationRequest (CM_KST_StPtAcvReq_Cx1_StoredActivationRequest), 2=Cx2_CurrentActivationRequest (CM_KST_StPtAcvReq_Cx2_CurrentActivationRequest)}, range raw 0..2, transfer-property=TRIGGERED-ON-CHANGE-WITHOUT-REPETITION  # ZAT-activation-demand
          signal KST_StPtDeacReq_XIX_ClampControl_01_XIX_BMC_CAN01: start 45, 1 bit, little-endian, data-type-policy=OVERRIDE, i-signal-type=PRIMITIVE, init-value=0, base-type=BT_KST_StPtDeacReq, compu {0=Cx0_NoRequest (CM_KST_StPtDeacReq_Cx0_NoRequest), 1=Cx1_RequestDeactivatePowertrain (CM_KST_StPtDeacReq_Cx1_RequestDeactivatePowertrain)}, range raw 0..1, transfer-property=TRIGGERED-ON-CHANGE-WITHOUT-REPETITION  # Anforderung Deaktivierung des Antriebsstrangs durch Klemmensteuerung
          signal KST_ZAT_betaetigt_XIX_ClampControl_01_XIX_BMC_CAN01: start 46, 1 bit, little-endian, data-type-policy=OVERRIDE, i-signal-type=PRIMITIVE, init-value=0, base-type=BT_KST_ZAT_betaetigt, compu {0=Cx0_Aus (CM_KST_ZAT_betaetigt_Cx0_Aus), 1=Cx1_Ein (CM_KST_ZAT_betaetigt_Cx1_Ein)}, range raw 0..1, transfer-property=TRIGGERED-ON-CHANGE-WITHOUT-REPETITION  # Zündanlass-Taster (ZAT) betätigt
          signal KST_ComfortReadyStatus_XIX_ClampControl_01_XIX_BMC_CAN01: start 47, 1 bit, little-endian, data-type-policy=OVERRIDE, i-signal-type=PRIMITIVE, init-value=0, base-type=BT_KST_ComfortReadyStatus, compu {0=Cx0_aus (CM_KST_ComfortReadyStatus_Cx0_aus), 1=Cx1_ComfortReadyStatus_ein (CM_KST_ComfortReadyStatus_Cx1_ComfortReadyStatus_ein)}, range raw 0..1, transfer-property=TRIGGERED-ON-CHANGE-WITHOUT-REPETITION  # Zustand des ComfortReadyStatus über den Komfortfunktionen aktiviert werden können.
          signal KST_Sonderzustand_Anforderung_XIX_ClampControl_01_XIX_BMC_CAN01: start 48, 5 bit, little-endian, data-type-policy=OVERRIDE, i-signal-type=PRIMITIVE, init-value=0, base-type=BT_KST_Sonderzustand_Anforderung, invalid-value=Invalid_KST_Sonderzustand_Anforderung_XIX_ClampControl_01_XIX_BMC_CAN01:31, compu {0=Cx0_Init (CM_KST_Sonderzustand_Anforderung_Cx0_Init), 1=Cx1_RemoteStart (CM_KST_Sonderzustand_Anforderung_Cx1_RemoteStart), 2=Cx2_RemoteParkAssist (CM_KST_Sonderzustand_Anforderung_Cx2_RemoteParkAssist), 3=Cx3_IntelligentParkAssist (CM_KST_Sonderzustand_Anforderung_Cx3_IntelligentParkAssist), 4=Cx4_TrainiertesParken (CM_KST_Sonderzustand_Anforderung_Cx4_TrainiertesParken), 5=Cx5_OnlineRemoteUpdate (CM_KST_Sonderzustand_Anforderung_Cx5_OnlineRemoteUpdate), 6=Cx6_Einfrierschutz (CM_KST_Sonderzustand_Anforderung_Cx6_Einfrierschutz), 7=Cx7_Klemme15ViaDiagnose (CM_KST_Sonderzustand_Anforderung_Cx7_Klemme15ViaDiagnose), 8=Cx8_RueckwandklappenSicherungPDC (CM_KST_Sonderzustand_Anforderung_Cx8_RueckwandklappenSicherungPDC), 9=Cx9_ParkHausPilot (CM_KST_Sonderzustand_Anforderung_Cx9_ParkHausPilot), 10=Cxa_AnhaengerAnkuppelAssistent (CM_KST_Sonderzustand_Anforderung_Cxa_AnhaengerAnkuppelAssistent), 11=Cxb_MotorWeiterlaufSchaltung (CM_KST_Sonderzustand_Anforderung_Cxb_MotorWeiterlaufSchaltung), 31=Cx1f_Fehler (CM_KST_Sonderzustand_Anforderung_Cx1f_Fehler)}, range raw 0..31, transfer-property=TRIGGERED-ON-CHANGE-WITHOUT-REPETITION  # Hiermit wird die aktive bzw. aktuell angeforderte (s. KST_Sonderzustand_Status) Sonderfunktion identifiziert
          signal KST_WFS_Fahrfreigabe_Anforderung_XIX_ClampControl_01_XIX_BMC_CAN01: start 53, 2 bit, little-endian, data-type-policy=OVERRIDE, i-signal-type=PRIMITIVE, init-value=0, base-type=BT_KST_WFS_Fahrfreigabe_Anforderung, compu {0=Cx0_Keine (CM_KST_WFS_Fahrfreigabe_Anforderung_Cx0_Keine), 1=Cx1_Uneingeschraenkt (CM_KST_WFS_Fahrfreigabe_Anforderung_Cx1_Uneingeschraenkt), 2=Cx2_Eingeschraenkt (CM_KST_WFS_Fahrfreigabe_Anforderung_Cx2_Eingeschraenkt)}, range raw 0..2, transfer-property=TRIGGERED-ON-CHANGE-WITHOUT-REPETITION  # Hiermit wird den Wegfahrsperren-Teilnehmern signalisiert welche Art der Fahrfreigabe von der anfordernden Sonderfunktion benötigt wird
      frame DEV_BJB_Req_01_XIX_BMC_CAN01: id 0x18FED000, from BMC_HV, frame-length=8, can-addressing-mode=EXTENDED, can-frame-rx-behavior=CAN-20, can-frame-tx-behavior=CAN-20
        user defined pdu CDD_DEV_BJB_Req_01_XIX_BMC_CAN01: length=8, cdd-type=EID
      frame DEV_BJB_Resp_FF_XIX_BMC_CAN01: id 0x18FED0FF, to BMC_HV, frame-length=8, can-addressing-mode=EXTENDED, can-frame-rx-behavior=CAN-20, can-frame-tx-behavior=CAN-20
        user defined pdu CDD_DEV_BJB_Resp_FF_XIX_BMC_CAN01: length=8, cdd-type=EID
      frame DEV_BMS_Resp_00_XIX_BMC_CAN01: id 0x1BFFDA00, to BMC_HV, frame-length=8, can-addressing-mode=EXTENDED, can-frame-rx-behavior=CAN-20, can-frame-tx-behavior=CAN-20
        user defined pdu CDD_DEV_BMS_Resp_00_XIX_BMC_CAN01: length=8, cdd-type=EID
      frame DEV_BMS_Resp_01_XIX_BMC_CAN01: id 0x1BFFDA01, to BMC_HV, frame-length=8, can-addressing-mode=EXTENDED, can-frame-rx-behavior=CAN-20, can-frame-tx-behavior=CAN-20
        user defined pdu CDD_DEV_BMS_Resp_01_XIX_BMC_CAN01: length=8, cdd-type=EID
      frame DEV_BMS_Resp_176_XIX_BMC_CAN01: id 0x1BFFDAB0, to BMC_HV, frame-length=8, can-addressing-mode=EXTENDED, can-frame-rx-behavior=CAN-20, can-frame-tx-behavior=CAN-20
        user defined pdu CDD_DEV_BMS_Resp_176_XIX_BMC_CAN01: length=8, cdd-type=EID
      frame DEV_BMS_Resp_177_XIX_BMC_CAN01: id 0x1BFFDAB1, to BMC_HV, frame-length=8, can-addressing-mode=EXTENDED, can-frame-rx-behavior=CAN-20, can-frame-tx-behavior=CAN-20
        user defined pdu CDD_DEV_BMS_Resp_177_XIX_BMC_CAN01: length=8, cdd-type=EID
      frame DEV_BMS_Resp_178_XIX_BMC_CAN01: id 0x1BFFDAB2, to BMC_HV, frame-length=8, can-addressing-mode=EXTENDED, can-frame-rx-behavior=CAN-20, can-frame-tx-behavior=CAN-20
        user defined pdu CDD_DEV_BMS_Resp_178_XIX_BMC_CAN01: length=8, cdd-type=EID
      frame DEV_BMS_Resp_192_XIX_BMC_CAN01: id 0x1BFFDAC0, to BMC_HV, frame-length=8, can-addressing-mode=EXTENDED, can-frame-rx-behavior=CAN-20, can-frame-tx-behavior=CAN-20
        user defined pdu CDD_DEV_BMS_Resp_192_XIX_BMC_CAN01: length=8, cdd-type=EID
      frame DEV_BMS_Resp_193_XIX_BMC_CAN01: id 0x1BFFDAC1, to BMC_HV, frame-length=8, can-addressing-mode=EXTENDED, can-frame-rx-behavior=CAN-20, can-frame-tx-behavior=CAN-20
        user defined pdu CDD_DEV_BMS_Resp_193_XIX_BMC_CAN01: length=8, cdd-type=EID
      frame DEV_BMS_Resp_194_XIX_BMC_CAN01: id 0x1BFFDAC2, to BMC_HV, frame-length=8, can-addressing-mode=EXTENDED, can-frame-rx-behavior=CAN-20, can-frame-tx-behavior=CAN-20
        user defined pdu CDD_DEV_BMS_Resp_194_XIX_BMC_CAN01: length=8, cdd-type=EID
      frame DIA_BJB_Req_XIX_BMC_CAN01: id 0x17FC16D0, from BMC_HV, frame-length=8, can-addressing-mode=EXTENDED, can-frame-rx-behavior=CAN-20, can-frame-tx-behavior=CAN-20
        n pdu DIA_BJB_Req_XIX_BMC_CAN01: length=8
      frame DIA_BJB_Resp_XIX_BMC_CAN01: id 0x17FE16D0, to BMC_HV, frame-length=8, can-addressing-mode=EXTENDED, can-frame-rx-behavior=CAN-20, can-frame-tx-behavior=CAN-20
        n pdu DIA_BJB_Resp_XIX_BMC_CAN01: length=8
      frame DIA_UI2Sens01_Req_XIX_BMC_CAN01: id 0x17FC17B1, from BMC_HV, frame-length=8, can-addressing-mode=EXTENDED, can-frame-rx-behavior=CAN-20, can-frame-tx-behavior=CAN-20
        n pdu DIA_UI2Sens01_Req_XIX_BMC_CAN01: length=8
      frame DIA_UI2Sens01_Resp_XIX_BMC_CAN01: id 0x17FE17B1, to BMC_HV, frame-length=8, can-addressing-mode=EXTENDED, can-frame-rx-behavior=CAN-20, can-frame-tx-behavior=CAN-20
        n pdu DIA_UI2Sens01_Resp_XIX_BMC_CAN01: length=8
      frame DIA_UI2Sens02_Req_XIX_BMC_CAN01: id 0x17FC17B2, from BMC_HV, frame-length=8, can-addressing-mode=EXTENDED, can-frame-rx-behavior=CAN-20, can-frame-tx-behavior=CAN-20
        n pdu DIA_UI2Sens02_Req_XIX_BMC_CAN01: length=8
      frame DIA_UI2Sens02_Resp_XIX_BMC_CAN01: id 0x17FE17B2, to BMC_HV, frame-length=8, can-addressing-mode=EXTENDED, can-frame-rx-behavior=CAN-20, can-frame-tx-behavior=CAN-20
        n pdu DIA_UI2Sens02_Resp_XIX_BMC_CAN01: length=8
      frame ISO_Funktionaler_Req_All_XIX_BMC_CAN01: id 0x700, from BMC_HV, frame-length=8, can-addressing-mode=STANDARD, can-frame-rx-behavior=CAN-20, can-frame-tx-behavior=CAN-20
        n pdu ISO_Funktionaler_Req_All_XIX_BMC_CAN01: length=8
      frame NM_Dummy01_XIX_BMC_CAN01: id 0x1B0003FF, to BMC_HV, frame-length=8, can-addressing-mode=EXTENDED, can-frame-rx-behavior=CAN-20, can-frame-tx-behavior=CAN-20, rx-identifier-range={lower-can-id=452984832, upper-can-id=452985855}
        nm pdu NM_Dummy01_XIX_BMC_CAN01: length=8, unused-bit-pattern=0
          signal NM_Dummy01_CBV_AWB_XIX_NM_Dummy01_XIX_BMC_CAN01: start 12, 1 bit, little-endian, data-type-policy=OVERRIDE, i-signal-type=PRIMITIVE, init-value=0, base-type=BT_NM_Dummy01_CBV_AWB, compu {0=Cx0_Passiver_WakeUp (CM_NM_Dummy01_CBV_AWB_Cx0_Passiver_WakeUp), 1=Cx1_Aktiver_WakeUp (CM_NM_Dummy01_CBV_AWB_Cx1_Aktiver_WakeUp)}, range raw 0..1, transfer-property=TRIGGERED  # Das Signal ist zu setzen, wenn das SG aktiv den Bus geweckt hat 0 = Passiver_WakeUp = SG hat das Netzwerk nicht aktiv geweckt 1 = Akitiver_WakeUp = SG hat das Netzwerk aktiv geweckt
          signal NM_Dummy01_CBV_CRI_XIX_NM_Dummy01_XIX_BMC_CAN01: start 14, 1 bit, little-endian, data-type-policy=OVERRIDE, i-signal-type=PRIMITIVE, init-value=0, base-type=BT_NM_Dummy01_CBV_CRI, compu {0=Cx0_NM_ohne_Clusteranforderungen (CM_NM_Dummy01_CBV_CRI_Cx0_NM_ohne_Clusteranforderungen), 1=Cx1_NM_mit_Clusteranforderungen (CM_NM_Dummy01_CBV_CRI_Cx1_NM_mit_Clusteranforderungen)}, range raw 0..1, transfer-property=TRIGGERED  # Das Signal ist dauerhaft gesetzt, wenn das NM-Layout Cluster- Anforderungen enthält
          signal NM_Dummy01_NM_State_XIX_NM_Dummy01_XIX_BMC_CAN01: start 16, 6 bit, little-endian, data-type-policy=OVERRIDE, i-signal-type=PRIMITIVE, init-value=0, base-type=BT_NM_Dummy01_NM_State, compu {0=Cx0_Init (CM_NM_Dummy01_NM_State_Cx0_Init), 1=Cx1_NM_RM_aus_BSM (CM_NM_Dummy01_NM_State_Cx1_NM_RM_aus_BSM), 2=Cx2_NM_RM_aus_PBSM (CM_NM_Dummy01_NM_State_Cx2_NM_RM_aus_PBSM), 4=Cx4_NM_NO_aus_RM (CM_NM_Dummy01_NM_State_Cx4_NM_NO_aus_RM), 8=Cx8_NM_NO_aus_RS (CM_NM_Dummy01_NM_State_Cx8_NM_NO_aus_RS), 16=Cx10_reserved (CM_NM_Dummy01_NM_State_Cx10_reserved), 32=Cx20_reserved (CM_NM_Dummy01_NM_State_Cx20_reserved)}, range raw 0..32, transfer-property=TRIGGERED, to BMC_HV(timeout 2 s)  # 1 = Zustand Repeat Message (<-- Bus-Sleep Mode) 2 = Zustand Repeat Message (<-- Prepare Bus-Sleep Mode) 4 = Zustand Normal Operation (<-- Repeat Message) 8 = Zustand Normal Operation (<-- Ready Sleep)
          signal NM_Dummy01_CAB_XIX_NM_Dummy01_XIX_BMC_CAN01: start 40, 24 bit, opaque, data-type-policy=OVERRIDE, i-signal-type=ARRAY, init-value=[0, 0, 0], base-type=BT_NM_Dummy01_CAB, compu {0=Cx0_inaktiv (CM_NM_Dummy01_CAB_Cx0_inaktiv), 1=Cx1_CAB_01_Tueren (CM_NM_Dummy01_CAB_Cx1_CAB_01_Tueren) (CAB_01__Tueren), 2=Cx2_CAB_02_Anhaenger_KCAN (CM_NM_Dummy01_CAB_Cx2_CAB_02_Anhaenger_KCAN) (CAB_02__Anhaenger_KCAN), 4=Cx4_CAB_03_Nightvision (CM_NM_Dummy01_CAB_Cx4_CAB_03_Nightvision) (CAB_03__Nightvision), 8=Cx8_CAB_04_Sitzverstellung (CM_NM_Dummy01_CAB_Cx8_CAB_04_Sitzverstellung) (CAB_04__Sitzverstellung), 16=Cx10_CAB_05_Klappen (CM_NM_Dummy01_CAB_Cx10_CAB_05_Klappen) (CAB_05__Klappen), 32=Cx20_CAB_06_Infotainment (CM_NM_Dummy01_CAB_Cx20_CAB_06_Infotainment) (CAB_06__Infotainment), 64=Cx40_CAB_07_Sub_Infotainment (CM_NM_Dummy01_CAB_Cx40_CAB_07_Sub_Infotainment) (CAB_07__Sub_Infotainment), 128=Cx80_CAB_08_Anzeige (CM_NM_Dummy01_CAB_Cx80_CAB_08_Anzeige) (CAB_08__Anzeige), 256=Cx100_CAB_09_Laden_HCAN (CM_NM_Dummy01_CAB_Cx100_CAB_09_Laden_HCAN) (CAB_09__Laden_HCAN), 512=Cx200_CAB_10_Klima (CM_NM_Dummy01_CAB_Cx200_CAB_10_Klima) (CAB_10__Klima), 1024=Cx400_CAB_11_FlexRay (CM_NM_Dummy01_CAB_Cx400_CAB_11_FlexRay) (CAB_11__FlexRay), 262144=Cx40000_CAB_19_VLAN_RemoteFC (CM_NM_Dummy01_CAB_Cx40000_CAB_19_VLAN_RemoteFC) (CAB_19__VLAN_RemoteFC), 524288=Cx80000_CAB_20_VLAN_Komfort (CM_NM_Dummy01_CAB_Cx80000_CAB_20_VLAN_Komfort) (CAB_20__VLAN_Komfort), 1048576=Cx100000_CAB_21_VLAN_Internet (CM_NM_Dummy01_CAB_Cx100000_CAB_21_VLAN_Internet) (CAB_21__VLAN_Internet), 2097152=Cx200000_CAB_22_VLAN_Connect (CM_NM_Dummy01_CAB_Cx200000_CAB_22_VLAN_Connect) (CAB_22__VLAN_Connect), 4194304=Cx400000_CAB_23_VLAN_Infotainment (CM_NM_Dummy01_CAB_Cx400000_CAB_23_VLAN_Infotainment) (CAB_23__VLAN_Infotainment), 8388608=Cx800000_CAB_24_VLAN_FAS (CM_NM_Dummy01_CAB_Cx800000_CAB_24_VLAN_FAS) (CAB_24__VLAN_FAS)}, range raw 0..8388608, transfer-property=TRIGGERED-ON-CHANGE  # CAB = Clusteraktivbits
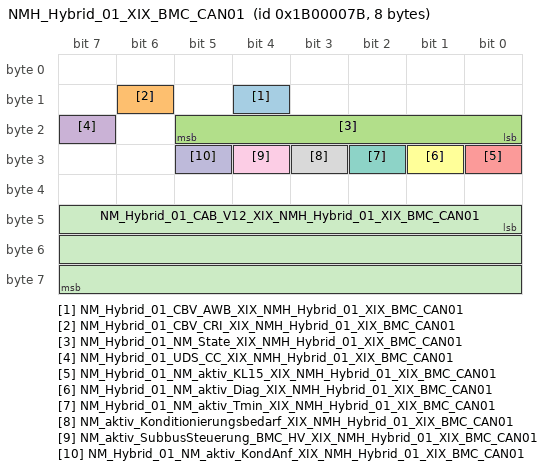
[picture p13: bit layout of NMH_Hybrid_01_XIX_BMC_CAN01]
      frame NMH_Hybrid_01_XIX_BMC_CAN01: id 0x1B00007B, from BMC_HV, frame-length=8, can-addressing-mode=EXTENDED, can-frame-rx-behavior=CAN-20, can-frame-tx-behavior=CAN-20, rx-identifier-range={lower-can-id=452984832, upper-can-id=452985855}
        nm pdu NMH_Hybrid_01_XIX_BMC_CAN01: length=8, unused-bit-pattern=0
          signal NM_Hybrid_01_CBV_AWB_XIX_NMH_Hybrid_01_XIX_BMC_CAN01: start 12, 1 bit, little-endian, data-type-policy=OVERRIDE, i-signal-type=PRIMITIVE, init-value=0, base-type=BT_NM_Hybrid_01_CBV_AWB, compu {0=Cx0_Passiver_WakeUp (CM_NM_Hybrid_01_CBV_AWB_Cx0_Passiver_WakeUp), 1=Cx1_Aktiver_WakeUp (CM_NM_Hybrid_01_CBV_AWB_Cx1_Aktiver_WakeUp)}, range raw 0..1, transfer-property=TRIGGERED  # Das Signal ist zu setzen, wenn das SG aktiv den Bus geweckt hat 0 = Passiver_WakeUp = SG hat das Netzwerk nicht aktiv geweckt 1 = Akitiver_WakeUp = SG hat das Netzwerk aktiv geweckt
          signal NM_Hybrid_01_CBV_CRI_XIX_NMH_Hybrid_01_XIX_BMC_CAN01: start 14, 1 bit, little-endian, data-type-policy=OVERRIDE, i-signal-type=PRIMITIVE, init-value=1, base-type=BT_NM_Hybrid_01_CBV_CRI, compu {0=Cx0_NM_ohne_Clusteranforderungen (CM_NM_Hybrid_01_CBV_CRI_Cx0_NM_ohne_Clusteranforderungen), 1=Cx1_NM_mit_Clusteranforderungen (CM_NM_Hybrid_01_CBV_CRI_Cx1_NM_mit_Clusteranforderungen)}, range raw 0..1, transfer-property=TRIGGERED  # Das Signal ist dauerhaft gesetzt, wenn das NM-Layout Cluster- Anforderungen enthält
          signal NM_Hybrid_01_NM_State_XIX_NMH_Hybrid_01_XIX_BMC_CAN01: start 16, 6 bit, little-endian, data-type-policy=OVERRIDE, i-signal-type=PRIMITIVE, init-value=0, base-type=BT_NM_Hybrid_01_NM_State, compu {0=Cx0_Init (CM_NM_Hybrid_01_NM_State_Cx0_Init), 1=Cx1_NM_RM_aus_BSM (CM_NM_Hybrid_01_NM_State_Cx1_NM_RM_aus_BSM), 2=Cx2_NM_RM_aus_PBSM (CM_NM_Hybrid_01_NM_State_Cx2_NM_RM_aus_PBSM), 4=Cx4_NM_NO_aus_RM (CM_NM_Hybrid_01_NM_State_Cx4_NM_NO_aus_RM), 8=Cx8_NM_NO_aus_RS (CM_NM_Hybrid_01_NM_State_Cx8_NM_NO_aus_RS), 16=Cx10_reserved (CM_NM_Hybrid_01_NM_State_Cx10_reserved), 32=Cx20_reserved (CM_NM_Hybrid_01_NM_State_Cx20_reserved)}, range raw 0..32, transfer-property=TRIGGERED-ON-CHANGE  # 1 = Zustand Repeat Message (<-- Bus-Sleep Mode) 2 = Zustand Repeat Message (<-- Prepare Bus-Sleep Mode) 4 = Zustand Normal Operation (<-- Repeat Message) 8 = Zustand Normal Operation (<-- Ready Sleep)
          signal NM_Hybrid_01_UDS_CC_XIX_NMH_Hybrid_01_XIX_BMC_CAN01: start 23, 1 bit, little-endian, data-type-policy=OVERRIDE, i-signal-type=PRIMITIVE, init-value=0, base-type=BT_NM_Hybrid_01_UDS_CC, compu {0=Cx0_Inaktiv (CM_NM_Hybrid_01_UDS_CC_Cx0_Inaktiv), 1=Cx1_CC_aktiv (CM_NM_Hybrid_01_UDS_CC_Cx1_CC_aktiv)}, range raw 0..1, transfer-property=TRIGGERED  # Funktionseinschränkung aufgrund aktivem UDS-Communication Control, siehe VW80124
          signal NM_Hybrid_01_NM_aktiv_KL15_XIX_NMH_Hybrid_01_XIX_BMC_CAN01: start 24, 1 bit, little-endian, data-type-policy=OVERRIDE, i-signal-type=PRIMITIVE, init-value=0, base-type=BT_NM_Hybrid_01_NM_aktiv_KL15, compu {0=Cx0_Inaktiv (CM_NM_Hybrid_01_NM_aktiv_KL15_Cx0_Inaktiv), 1=Cx1_KL15_EIN (CM_NM_Hybrid_01_NM_aktiv_KL15_Cx1_KL15_EIN)}, range raw 0..1, transfer-property=TRIGGERED  # Steuergerät hat KL15-EIN erkannt
          signal NM_Hybrid_01_NM_aktiv_Diag_XIX_NMH_Hybrid_01_XIX_BMC_CAN01: start 25, 1 bit, little-endian, data-type-policy=OVERRIDE, i-signal-type=PRIMITIVE, init-value=0, base-type=BT_NM_Hybrid_01_NM_aktiv_Diag, compu {0=Cx0_Inaktiv (CM_NM_Hybrid_01_NM_aktiv_Diag_Cx0_Inaktiv), 1=Cx1_Diagnose_aktiv (CM_NM_Hybrid_01_NM_aktiv_Diag_Cx1_Diagnose_aktiv)}, range raw 0..1, transfer-property=TRIGGERED  # Diagnose befindet sich nach VW80124 in einer NonDefaultDiagnostic-Session, z.B. ExtendedDiagnostic-Session
          signal NM_Hybrid_01_NM_aktiv_Tmin_XIX_NMH_Hybrid_01_XIX_BMC_CAN01: start 26, 1 bit, little-endian, data-type-policy=OVERRIDE, i-signal-type=PRIMITIVE, init-value=0, base-type=BT_NM_Hybrid_01_NM_aktiv_Tmin, compu {0=Cx0_Inaktiv (CM_NM_Hybrid_01_NM_aktiv_Tmin_Cx0_Inaktiv), 1=Cx1_Mindestaktivzeit (CM_NM_Hybrid_01_NM_aktiv_Tmin_Cx1_Mindestaktivzeit)}, range raw 0..1, transfer-property=TRIGGERED  # Mindestaktivzeit ist noch nicht abgelaufen (bei jedem Weckereignis wird die Mindestaktivzeit neu gestartet)
          signal NM_aktiv_Konditionierungsbedarf_XIX_NMH_Hybrid_01_XIX_BMC_CAN01: start 27, 1 bit, little-endian, data-type-policy=OVERRIDE, i-signal-type=PRIMITIVE, init-value=0, base-type=BT_NM_aktiv_Konditionierungsbedarf, compu {0=Cx0_Inaktiv (CM_NM_aktiv_Konditionierungsbedarf_Cx0_Inaktiv), 1=Cx1_Aktiv (CM_NM_aktiv_Konditionierungsbedarf_Cx1_Aktiv)}, range raw 0..1, transfer-property=TRIGGERED  # Die Batterie überwacht die Temperatur der Batterie und kann eine Konditionierung fordern.
          signal NM_aktiv_SubbusSteuerung_BMC_HV_XIX_NMH_Hybrid_01_XIX_BMC_CAN01: start 28, 1 bit, little-endian, data-type-policy=OVERRIDE, i-signal-type=PRIMITIVE, init-value=0, base-type=BT_NM_aktiv_SubbusSteuerung_BMC_HV, compu {0=Cx0_Inaktiv (CM_NM_aktiv_SubbusSteuerung_BMC_HV_Cx0_Inaktiv), 1=Cx1_Aktiv (CM_NM_aktiv_SubbusSteuerung_BMC_HV_Cx1_Aktiv)}, range raw 0..1, transfer-property=TRIGGERED  # Wird für die Weiterleitung der Weckanforderungen an den SubCAN benötigt.
          signal NM_Hybrid_01_NM_aktiv_KondAnf_XIX_NMH_Hybrid_01_XIX_BMC_CAN01: start 29, 1 bit, little-endian, data-type-policy=OVERRIDE, i-signal-type=PRIMITIVE, base-type=BT_NM_Hybrid_01_NM_aktiv_KondAnf, compu {0=Cx0_kein_Nachlauf (CM_NM_Hybrid_01_NM_aktiv_KondAnf_Cx0_kein_Nachlauf), 1=Cx1_Hochvolt_aktiv (CM_NM_Hybrid_01_NM_aktiv_KondAnf_Cx1_Hochvolt_aktiv)}, range raw 0..1, transfer-property=TRIGGERED  # Hochvoltbatterie Dauerkonditionierung
          signal NM_Hybrid_01_CAB_V12_XIX_NMH_Hybrid_01_XIX_BMC_CAN01: start 40, 24 bit, opaque, data-type-policy=OVERRIDE, i-signal-type=ARRAY, init-value=[0, 0, 0], base-type=BT_NM_Hybrid_01_CAB_V12, compu {0=Cx0_Inaktiv (CM_NM_Hybrid_01_CAB_V12_Cx0_Inaktiv), 1=Cx1_01_CarWakeUp (CM_NM_Hybrid_01_CAB_V12_Cx1_01_CarWakeUp), 2=Cx2_30_EnergyManagement (CM_NM_Hybrid_01_CAB_V12_Cx2_30_EnergyManagement), 4=Cx4_40_Diagnosis_Energy (CM_NM_Hybrid_01_CAB_V12_Cx4_40_Diagnosis_Energy)}, range raw 0..4, transfer-property=TRIGGERED  # CAB = Clusteraktivbits
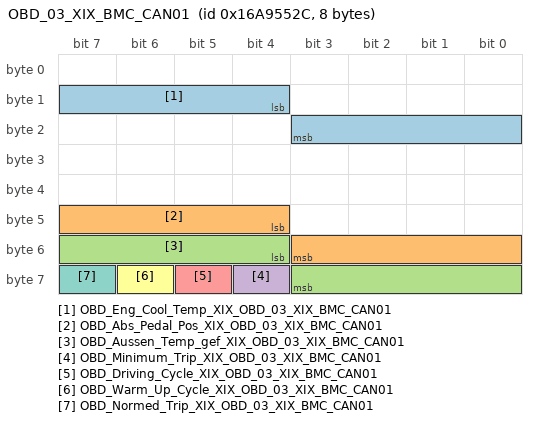
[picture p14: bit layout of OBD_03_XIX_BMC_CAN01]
      frame OBD_03_XIX_BMC_CAN01: id 0x16A9552C, from BMC_HV, frame-length=8, can-addressing-mode=EXTENDED, can-frame-rx-behavior=CAN-20, can-frame-tx-behavior=CAN-20
        pdu OBD_03_XIX_BMC_CAN01: length=8, transmission-mode-true-timing=cyclic-timing={time-offset=0, time-period=0.32}, unused-bit-pattern=0
          signal OBD_Eng_Cool_Temp_XIX_OBD_03_XIX_BMC_CAN01: start 12, 8 bit, little-endian, data-type-policy=OVERRIDE, i-signal-type=PRIMITIVE, init-value=255, base-type=BT_OBD_Eng_Cool_Temp, compu {phys=raw-40 for raw 0..255; unit Unit_DegreCelsi}, range phys -40..215 Unit_DegreCelsi, raw 0..255, unit=Unit_DegreCelsi, transfer-property=PENDING  # Engine Coolant Temperature Übertragung von Meßgrößen an das Getriebesteuergerät für Freeze Frame Abspeicherung bei Getriebefehlern PID $05 Engine Coolant Temperature; -40 .. +215°C mit 1°C/bit und 40°C Offset
          signal OBD_Abs_Pedal_Pos_XIX_OBD_03_XIX_BMC_CAN01: start 44, 8 bit, little-endian, data-type-policy=OVERRIDE, i-signal-type=PRIMITIVE, init-value=255, base-type=BT_OBD_Abs_Pedal_Pos, compu {phys=raw*0.3921568627 for raw 0..255; unit Unit_PerCent}, range phys 0..100 Unit_PerCent, raw 0..255, unit=Unit_PerCent, transfer-property=PENDING  # Absolute Pedal Position Übertragung von Meßgrößen an das Getriebesteuergerät für Freeze Frame Abspeicherung bei Getriebefehlern PID $49 Accelerator Pedal Position D; 0 .. 100% mit 100/255 %/bit
          signal OBD_Aussen_Temp_gef_XIX_OBD_03_XIX_BMC_CAN01: start 52, 8 bit, little-endian, data-type-policy=OVERRIDE, i-signal-type=PRIMITIVE, init-value=254, base-type=BT_OBD_Aussen_Temp_gef, invalid-value=Invalid_OBD_Aussen_Temp_gef_XIX_OBD_03_XIX_BMC_CAN01:255, compu {phys=raw-40 for raw 0..253, 254=Cxfe_Initwert (CM_OBD_Aussen_Temp_gef_Cxfe_Initwert), 255=Cxff_Fehler (CM_OBD_Aussen_Temp_gef_Cxff_Fehler); unit Unit_DegreCelsi}, range phys -40..213 Unit_DegreCelsi, raw 0..255, unit=Unit_DegreCelsi, transfer-property=PENDING  # Gefilterte Aussentemperatur vom Motor für OBD Funktionen.
          signal OBD_Minimum_Trip_XIX_OBD_03_XIX_BMC_CAN01: start 60, 1 bit, little-endian, data-type-policy=OVERRIDE, i-signal-type=PRIMITIVE, init-value=0, base-type=BT_OBD_Minimum_Trip, compu {0=Cx0_kein_Min_Normed_Trip (CM_OBD_Minimum_Trip_Cx0_kein_Min_Normed_Trip), 1=Cx1_Min_Normed_Trip (CM_OBD_Minimum_Trip_Cx1_Min_Normed_Trip)}, range raw 0..1, transfer-property=PENDING  # Grundlage OBD-Gesetz CCR 1968.2 (d)(4.3) Denominator Specifications Bildung des General Denominator "Normed Trip": 600 sec. (kumulativ) Zeit nach Motorstart 300 sec. (kumulativ) mit Fahrzeuggeschwindigkeit > 25 mph (40 km/h) 30 sec. (kontinuierlich) Leerlauf Wenn alle diese Bedingungen erfüllt wurden ist ein OBD_Min_Normed_Trip erfüllt
          signal OBD_Driving_Cycle_XIX_OBD_03_XIX_BMC_CAN01: start 61, 1 bit, little-endian, data-type-policy=OVERRIDE, i-signal-type=PRIMITIVE, init-value=0, base-type=BT_OBD_Driving_Cycle, compu {0=Cx0_kein_Driving_Cycle_erkannt (CM_OBD_Driving_Cycle_Cx0_kein_Driving_Cycle_erkannt), 1=Cx1_Driving_Cycle_erkannt (CM_OBD_Driving_Cycle_Cx1_Driving_Cycle_erkannt)}, range raw 0..1, transfer-property=PENDING  # Signalisierung Driving Cycle Qualifizierung - Trigger Ignition Cycle Counter
          signal OBD_Warm_Up_Cycle_XIX_OBD_03_XIX_BMC_CAN01: start 62, 1 bit, little-endian, data-type-policy=OVERRIDE, i-signal-type=PRIMITIVE, init-value=0, base-type=BT_OBD_Warm_Up_Cycle, compu {0=Cx0_kein_Warm_Up_Cycle_erkannt (CM_OBD_Warm_Up_Cycle_Cx0_kein_Warm_Up_Cycle_erkannt), 1=Cx1_Warm_Up_Cycle_erkannt (CM_OBD_Warm_Up_Cycle_Cx1_Warm_Up_Cycle_erkannt)}, range raw 0..1, transfer-property=PENDING  # Mit dem Warm-Up-Cycle wird der zentrale Verlernzähler vom Gateway inkrementiert
          signal OBD_Normed_Trip_XIX_OBD_03_XIX_BMC_CAN01: start 63, 1 bit, little-endian, data-type-policy=OVERRIDE, i-signal-type=PRIMITIVE, init-value=0, base-type=BT_OBD_Normed_Trip, compu {0=Cx0_kein_Normed_Trip (CM_OBD_Normed_Trip_Cx0_kein_Normed_Trip), 1=Cx1_Normed_Trip (CM_OBD_Normed_Trip_Cx1_Normed_Trip)}, range raw 0..1, transfer-property=PENDING  # Gesetzlich definierte "Normed Condition" erfüllt, "General Denominator" darf erhöht werden
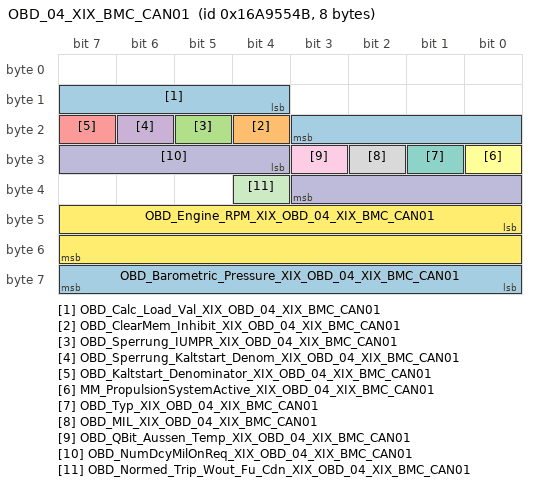
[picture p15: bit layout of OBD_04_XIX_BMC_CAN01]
      frame OBD_04_XIX_BMC_CAN01: id 0x16A9554B, from BMC_HV, frame-length=8, can-addressing-mode=EXTENDED, can-frame-rx-behavior=CAN-20, can-frame-tx-behavior=CAN-20
        pdu OBD_04_XIX_BMC_CAN01: length=8, minimum-delay=0.08, transmission-mode-true-timing={cyclic-timing={time-offset=0, time-period=0.32}, event-controlled-timing={number-of-repetitions=0, repetition-period=0}}, unused-bit-pattern=0
          signal OBD_Calc_Load_Val_XIX_OBD_04_XIX_BMC_CAN01: start 12, 8 bit, little-endian, data-type-policy=OVERRIDE, i-signal-type=PRIMITIVE, init-value=255, base-type=BT_OBD_Calc_Load_Val, compu {phys=raw*0.3921568627 for raw 0..255; unit Unit_PerCent}, range phys 0..100 Unit_PerCent, raw 0..255, unit=Unit_PerCent, transfer-property=PENDING  # Calculated Load Value Übertragung von Meßgrößen an das Getriebesteuergerät für Freeze Frame Abspeicherung bei Getriebefehlern PID $04 Calculated Load Value; 0 .. 100% mit 100/255 % per bit
          signal OBD_ClearMem_Inhibit_XIX_OBD_04_XIX_BMC_CAN01: start 20, 1 bit, little-endian, data-type-policy=OVERRIDE, i-signal-type=PRIMITIVE, init-value=0, base-type=BT_OBD_ClearMem_Inhibit, compu {0=Cx0_FSP_Loeschen_zulaessig (CM_OBD_ClearMem_Inhibit_Cx0_FSP_Loeschen_zulaessig), 1=Cx1_FSP_Loeschen_nicht_zulaessig (CM_OBD_ClearMem_Inhibit_Cx1_FSP_Loeschen_nicht_zulaessig)}, range raw 0..1, transfer-property=PENDING  # Bei FSP_Loeschen_zulässig müssen alle OBD-ECUs im Gesamtfahrzeug einen Service 04hex Request (Ereignisspeicher löschen) korrekt ausführen. In MLB-, MLBevo-, MQB-Fahrzeugkonzepten muss der MIL-Master/Motorsteuergerät bei Kl.15 ein, projektabhängig, konstant OBD_ClearMem_Inhibit = 0 senden, sofern das Löschen des Ereignisspeichers noch in jedem Betriebszustand (auch bei laufendem Motor, etc.) gefordert ist. Projektspezifisch im MLB-, MLBevo-, und MQB-Fahrzeugkonzepten und vollumfänglich in MQB_37W- und MLB3-Fahrzeugkonzepten wird das Ereignisspeicher löschen in allen OBD-ECUs auf den Betriebszustand stehendes Fahrzeug und stehender Motor beschränkt und die entsprechende Freigabe das Ereignisspeicher Löschens vom MIL-Master über das Bussignal OBD_ClearMem_Inhibit für alle anderen OBD-ECUs im Gesamtfahrzeug signalisiert. Hinweis: Steuergerät- oder Komponentenspezifische Randbedingungen sind unter Abhängigkeit des Sicherheitskonzepts zu prüfen und zu bewerten.
          signal OBD_Sperrung_IUMPR_XIX_OBD_04_XIX_BMC_CAN01: start 21, 1 bit, little-endian, data-type-policy=OVERRIDE, i-signal-type=PRIMITIVE, init-value=0, base-type=BT_OBD_Sperrung_IUMPR, compu {0=Cx0_IUMPR_Berechnung_freigegeben (CM_OBD_Sperrung_IUMPR_Cx0_IUMPR_Berechnung_freigegeben), 1=Cx1_IUMPR_Berechnung_gesperrt (CM_OBD_Sperrung_IUMPR_Cx1_IUMPR_Berechnung_gesperrt)}, range raw 0..1, transfer-property=PENDING  # Wenn der General Denominator auf Grund eines Fehlers in den Eingangsgrößen gesperrt wird, wird diese Information über Bussystem als OBD-Statusinformation OBD_Sperrung_IUMPR für andere OBD-Steuergeräte bereitgestellt. Das MSG (MIL-Master) setzt dieses Bit, wenn auf Grund vorliegender Sperrbedingungen keine Inkrementierung des GeneralDenominator mehr stattfindet. Im Empfänger-SG ist entsprechend die Inkrementierung des oder der Numeratoren einzufrieren.
          signal OBD_Sperrung_Kaltstart_Denom_XIX_OBD_04_XIX_BMC_CAN01: start 22, 1 bit, little-endian, data-type-policy=OVERRIDE, i-signal-type=PRIMITIVE, init-value=0, base-type=BT_OBD_Sperrung_Kaltstart_Denom, compu {0=Cx0_EVAP_Berechnung_freigegeben (CM_OBD_Sperrung_Kaltstart_Denom_Cx0_EVAP_Berechnung_freigegeben), 1=Cx1_EVAP_Berechnung_gesperrt (CM_OBD_Sperrung_Kaltstart_Denom_Cx1_EVAP_Berechnung_gesperrt)}, range raw 0..1, transfer-property=PENDING  # Information vom MIL Master, dass die Bildung des EVAP Denominators im Motor nicht möglich ist und damit der noECM-Denominator gesperrt werden darf.
          signal OBD_Kaltstart_Denominator_XIX_OBD_04_XIX_BMC_CAN01: start 23, 1 bit, little-endian, data-type-policy=OVERRIDE, i-signal-type=PRIMITIVE, init-value=0, base-type=BT_OBD_Kaltstart_Denominator, compu {0=Cx0_Denominator_nicht_hochzaehlen (CM_OBD_Kaltstart_Denominator_Cx0_Denominator_nicht_hochzaehlen), 1=Cx1_Bedingungen_zum_Inkr_des_Kaltstart_Denom_erf (CM_OBD_Kaltstart_Denominator_Cx1_Bedingungen_zum_Inkr_des_Kaltstart_Denom_erf)}, range raw 0..1, transfer-property=PENDING  # Bestimmte Diagnosen werden nur unter Kaltstartbedingungen durchgeführt, der entsprechende Denominator bei IUMPR-pflichtigen Systemen wird anhand dieses vom MSG gebildeten Signals inkrementiert. (Entspricht EVAP-Denominator)
          signal MM_PropulsionSystemActive_XIX_OBD_04_XIX_BMC_CAN01: start 24, 1 bit, little-endian, data-type-policy=OVERRIDE, i-signal-type=PRIMITIVE, init-value=0, base-type=BT_MM_PropulsionSystemActive, compu {0=Cx0_PropulsionSystemNotActive (CM_MM_PropulsionSystemActive_Cx0_PropulsionSystemNotActive), 1=Cx1_PropulsionSystemActive (CM_MM_PropulsionSystemActive_Cx1_PropulsionSystemActive)}, range raw 0..1, transfer-property=TRIGGERED-ON-CHANGE-WITHOUT-REPETITION  # Fahrzeug ist fahrbereit
          signal OBD_Typ_XIX_OBD_04_XIX_BMC_CAN01: start 25, 1 bit, little-endian, data-type-policy=OVERRIDE, i-signal-type=PRIMITIVE, init-value=0, base-type=BT_OBD_Typ, compu {0=Cx0_OBDReady (CM_OBD_Typ_Cx0_OBDReady), 1=Cx1_FullOBD (CM_OBD_Typ_Cx1_FullOBD)}, range raw 0..1, transfer-property=PENDING  # Abgastyp OBD Hinweis: In Fahrzeugen mit dem Zielmarkt China und einer Zertifizierung ab China 6 muss auf dem Signal "OBD_Typ" der Wert "US_OBD" gesendet werden."
          signal OBD_MIL_XIX_OBD_04_XIX_BMC_CAN01: start 26, 1 bit, little-endian, data-type-policy=OVERRIDE, i-signal-type=PRIMITIVE, init-value=0, base-type=BT_OBD_MIL, invalid-value=Invalid_OBD_MIL_XIX_OBD_04_XIX_BMC_CAN01:1, compu {0=Cx0_Lampe_aus (CM_OBD_MIL_Cx0_Lampe_aus), 1=Cx1_Fehler (CM_OBD_MIL_Cx1_Fehler)}, range raw 0..1, transfer-property=TRIGGERED-ON-CHANGE-WITHOUT-REPETITION  # Ansteuerung der MIL
          signal OBD_QBit_Aussen_Temp_XIX_OBD_04_XIX_BMC_CAN01: start 27, 1 bit, little-endian, data-type-policy=OVERRIDE, i-signal-type=PRIMITIVE, init-value=1, base-type=BT_OBD_QBit_Aussen_Temp, compu {0=Cx0_gueltiger_Wert (CM_OBD_QBit_Aussen_Temp_Cx0_gueltiger_Wert), 1=Cx1_Ersatz_Init_oder_Fehlerwert (CM_OBD_QBit_Aussen_Temp_Cx1_Ersatz_Init_oder_Fehlerwert)}, range raw 0..1, transfer-property=TRIGGERED-ON-CHANGE-WITHOUT-REPETITION  # QBit der Aussentemperatur. Gesetzt bei Ersatzwert, Init oder Fehler.
          signal OBD_NumDcyMilOnReq_XIX_OBD_04_XIX_BMC_CAN01: start 28, 8 bit, little-endian, data-type-policy=OVERRIDE, i-signal-type=PRIMITIVE, init-value=0, base-type=BT_OBD_NumDcyMilOnReq, compu {phys=raw for raw 0..255; unit Unit_None}, range phys 0..255 Unit_None, raw 0..255, unit=Unit_None, transfer-property=PENDING  # Anzahl der DrivingCycle für MIL-Entprellung von MIL-Master
          signal OBD_Normed_Trip_Wout_Fu_Cdn_XIX_OBD_04_XIX_BMC_CAN01: start 36, 1 bit, little-endian, data-type-policy=OVERRIDE, i-signal-type=PRIMITIVE, init-value=0, base-type=BT_OBD_Normed_Trip_Wout_Fu_Cdn, compu {0=Cx0_kein_Normed_Trip_wo_Fu_Cdn (CM_OBD_Normed_Trip_Wout_Fu_Cdn_Cx0_kein_Normed_Trip_wo_Fu_Cdn), 1=Cx1_Normed_Trip_wo_Fu_Cdn (CM_OBD_Normed_Trip_Wout_Fu_Cdn_Cx1_Normed_Trip_wo_Fu_Cdn)}, range raw 0..1, transfer-property=PENDING  # Bedingung für General Denominator-Inkrementierung ohne FueledEngine-Operation -> wird für die Berechnung des General Denominators in der Motorsteuerung (ScanTool-Ausgabe Mode$09, InfoType$08, OBDCOND) benötigt
          signal OBD_Engine_RPM_XIX_OBD_04_XIX_BMC_CAN01: start 40, 16 bit, little-endian, data-type-policy=OVERRIDE, i-signal-type=PRIMITIVE, init-value=0, base-type=BT_OBD_Engine_RPM, compu {phys=raw*0.25 for raw 0..65535; unit Unit_MinutInver}, range phys 0..16383.75 Unit_MinutInver, raw 0..65535, unit=Unit_MinutInver, transfer-property=PENDING  # Motordrehzahl des Verbrennungsmotors für OBD freeze frame
          signal OBD_Barometric_Pressure_XIX_OBD_04_XIX_BMC_CAN01: start 56, 8 bit, little-endian, data-type-policy=OVERRIDE, i-signal-type=PRIMITIVE, init-value=0, base-type=BT_OBD_Barometric_Pressure, compu {phys=raw for raw 0..255; unit Unit_KiloPascal}, range phys 0..255 Unit_KiloPascal, raw 0..255, unit=Unit_KiloPascal, transfer-property=PENDING  # Umgebungsdruck für OBD freeze frame
      frame OBDC_Funktionaler_Req_All_XIX_BMC_CAN01: id 0x17FD0200, from BMC_HV, frame-length=8, can-addressing-mode=EXTENDED, can-frame-rx-behavior=CAN-20, can-frame-tx-behavior=CAN-20
        n pdu OBDC_Funktionaler_Req_All_XIX_BMC_CAN01: length=8
      frame OBDC_SSN_BJB_Req_XIX_BMC_CAN01: id 0x17FC70D0, from BMC_HV, frame-length=8, can-addressing-mode=EXTENDED, can-frame-rx-behavior=CAN-20, can-frame-tx-behavior=CAN-20
        n pdu OBDC_SSN_BJB_Req_XIX_BMC_CAN01: length=8
      frame OBDC_SSN_BJB_Resp_XIX_BMC_CAN01: id 0x17FE70D0, to BMC_HV, frame-length=8, can-addressing-mode=EXTENDED, can-frame-rx-behavior=CAN-20, can-frame-tx-behavior=CAN-20
        n pdu OBDC_SSN_BJB_Resp_XIX_BMC_CAN01: length=8
      frame OBDC_SSN_UI2Sens01_Req_XIX_BMC_CAN01: id 0x17FC71B1, from BMC_HV, frame-length=8, can-addressing-mode=EXTENDED, can-frame-rx-behavior=CAN-20, can-frame-tx-behavior=CAN-20
        n pdu OBDC_SSN_UI2Sens01_Req_XIX_BMC_CAN01: length=8
      frame OBDC_SSN_UI2Sens01_Resp_XIX_BMC_CAN01: id 0x17FE71B1, to BMC_HV, frame-length=8, can-addressing-mode=EXTENDED, can-frame-rx-behavior=CAN-20, can-frame-tx-behavior=CAN-20
        n pdu OBDC_SSN_UI2Sens01_Resp_XIX_BMC_CAN01: length=8
      frame OBDC_SSN_UI2Sens02_Req_XIX_BMC_CAN01: id 0x17FC71B2, from BMC_HV, frame-length=8, can-addressing-mode=EXTENDED, can-frame-rx-behavior=CAN-20, can-frame-tx-behavior=CAN-20
        n pdu OBDC_SSN_UI2Sens02_Req_XIX_BMC_CAN01: length=8
      frame OBDC_SSN_UI2Sens02_Resp_XIX_BMC_CAN01: id 0x17FE71B2, to BMC_HV, frame-length=8, can-addressing-mode=EXTENDED, can-frame-rx-behavior=CAN-20, can-frame-tx-behavior=CAN-20
        n pdu OBDC_SSN_UI2Sens02_Resp_XIX_BMC_CAN01: length=8
      frame OBDx_allOBD_Req_XIX_BMC_CAN01: id 0x18DB33F1, from BMC_HV, frame-length=8, can-addressing-mode=EXTENDED, can-frame-rx-behavior=CAN-20, can-frame-tx-behavior=CAN-20
        n pdu OBDx_allOBD_Req_XIX_BMC_CAN01: length=8
      frame ORU_01_XIX_BMC_CAN01: id 0x1A555548, from BMC_HV, frame-length=8, can-addressing-mode=EXTENDED, can-frame-rx-behavior=CAN-20, can-frame-tx-behavior=CAN-20
        pdu ORU_01_XIX_BMC_CAN01: length=8, transmission-mode-true-timing=cyclic-timing={time-offset=0, time-period=0.5}, unused-bit-pattern=0
          signal ORU_AgLgtSdsl_XIX_ORU_01_XIX_BMC_CAN01: start 12, 11 bit, little-endian, data-type-policy=OVERRIDE, i-signal-type=PRIMITIVE, init-value=2001, base-type=BT_ORU_AgLgtSdsl, invalid-value=Invalid_ORU_AgLgtSdsl_XIX_ORU_01_XIX_BMC_CAN01:2002, compu {phys=raw*0.1-100 for raw 0..2000, 2001=Cx7d1_InitWert (CM_ORU_AgLgtSdsl_Cx7d1_InitWert), 2002=Cx7d2_Fehler (CM_ORU_AgLgtSdsl_Cx7d2_Fehler); unit Unit_PerCent}, range phys -100..100 Unit_PerCent, raw 0..2002, unit=Unit_PerCent, transfer-property=PENDING  # Vehicle inclination angle at standstill in percent
          signal ORU_Status_XIX_ORU_01_XIX_BMC_CAN01: start 61, 3 bit, little-endian, data-type-policy=OVERRIDE, i-signal-type=PRIMITIVE, init-value=0, base-type=BT_ORU_Status, compu {0=Cx0_IDLE (CM_ORU_Status_Cx0_IDLE), 1=Cx1_PENDING (CM_ORU_Status_Cx1_PENDING), 2=Cx2_PREPARATION (CM_ORU_Status_Cx2_PREPARATION), 3=Cx3_PREPARATION_HV (CM_ORU_Status_Cx3_PREPARATION_HV), 4=Cx4_RUNNING (CM_ORU_Status_Cx4_RUNNING), 5=Cx5_RUNNING_HV (CM_ORU_Status_Cx5_RUNNING_HV), 6=Cx6_PENDING_NOTREADY (CM_ORU_Status_Cx6_PENDING_NOTREADY), 7=Cx7_FAILURE_POWERTRAIN_DISABLED (CM_ORU_Status_Cx7_FAILURE_POWERTRAIN_DISABLED)}, range raw 0..7, transfer-property=PENDING  # Verteilung des internen ORU Zustandes
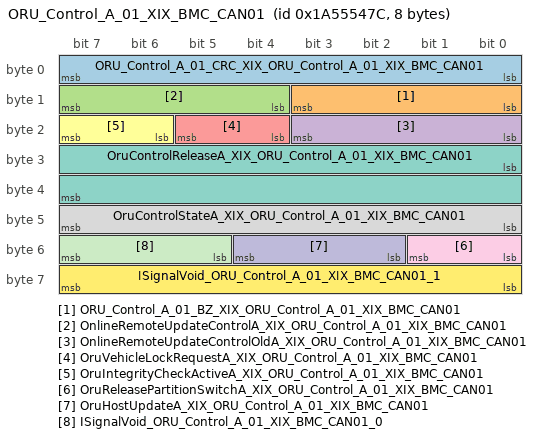
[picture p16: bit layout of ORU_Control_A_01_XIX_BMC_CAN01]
      frame ORU_Control_A_01_XIX_BMC_CAN01: id 0x1A55547C, from BMC_HV, frame-length=8, can-addressing-mode=EXTENDED, can-frame-rx-behavior=CAN-20, can-frame-tx-behavior=CAN-20
        pdu ORU_Control_A_01_XIX_BMC_CAN01: length=8, transmission-mode-true-timing=cyclic-timing={time-offset=0, time-period=0.5}, unused-bit-pattern=0
          signal ORU_Control_A_01_CRC_XIX_ORU_Control_A_01_XIX_BMC_CAN01: start 0, 8 bit, little-endian, data-type-policy=OVERRIDE, i-signal-type=PRIMITIVE, init-value=0, base-type=BT_ORU_Control_A_01_CRC, compu {phys=raw for raw 0..255}, range phys 0..255, raw 0..255
          signal ORU_Control_A_01_BZ_XIX_ORU_Control_A_01_XIX_BMC_CAN01: start 8, 4 bit, little-endian, data-type-policy=OVERRIDE, i-signal-type=PRIMITIVE, init-value=0, base-type=BT_ORU_Control_A_01_BZ, compu {phys=raw for raw 0..15}, range phys 0..15, raw 0..15
          signal OnlineRemoteUpdateControlA_XIX_ORU_Control_A_01_XIX_BMC_CAN01: start 12, 4 bit, little-endian, data-type-policy=OVERRIDE, i-signal-type=PRIMITIVE, init-value=0, base-type=BT_OnlineRemoteUpdateControlA, invalid-value=Invalid_OnlineRemoteUpdateControlA_XIX_ORU_Control_A_01_XIX_BMC_CAN01:15, compu {0=Cx0_IDLE (CM_OnlineRemoteUpdateControlA_Cx0_IDLE), 1=Cx1_PENDING (CM_OnlineRemoteUpdateControlA_Cx1_PENDING), 2=Cx2_PREPARATION (CM_OnlineRemoteUpdateControlA_Cx2_PREPARATION), 3=Cx3_PREPARATION_HV (CM_OnlineRemoteUpdateControlA_Cx3_PREPARATION_HV), 4=Cx4_RUNNING (CM_OnlineRemoteUpdateControlA_Cx4_RUNNING), 5=Cx5_RUNNING_HV (CM_OnlineRemoteUpdateControlA_Cx5_RUNNING_HV), 6=Cx6_PENDING_NOTREADY (CM_OnlineRemoteUpdateControlA_Cx6_PENDING_NOTREADY), 7=Cx7_OTA_FAILURE_POWERTRAIN_DISABLED (CM_OnlineRemoteUpdateControlA_Cx7_OTA_FAILURE_POWERTRAIN_DISABLED), 8=Cx8_FUNCTIONAL_SAFETY_RELEASED (CM_OnlineRemoteUpdateControlA_Cx8_FUNCTIONAL_SAFETY_RELEASED), 9=Cx9_PREPARATION_SG (CM_OnlineRemoteUpdateControlA_Cx9_PREPARATION_SG), 15=Cxf_Fehler (CM_OnlineRemoteUpdateControlA_Cxf_Fehler)}, range raw 0..15  # Current state of the oru control component
          signal OnlineRemoteUpdateControlOldA_XIX_ORU_Control_A_01_XIX_BMC_CAN01: start 16, 4 bit, little-endian, data-type-policy=OVERRIDE, i-signal-type=PRIMITIVE, init-value=0, base-type=BT_OnlineRemoteUpdateControlOldA, invalid-value=Invalid_OnlineRemoteUpdateControlOldA_XIX_ORU_Control_A_01_XIX_BMC_CAN01:15, compu {0=Cx0_IDLE (CM_OnlineRemoteUpdateControlOldA_Cx0_IDLE), 1=Cx1_PENDING (CM_OnlineRemoteUpdateControlOldA_Cx1_PENDING), 2=Cx2_PREPARATION (CM_OnlineRemoteUpdateControlOldA_Cx2_PREPARATION), 3=Cx3_PREPARATION_HV (CM_OnlineRemoteUpdateControlOldA_Cx3_PREPARATION_HV), 4=Cx4_RUNNING (CM_OnlineRemoteUpdateControlOldA_Cx4_RUNNING), 5=Cx5_RUNNING_HV (CM_OnlineRemoteUpdateControlOldA_Cx5_RUNNING_HV), 6=Cx6_PENDING_NOTREADY (CM_OnlineRemoteUpdateControlOldA_Cx6_PENDING_NOTREADY), 7=Cx7_OTA_FAILURE_POWERTRAIN_DISABLED (CM_OnlineRemoteUpdateControlOldA_Cx7_OTA_FAILURE_POWERTRAIN_DISABLED), 8=Cx8_FUNCTIONAL_SAFETY_RELEASE (CM_OnlineRemoteUpdateControlOldA_Cx8_FUNCTIONAL_SAFETY_RELEASE), 9=Cx9_PREPARATION_SG (CM_OnlineRemoteUpdateControlOldA_Cx9_PREPARATION_SG), 15=Cxf_Fehler (CM_OnlineRemoteUpdateControlOldA_Cxf_Fehler)}, range raw 0..15  # Old state of the ORU control A signal (state 5 cycles before)
          signal OruVehicleLockRequestA_XIX_ORU_Control_A_01_XIX_BMC_CAN01: start 20, 2 bit, little-endian, data-type-policy=OVERRIDE, i-signal-type=PRIMITIVE, init-value=0, base-type=BT_OruVehicleLockRequestA, invalid-value=Invalid_OruVehicleLockRequestA_XIX_ORU_Control_A_01_XIX_BMC_CAN01:3, compu {0=Cx0_Init (CM_OruVehicleLockRequestA_Cx0_Init), 1=Cx1_Lock (CM_OruVehicleLockRequestA_Cx1_Lock), 2=Cx2_Release (CM_OruVehicleLockRequestA_Cx2_Release), 3=Cx3_Fehler (CM_OruVehicleLockRequestA_Cx3_Fehler)}, range raw 0..3  # Releases or locks one or more ECUs with their specific functions (e.g. immobilizer)
          signal OruIntegrityCheckActiveA_XIX_ORU_Control_A_01_XIX_BMC_CAN01: start 22, 2 bit, little-endian, data-type-policy=OVERRIDE, i-signal-type=PRIMITIVE, init-value=0, base-type=BT_OruIntegrityCheckActiveA, invalid-value=Invalid_OruIntegrityCheckActiveA_XIX_ORU_Control_A_01_XIX_BMC_CAN01:3, compu {0=Cx0_Init (CM_OruIntegrityCheckActiveA_Cx0_Init), 1=Cx1_Inactive (CM_OruIntegrityCheckActiveA_Cx1_Inactive), 2=Cx2_Active (CM_OruIntegrityCheckActiveA_Cx2_Active), 3=Cx3_Fehler (CM_OruIntegrityCheckActiveA_Cx3_Fehler)}, range raw 0..3  # Signal to indicate if the integrity check is active
          signal OruControlReleaseA_XIX_ORU_Control_A_01_XIX_BMC_CAN01: start 24, 16 bit, little-endian, data-type-policy=OVERRIDE, i-signal-type=PRIMITIVE, init-value=0, base-type=BT_OruControlReleaseA, compu {phys=raw for raw 0..65535; unit Unit_None}, range phys 0..65535 Unit_None, raw 0..65535, unit=Unit_None  # Release of an ecu to be flashed by oru
          signal OruControlStateA_XIX_ORU_Control_A_01_XIX_BMC_CAN01: start 40, 8 bit, little-endian, data-type-policy=OVERRIDE, i-signal-type=PRIMITIVE, init-value=0, base-type=BT_OruControlStateA, invalid-value=Invalid_OruControlStateA_XIX_ORU_Control_A_01_XIX_BMC_CAN01:129, compu {0=Cx0_Idle (CM_OruControlStateA_Cx0_Idle), 1=Cx1_Check (CM_OruControlStateA_Cx1_Check), 3=Cx3_DataPresent (CM_OruControlStateA_Cx3_DataPresent), 7=Cx7_LockActive (CM_OruControlStateA_Cx7_LockActive), 15=Cxf_Running (CM_OruControlStateA_Cxf_Running), 31=Cx1f_Save (CM_OruControlStateA_Cx1f_Save), 63=Cx3f_Done (CM_OruControlStateA_Cx3f_Done), 65=Cx41_Fail (CM_OruControlStateA_Cx41_Fail), 129=Cx81_Fehler (CM_OruControlStateA_Cx81_Fehler)}, range raw 0..129  # Internal State of ORU Control component.
          signal OruReleasePartitionSwitchA_XIX_ORU_Control_A_01_XIX_BMC_CAN01: start 48, 2 bit, little-endian, data-type-policy=OVERRIDE, i-signal-type=PRIMITIVE, init-value=0, base-type=BT_OruReleasePartitionSwitchA, invalid-value=Invalid_OruReleasePartitionSwitchA_XIX_ORU_Control_A_01_XIX_BMC_CAN01:3, compu {0=Cx0_Init (CM_OruReleasePartitionSwitchA_Cx0_Init), 1=Cx1_Lock (CM_OruReleasePartitionSwitchA_Cx1_Lock), 2=Cx2_Release (CM_OruReleasePartitionSwitchA_Cx2_Release), 3=Cx3_Fehler (CM_OruReleasePartitionSwitchA_Cx3_Fehler)}, range raw 0..3  # Release to switch the partition in case of an A/B partition update
          signal OruHostUpdateA_XIX_ORU_Control_A_01_XIX_BMC_CAN01: start 50, 3 bit, little-endian, data-type-policy=OVERRIDE, i-signal-type=PRIMITIVE, init-value=0, base-type=BT_OruHostUpdateA, invalid-value=Invalid_OruHostUpdateA_XIX_ORU_Control_A_01_XIX_BMC_CAN01:4, compu {0=Cx0_Init (CM_OruHostUpdateA_Cx0_Init), 1=Cx1_HostControl1 (CM_OruHostUpdateA_Cx1_HostControl1), 2=Cx2_HostControl2 (CM_OruHostUpdateA_Cx2_HostControl2), 3=Cx3_HostControlOther (CM_OruHostUpdateA_Cx3_HostControlOther), 4=Cx4_Fehler (CM_OruHostUpdateA_Cx4_Fehler)}, range raw 0..4  # Releases an update of an critical funcion's host (due to functional safety)
          mapping SG_ORU_Control_A_01_XIX_BMC_CAN01: i-signal-group=SG_ORU_Control_A_01_XIX_BMC_CAN01, transfer-property=PENDING
          signal ISignalVoid_ORU_Control_A_01_XIX_BMC_CAN01_0: start 53, 3 bit, little-endian, system signal SignalVoid_ORU_Control_A_01_0, data-type-policy=OVERRIDE, i-signal-type=PRIMITIVE, base-type=BT_SignalVoid
          signal ISignalVoid_ORU_Control_A_01_XIX_BMC_CAN01_1: start 56, 8 bit, little-endian, system signal SignalVoid_ORU_Control_A_01_1, data-type-policy=OVERRIDE, i-signal-type=PRIMITIVE, base-type=BT_SignalVoid
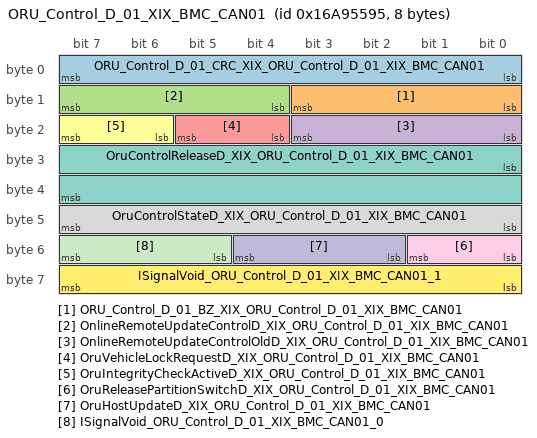
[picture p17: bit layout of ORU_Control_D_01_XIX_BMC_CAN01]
      frame ORU_Control_D_01_XIX_BMC_CAN01: id 0x16A95595, from BMC_HV, frame-length=8, can-addressing-mode=EXTENDED, can-frame-rx-behavior=CAN-20, can-frame-tx-behavior=CAN-20
        pdu ORU_Control_D_01_XIX_BMC_CAN01: length=8, transmission-mode-true-timing=cyclic-timing={time-offset=0, time-period=0.32}, unused-bit-pattern=0
          signal ORU_Control_D_01_CRC_XIX_ORU_Control_D_01_XIX_BMC_CAN01: start 0, 8 bit, little-endian, data-type-policy=OVERRIDE, i-signal-type=PRIMITIVE, init-value=0, base-type=BT_ORU_Control_D_01_CRC, compu {phys=raw for raw 0..255}, range phys 0..255, raw 0..255
          signal ORU_Control_D_01_BZ_XIX_ORU_Control_D_01_XIX_BMC_CAN01: start 8, 4 bit, little-endian, data-type-policy=OVERRIDE, i-signal-type=PRIMITIVE, init-value=0, base-type=BT_ORU_Control_D_01_BZ, compu {phys=raw for raw 0..15}, range phys 0..15, raw 0..15
          signal OnlineRemoteUpdateControlD_XIX_ORU_Control_D_01_XIX_BMC_CAN01: start 12, 4 bit, little-endian, data-type-policy=OVERRIDE, i-signal-type=PRIMITIVE, init-value=0, base-type=BT_OnlineRemoteUpdateControlD, invalid-value=Invalid_OnlineRemoteUpdateControlD_XIX_ORU_Control_D_01_XIX_BMC_CAN01:15, compu {0=Cx0_IDLE (CM_OnlineRemoteUpdateControlD_Cx0_IDLE), 1=Cx1_PENDING (CM_OnlineRemoteUpdateControlD_Cx1_PENDING), 2=Cx2_PREPARATION (CM_OnlineRemoteUpdateControlD_Cx2_PREPARATION), 3=Cx3_PREPARATION_HV (CM_OnlineRemoteUpdateControlD_Cx3_PREPARATION_HV), 4=Cx4_RUNNING (CM_OnlineRemoteUpdateControlD_Cx4_RUNNING), 5=Cx5_RUNNING_HV (CM_OnlineRemoteUpdateControlD_Cx5_RUNNING_HV), 6=Cx6_PENDING_NOTREADY (CM_OnlineRemoteUpdateControlD_Cx6_PENDING_NOTREADY), 7=Cx7_OTA_FAILURE_POWERTRAIN_DISABLED (CM_OnlineRemoteUpdateControlD_Cx7_OTA_FAILURE_POWERTRAIN_DISABLED), 8=Cx8_FUNCTIONAL_SAFETY_RELEASE (CM_OnlineRemoteUpdateControlD_Cx8_FUNCTIONAL_SAFETY_RELEASE), 9=Cx9_PREPARATION_SG (CM_OnlineRemoteUpdateControlD_Cx9_PREPARATION_SG), 15=Cxf_Fehler (CM_OnlineRemoteUpdateControlD_Cxf_Fehler)}, range raw 0..15  # This signal is part of the ORU functional safety concept to inform ECUs, if an update is possible
          signal OnlineRemoteUpdateControlOldD_XIX_ORU_Control_D_01_XIX_BMC_CAN01: start 16, 4 bit, little-endian, data-type-policy=OVERRIDE, i-signal-type=PRIMITIVE, init-value=0, base-type=BT_OnlineRemoteUpdateControlOldD, invalid-value=Invalid_OnlineRemoteUpdateControlOldD_XIX_ORU_Control_D_01_XIX_BMC_CAN01:15, compu {0=Cx0_IDLE (CM_OnlineRemoteUpdateControlOldD_Cx0_IDLE), 1=Cx1_PENDING (CM_OnlineRemoteUpdateControlOldD_Cx1_PENDING), 2=Cx2_PREPARATION (CM_OnlineRemoteUpdateControlOldD_Cx2_PREPARATION), 3=Cx3_PREPARATION_HV (CM_OnlineRemoteUpdateControlOldD_Cx3_PREPARATION_HV), 4=Cx4_RUNNING (CM_OnlineRemoteUpdateControlOldD_Cx4_RUNNING), 5=Cx5_RUNNING_HV (CM_OnlineRemoteUpdateControlOldD_Cx5_RUNNING_HV), 6=Cx6_PENDING_NOTREADY (CM_OnlineRemoteUpdateControlOldD_Cx6_PENDING_NOTREADY), 7=Cx7_OTA_FAILURE_POWERTRAIN_DISABLED (CM_OnlineRemoteUpdateControlOldD_Cx7_OTA_FAILURE_POWERTRAIN_DISABLED), 8=Cx8_FUNCTIONAL_SAFETY_RELEASE (CM_OnlineRemoteUpdateControlOldD_Cx8_FUNCTIONAL_SAFETY_RELEASE), 9=Cx9_PREPARATION_SG (CM_OnlineRemoteUpdateControlOldD_Cx9_PREPARATION_SG), 15=Cxf_Fehler (CM_OnlineRemoteUpdateControlOldD_Cxf_Fehler)}, range raw 0..15  # Old state of the ORU control C component (state as of 5 previous cycles)
          signal OruVehicleLockRequestD_XIX_ORU_Control_D_01_XIX_BMC_CAN01: start 20, 2 bit, little-endian, data-type-policy=OVERRIDE, i-signal-type=PRIMITIVE, init-value=0, base-type=BT_OruVehicleLockRequestD, invalid-value=Invalid_OruVehicleLockRequestD_XIX_ORU_Control_D_01_XIX_BMC_CAN01:3, compu {0=Cx0_Init (CM_OruVehicleLockRequestD_Cx0_Init), 1=Cx1_Lock (CM_OruVehicleLockRequestD_Cx1_Lock), 2=Cx2_Release (CM_OruVehicleLockRequestD_Cx2_Release), 3=Cx3_Fehler (CM_OruVehicleLockRequestD_Cx3_Fehler)}, range raw 0..3  # Releases or locks one or more ECUs with their specific functions (e.g. immobilizer)
          signal OruIntegrityCheckActiveD_XIX_ORU_Control_D_01_XIX_BMC_CAN01: start 22, 2 bit, little-endian, data-type-policy=OVERRIDE, i-signal-type=PRIMITIVE, init-value=0, base-type=BT_OruIntegrityCheckActiveD, invalid-value=Invalid_OruIntegrityCheckActiveD_XIX_ORU_Control_D_01_XIX_BMC_CAN01:3, compu {0=Cx0_Init (CM_OruIntegrityCheckActiveD_Cx0_Init), 1=Cx1_Inactive (CM_OruIntegrityCheckActiveD_Cx1_Inactive), 2=Cx2_Active (CM_OruIntegrityCheckActiveD_Cx2_Active), 3=Cx3_Fehler (CM_OruIntegrityCheckActiveD_Cx3_Fehler)}, range raw 0..3  # Signal to indicate if the integrity check is active
          signal OruControlReleaseD_XIX_ORU_Control_D_01_XIX_BMC_CAN01: start 24, 16 bit, little-endian, data-type-policy=OVERRIDE, i-signal-type=PRIMITIVE, init-value=0, base-type=BT_OruControlReleaseD, compu {phys=raw for raw 0..65535; unit Unit_None}, range phys 0..65535 Unit_None, raw 0..65535, unit=Unit_None  # This signal is used to allow an ECU to start an update session. As this is a critical point, 2 components have to approve this
          signal OruControlStateD_XIX_ORU_Control_D_01_XIX_BMC_CAN01: start 40, 8 bit, little-endian, data-type-policy=OVERRIDE, i-signal-type=PRIMITIVE, init-value=0, base-type=BT_OruControlStateD, invalid-value=Invalid_OruControlStateD_XIX_ORU_Control_D_01_XIX_BMC_CAN01:129, compu {0=Cx0_Idle (CM_OruControlStateD_Cx0_Idle), 1=Cx1_Check (CM_OruControlStateD_Cx1_Check), 3=Cx3_DataPresent (CM_OruControlStateD_Cx3_DataPresent), 7=Cx7_LockActive (CM_OruControlStateD_Cx7_LockActive), 15=Cxf_Running (CM_OruControlStateD_Cxf_Running), 31=Cx1f_Save (CM_OruControlStateD_Cx1f_Save), 63=Cx3f_Done (CM_OruControlStateD_Cx3f_Done), 65=Cx41_Fail (CM_OruControlStateD_Cx41_Fail), 129=Cx81_Fehler (CM_OruControlStateD_Cx81_Fehler)}, range raw 0..129  # This signal is used to allow an ECU to start an update session.
          signal OruReleasePartitionSwitchD_XIX_ORU_Control_D_01_XIX_BMC_CAN01: start 48, 2 bit, little-endian, data-type-policy=OVERRIDE, i-signal-type=PRIMITIVE, init-value=0, base-type=BT_OruReleasePartitionSwitchD, invalid-value=Invalid_OruReleasePartitionSwitchD_XIX_ORU_Control_D_01_XIX_BMC_CAN01:3, compu {0=Cx0_Init (CM_OruReleasePartitionSwitchD_Cx0_Init), 1=Cx1_Lock (CM_OruReleasePartitionSwitchD_Cx1_Lock), 2=Cx2_Release (CM_OruReleasePartitionSwitchD_Cx2_Release), 3=Cx3_Fehler (CM_OruReleasePartitionSwitchD_Cx3_Fehler)}, range raw 0..3  # Release to switch the partition in case of an A/B partition update
          signal OruHostUpdateD_XIX_ORU_Control_D_01_XIX_BMC_CAN01: start 50, 3 bit, little-endian, data-type-policy=OVERRIDE, i-signal-type=PRIMITIVE, init-value=0, base-type=BT_OruHostUpdateD, invalid-value=Invalid_OruHostUpdateD_XIX_ORU_Control_D_01_XIX_BMC_CAN01:4, compu {0=Cx0_Init (CM_OruHostUpdateD_Cx0_Init), 1=Cx1_HostControl1 (CM_OruHostUpdateD_Cx1_HostControl1), 2=Cx2_HostControl2 (CM_OruHostUpdateD_Cx2_HostControl2), 3=Cx3_HostControlOther (CM_OruHostUpdateD_Cx3_HostControlOther), 4=Cx4_Fehler (CM_OruHostUpdateD_Cx4_Fehler)}, range raw 0..4  # Releases an update of an critical funcion's host (due to functional safety)
          mapping SG_ORU_Control_D_01_XIX_BMC_CAN01: i-signal-group=SG_ORU_Control_D_01_XIX_BMC_CAN01, transfer-property=PENDING
          signal ISignalVoid_ORU_Control_D_01_XIX_BMC_CAN01_0: start 53, 3 bit, little-endian, system signal SignalVoid_ORU_Control_D_01_0, data-type-policy=OVERRIDE, i-signal-type=PRIMITIVE, base-type=BT_SignalVoid
          signal ISignalVoid_ORU_Control_D_01_XIX_BMC_CAN01_1: start 56, 8 bit, little-endian, system signal SignalVoid_ORU_Control_D_01_1, data-type-policy=OVERRIDE, i-signal-type=PRIMITIVE, base-type=BT_SignalVoid
      frame OTAMC_D_01_XIX_BMC_CAN01: id 0x16A95596, from BMC_HV, frame-length=4, can-addressing-mode=EXTENDED, can-frame-rx-behavior=CAN-20, can-frame-tx-behavior=CAN-20
        pdu OTAMC_D_01_XIX_BMC_CAN01: length=4, transmission-mode-true-timing=cyclic-timing={time-offset=0, time-period=0.32}, unused-bit-pattern=0
          signal OTAMC_D_01_CRC_XIX_OTAMC_D_01_XIX_BMC_CAN01: start 0, 8 bit, little-endian, data-type-policy=OVERRIDE, i-signal-type=PRIMITIVE, init-value=0, base-type=BT_OTAMC_D_01_CRC, compu {phys=raw for raw 0..255}, range phys 0..255, raw 0..255
          signal OTAMC_D_01_BZ_XIX_OTAMC_D_01_XIX_BMC_CAN01: start 8, 4 bit, little-endian, data-type-policy=OVERRIDE, i-signal-type=PRIMITIVE, init-value=0, base-type=BT_OTAMC_D_01_BZ, compu {phys=raw for raw 0..15}, range phys 0..15, raw 0..15
          signal VehicleProtectedEnvironment_D_XIX_OTAMC_D_01_XIX_BMC_CAN01: start 12, 2 bit, little-endian, data-type-policy=OVERRIDE, i-signal-type=PRIMITIVE, init-value=0, base-type=BT_VehicleProtectedEnvironment_D, compu {0=Cx0_VPE_none (CM_VehicleProtectedEnvironment_D_Cx0_VPE_none), 1=Cx1_VPE_production (CM_VehicleProtectedEnvironment_D_Cx1_VPE_production), 2=Cx2_VPE_aftersales (CM_VehicleProtectedEnvironment_D_Cx2_VPE_aftersales)}, range raw 0..2  # Environment of vehicle in case of Remote Production
          mapping SG_OTAMC_D_01_XIX_BMC_CAN01: i-signal-group=SG_OTAMC_D_01_XIX_BMC_CAN01, transfer-property=PENDING
          signal ISignalVoid_OTAMC_D_01_XIX_BMC_CAN01_0: start 14, 2 bit, little-endian, system signal SignalVoid_OTAMC_D_01_0, data-type-policy=OVERRIDE, i-signal-type=PRIMITIVE, base-type=BT_SignalVoid
          signal ISignalVoid_OTAMC_D_01_XIX_BMC_CAN01_1: start 16, 8 bit, little-endian, system signal SignalVoid_OTAMC_D_01_1, data-type-policy=OVERRIDE, i-signal-type=PRIMITIVE, base-type=BT_SignalVoid
          signal ISignalVoid_OTAMC_D_01_XIX_BMC_CAN01_2: start 24, 8 bit, little-endian, system signal SignalVoid_OTAMC_D_01_2, data-type-policy=OVERRIDE, i-signal-type=PRIMITIVE, base-type=BT_SignalVoid
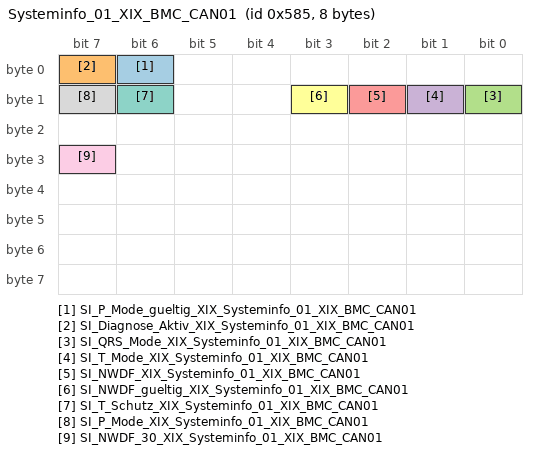
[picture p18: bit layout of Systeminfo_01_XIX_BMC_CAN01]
      frame Systeminfo_01_XIX_BMC_CAN01: id 0x585, from BMC_HV, frame-length=8, can-addressing-mode=STANDARD, can-frame-rx-behavior=CAN-20, can-frame-tx-behavior=CAN-20
        pdu Systeminfo_01_XIX_BMC_CAN01: length=8, minimum-delay=0.01, transmission-mode-true-timing={cyclic-timing={time-offset=0, time-period=1}, event-controlled-timing={number-of-repetitions=0, repetition-period=0}}, unused-bit-pattern=0  # MQB, MLBevo
          signal SI_P_Mode_gueltig_XIX_Systeminfo_01_XIX_BMC_CAN01: start 6, 1 bit, little-endian, data-type-policy=OVERRIDE, i-signal-type=PRIMITIVE, init-value=0, base-type=BT_SI_P_Mode_gueltig, compu {0=Cx0_dezentraler_Produktionsmode (CM_SI_P_Mode_gueltig_Cx0_dezentraler_Produktionsmode), 1=Cx1_zentraler_Produktionsmode (CM_SI_P_Mode_gueltig_Cx1_zentraler_Produktionsmode)}, range raw 0..1, transfer-property=PENDING  # zeigt an, ob es sich um ein Fahrzeug mit zentraler oder dezentraler Steu-erung des Produktionsmodes handelt Siehe Q-LAH Produktionsmode (LAH.DUM.907.AS)
          signal SI_Diagnose_Aktiv_XIX_Systeminfo_01_XIX_BMC_CAN01: start 7, 1 bit, little-endian, data-type-policy=OVERRIDE, i-signal-type=PRIMITIVE, init-value=0, base-type=BT_SI_Diagnose_Aktiv, compu {0=Cx0_inaktiv (CM_SI_Diagnose_Aktiv_Cx0_inaktiv), 1=Cx1_aktiv (CM_SI_Diagnose_Aktiv_Cx1_aktiv)}, range raw 0..1, transfer-property=PENDING  # Gibt an ob Diagnose-Botschaften empfangen werden und somit eine Diagnose aktiv ist. MQB: Gibt an ob Diagnose-Bus Botschaften empfangen werden und somit eine Diagnose aktiv ist.
          signal SI_QRS_Mode_XIX_Systeminfo_01_XIX_BMC_CAN01: start 8, 1 bit, little-endian, data-type-policy=OVERRIDE, i-signal-type=PRIMITIVE, init-value=0, base-type=BT_SI_QRS_Mode, compu {0=Cx0_QRS_Messmodus_nicht_aktiv (CM_SI_QRS_Mode_Cx0_QRS_Messmodus_nicht_aktiv), 1=Cx1_QRS_Messmodus_aktiv (CM_SI_QRS_Mode_Cx1_QRS_Messmodus_aktiv)}, range raw 0..1, transfer-property=PENDING  # Messmodus Quick-Ruhestrom
          signal SI_T_Mode_XIX_Systeminfo_01_XIX_BMC_CAN01: start 9, 1 bit, little-endian, data-type-policy=OVERRIDE, i-signal-type=PRIMITIVE, init-value=0, base-type=BT_SI_T_Mode, compu {0=Cx0_Transportmodus_nicht_aktiv (CM_SI_T_Mode_Cx0_Transportmodus_nicht_aktiv), 1=Cx1_Transportmodus_aktiv (CM_SI_T_Mode_Cx1_Transportmodus_aktiv)}, range raw 0..1, transfer-property=PENDING  # 0x0: Transportmodus nicht aktiv 0x1: Transportmodus aktiv
          signal SI_NWDF_XIX_Systeminfo_01_XIX_BMC_CAN01: start 10, 1 bit, little-endian, data-type-policy=OVERRIDE, i-signal-type=PRIMITIVE, init-value=0, base-type=BT_SI_NWDF, compu {0=Cx0_Ueberwachung_nicht_freigegeben (CM_SI_NWDF_Cx0_Ueberwachung_nicht_freigegeben), 1=Cx1_Ueberwachung_freigegeben (CM_SI_NWDF_Cx1_Ueberwachung_freigegeben)}, range raw 0..1, transfer-property=TRIGGERED-ON-CHANGE-WITHOUT-REPETITION  # Netzwerk-Diagnose Freigebe zur zentralen Aktivierung der Netzwerkdiagnose
          signal SI_NWDF_gueltig_XIX_Systeminfo_01_XIX_BMC_CAN01: start 11, 1 bit, little-endian, data-type-policy=OVERRIDE, i-signal-type=PRIMITIVE, init-value=1, base-type=BT_SI_NWDF_gueltig, compu {0=Cx0_NWDF_wird_nicht_unterstuetzt (CM_SI_NWDF_gueltig_Cx0_NWDF_wird_nicht_unterstuetzt), 1=Cx1_NWDF_wird_unterstuetzt (CM_SI_NWDF_gueltig_Cx1_NWDF_wird_unterstuetzt)}, range raw 0..1, transfer-property=PENDING  # Gültigkeitsbit zu SI_NWDF gemäß Lastenheft: Zentrale Aktivierung Netzwerkdiagnose
          signal SI_T_Schutz_XIX_Systeminfo_01_XIX_BMC_CAN01: start 14, 1 bit, little-endian, data-type-policy=OVERRIDE, i-signal-type=PRIMITIVE, init-value=0, base-type=BT_SI_T_Schutz, compu {0=Cx0_Transportschutz_nicht_aktiv (CM_SI_T_Schutz_Cx0_Transportschutz_nicht_aktiv), 1=Cx1_Transportschutz_aktiv (CM_SI_T_Schutz_Cx1_Transportschutz_aktiv)}, range raw 0..1, transfer-property=PENDING  # Transportschutz-Signal, das bei Transportmodus und Motorlauf aktiv bleibt 0x0: Transportschutz nicht aktiv 0x1: Transportschutz aktiv
          signal SI_P_Mode_XIX_Systeminfo_01_XIX_BMC_CAN01: start 15, 1 bit, little-endian, data-type-policy=OVERRIDE, i-signal-type=PRIMITIVE, init-value=0, base-type=BT_SI_P_Mode, compu {0=Cx0_inaktiv (CM_SI_P_Mode_Cx0_inaktiv), 1=Cx1_aktiv (CM_SI_P_Mode_Cx1_aktiv)}, range raw 0..1, transfer-property=PENDING  # Zentrale Steuerung des Produktionsmodes gemäß Q-LAH-Produktionsmode (LAH.DUM.907.AS)
          signal SI_NWDF_30_XIX_Systeminfo_01_XIX_BMC_CAN01: start 31, 1 bit, little-endian, data-type-policy=OVERRIDE, i-signal-type=PRIMITIVE, init-value=0, base-type=BT_SI_NWDF_30, compu {0=Cx0_Ueberwachung_nicht_freigegeben (CM_SI_NWDF_30_Cx0_Ueberwachung_nicht_freigegeben), 1=Cx1_Ueberwachung_freigegeben (CM_SI_NWDF_30_Cx1_Ueberwachung_freigegeben)}, range raw 0..1, transfer-property=TRIGGERED-ON-CHANGE-WITHOUT-REPETITION  # Netzwerk-Diagnose Freigabe zur zentralen Aktivierung der Netzwerkdiagnose (keine Ausblendbedingung aktiv)
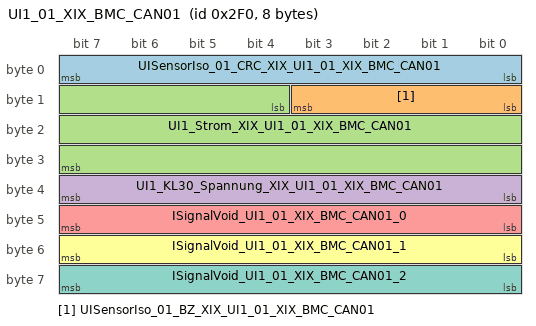
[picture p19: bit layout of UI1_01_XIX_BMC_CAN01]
      frame UI1_01_XIX_BMC_CAN01: id 0x2F0, to BMC_HV, frame-length=8, can-addressing-mode=STANDARD, can-frame-rx-behavior=CAN-20, can-frame-tx-behavior=CAN-20
        pdu UI1_01_XIX_BMC_CAN01_E2E: length=8, transmission-mode-true-timing=event-controlled-timing={number-of-repetitions=0, repetition-period=0}, unused-bit-pattern=0  # Fuer die Botschaft ist das Cyclic-Timing 0.01 zu verwenden.
          signal UISensorIso_01_CRC_XIX_UI1_01_XIX_BMC_CAN01: start 0, 8 bit, little-endian, data-type-policy=OVERRIDE, i-signal-type=PRIMITIVE, init-value=0, base-type=BT_UISensorIso_01_CRC, compu {phys=raw for raw 0..255}, range phys 0..255, raw 0..255, to BMC_HV(timeout 0.5 s)
          signal UISensorIso_01_BZ_XIX_UI1_01_XIX_BMC_CAN01: start 8, 4 bit, little-endian, data-type-policy=OVERRIDE, i-signal-type=PRIMITIVE, init-value=0, base-type=BT_UISensorIso_01_BZ, compu {phys=raw for raw 0..15}, range phys 0..15, raw 0..15, to BMC_HV(timeout 0.5 s)
          signal UI1_Strom_XIX_UI1_01_XIX_BMC_CAN01: start 12, 20 bit, little-endian, data-type-policy=OVERRIDE, i-signal-type=PRIMITIVE, init-value=1048574, base-type=BT_UI1_Strom, invalid-value=Invalid_UI1_Strom_XIX_UI1_01_XIX_BMC_CAN01:1048575, compu {phys=raw*0.005-2621 for raw 0..1048573, 1048574=Cxffffe_Init (CM_UI1_Strom_Cxffffe_Init), 1048575=Cxfffff_Fehler (CM_UI1_Strom_Cxfffff_Fehler); unit Unit_Amper}, range phys -2621..2621.865 Unit_Amper, raw 0..1048575, unit=Unit_Amper, to BMC_HV(timeout 0.5 s)  # Momentanwert: Batteriestrom
          signal UI1_KL30_Spannung_XIX_UI1_01_XIX_BMC_CAN01: start 32, 8 bit, little-endian, data-type-policy=OVERRIDE, i-signal-type=PRIMITIVE, init-value=254, base-type=BT_UI1_KL30_Spannung, invalid-value=Invalid_UI1_KL30_Spannung_XIX_UI1_01_XIX_BMC_CAN01:255, compu {phys=raw*0.1 for raw 0..253, 254=Cxfe_Init (CM_UI1_KL30_Spannung_Cxfe_Init), 255=Cxff_Fehler (CM_UI1_KL30_Spannung_Cxff_Fehler); unit Unit_Volt}, range phys 0..25.3 Unit_Volt, raw 0..255, unit=Unit_Volt, to BMC_HV(timeout 0.5 s)  # Momentanwert: gemessene Klemme30-Spannung am UI-Sensor
          signal ISignalVoid_UI1_01_XIX_BMC_CAN01_0: start 40, 8 bit, little-endian, system signal SignalVoid_UI1_01_0, data-type-policy=OVERRIDE, i-signal-type=PRIMITIVE, base-type=BT_SignalVoid
          signal ISignalVoid_UI1_01_XIX_BMC_CAN01_1: start 48, 8 bit, little-endian, system signal SignalVoid_UI1_01_1, data-type-policy=OVERRIDE, i-signal-type=PRIMITIVE, base-type=BT_SignalVoid
          signal ISignalVoid_UI1_01_XIX_BMC_CAN01_2: start 56, 8 bit, little-endian, system signal SignalVoid_UI1_01_2, data-type-policy=OVERRIDE, i-signal-type=PRIMITIVE, base-type=BT_SignalVoid
          mapping SG_UI1_01_XIX_BMC_CAN01: i-signal-group=SG_UI1_01_XIX_BMC_CAN01, transfer-property=TRIGGERED-WITHOUT-REPETITION
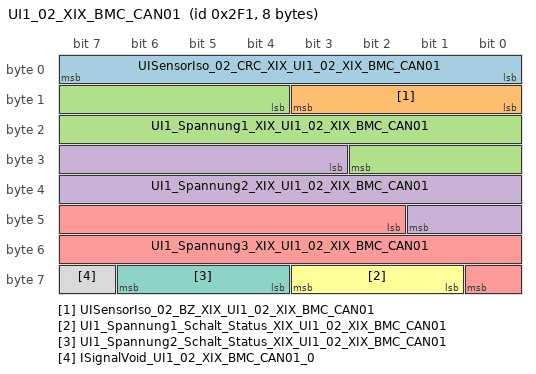
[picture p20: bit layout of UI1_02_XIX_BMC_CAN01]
      frame UI1_02_XIX_BMC_CAN01: id 0x2F1, to BMC_HV, frame-length=8, can-addressing-mode=STANDARD, can-frame-rx-behavior=CAN-20, can-frame-tx-behavior=CAN-20
        pdu UI1_02_XIX_BMC_CAN01_E2E: length=8, transmission-mode-true-timing=event-controlled-timing={number-of-repetitions=0, repetition-period=0}, unused-bit-pattern=0  # Fuer die Botschaft ist das Cyclic-Timing 0.01 zu verwenden.
          signal UISensorIso_02_CRC_XIX_UI1_02_XIX_BMC_CAN01: start 0, 8 bit, little-endian, data-type-policy=OVERRIDE, i-signal-type=PRIMITIVE, init-value=0, base-type=BT_UISensorIso_02_CRC, compu {phys=raw for raw 0..255}, range phys 0..255, raw 0..255, to BMC_HV(timeout 0.5 s)
          signal UISensorIso_02_BZ_XIX_UI1_02_XIX_BMC_CAN01: start 8, 4 bit, little-endian, data-type-policy=OVERRIDE, i-signal-type=PRIMITIVE, init-value=0, base-type=BT_UISensorIso_02_BZ, compu {phys=raw for raw 0..15}, range phys 0..15, raw 0..15, to BMC_HV(timeout 0.5 s)
          signal UI1_Spannung1_XIX_UI1_02_XIX_BMC_CAN01: start 12, 15 bit, little-endian, data-type-policy=OVERRIDE, i-signal-type=PRIMITIVE, init-value=32766, base-type=BT_UI1_Spannung1, invalid-value=Invalid_UI1_Spannung1_XIX_UI1_02_XIX_BMC_CAN01:32767, compu {phys=raw*0.0625-1023 for raw 0..32763, 32764=Cx7ffc_nicht_messbar (CM_UI1_Spannung1_Cx7ffc_nicht_messbar), 32765=Cx7ffd_nicht_verfuegbar (CM_UI1_Spannung1_Cx7ffd_nicht_verfuegbar), 32766=Cx7ffe_Init (CM_UI1_Spannung1_Cx7ffe_Init), 32767=Cx7fff_Fehler (CM_UI1_Spannung1_Cx7fff_Fehler); unit Unit_Volt}, range phys -1023..1024.6875 Unit_Volt, raw 0..32767, unit=Unit_Volt, to BMC_HV(timeout 0.5 s)  # Spannungsmesskanal 1
          signal UI1_Spannung2_XIX_UI1_02_XIX_BMC_CAN01: start 27, 15 bit, little-endian, data-type-policy=OVERRIDE, i-signal-type=PRIMITIVE, init-value=32766, base-type=BT_UI1_Spannung2, invalid-value=Invalid_UI1_Spannung2_XIX_UI1_02_XIX_BMC_CAN01:32767, compu {phys=raw*0.0625-1023 for raw 0..32763, 32764=Cx7ffc_nicht_messbar (CM_UI1_Spannung2_Cx7ffc_nicht_messbar), 32765=Cx7ffd_nicht_verfuegbar (CM_UI1_Spannung2_Cx7ffd_nicht_verfuegbar), 32766=Cx7ffe_Init (CM_UI1_Spannung2_Cx7ffe_Init), 32767=Cx7fff_Fehler (CM_UI1_Spannung2_Cx7fff_Fehler); unit Unit_Volt}, range phys -1023..1024.6875 Unit_Volt, raw 0..32767, unit=Unit_Volt, to BMC_HV(timeout 0.5 s)  # Spannungsmesskanal 2
          signal UI1_Spannung3_XIX_UI1_02_XIX_BMC_CAN01: start 42, 15 bit, little-endian, data-type-policy=OVERRIDE, i-signal-type=PRIMITIVE, init-value=32766, base-type=BT_UI1_Spannung3, invalid-value=Invalid_UI1_Spannung3_XIX_UI1_02_XIX_BMC_CAN01:32767, compu {phys=raw*0.0625-1023 for raw 0..32763, 32764=Cx7ffc_nicht_messbar (CM_UI1_Spannung3_Cx7ffc_nicht_messbar), 32765=Cx7ffd_nicht_verfuegbar (CM_UI1_Spannung3_Cx7ffd_nicht_verfuegbar), 32766=Cx7ffe_Init (CM_UI1_Spannung3_Cx7ffe_Init), 32767=Cx7fff_Fehler (CM_UI1_Spannung3_Cx7fff_Fehler); unit Unit_Volt}, range phys -1023..1024.6875 Unit_Volt, raw 0..32767, unit=Unit_Volt, to BMC_HV(timeout 0.5 s)  # Spannungsmesskanal 3
          signal UI1_Spannung1_Schalt_Status_XIX_UI1_02_XIX_BMC_CAN01: start 57, 3 bit, little-endian, data-type-policy=OVERRIDE, i-signal-type=PRIMITIVE, init-value=6, base-type=BT_UI1_Spannung1_Schalt_Status, invalid-value=Invalid_UI1_Spannung1_Schalt_Status_XIX_UI1_02_XIX_BMC_CAN01:7, compu {0=Cx0_offen (CM_UI1_Spannung1_Schalt_Status_Cx0_offen), 1=Cx1_geschlossen (CM_UI1_Spannung1_Schalt_Status_Cx1_geschlossen), 2=Cx2_defekt_geschlossen (CM_UI1_Spannung1_Schalt_Status_Cx2_defekt_geschlossen), 3=Cx3_defekt_offen (CM_UI1_Spannung1_Schalt_Status_Cx3_defekt_offen), 4=Cx4_nicht_schaltbar (CM_UI1_Spannung1_Schalt_Status_Cx4_nicht_schaltbar), 6=Cx6_Init (CM_UI1_Spannung1_Schalt_Status_Cx6_Init), 7=Cx7_Fehler (CM_UI1_Spannung1_Schalt_Status_Cx7_Fehler)}, range raw 0..7, to BMC_HV(timeout 0.5 s)  # Status des abschaltbaren Spannungsmesskanal1
          signal UI1_Spannung2_Schalt_Status_XIX_UI1_02_XIX_BMC_CAN01: start 60, 3 bit, little-endian, data-type-policy=OVERRIDE, i-signal-type=PRIMITIVE, init-value=6, base-type=BT_UI1_Spannung2_Schalt_Status, invalid-value=Invalid_UI1_Spannung2_Schalt_Status_XIX_UI1_02_XIX_BMC_CAN01:7, compu {0=Cx0_offen (CM_UI1_Spannung2_Schalt_Status_Cx0_offen), 1=Cx1_geschlossen (CM_UI1_Spannung2_Schalt_Status_Cx1_geschlossen), 2=Cx2_defekt_geschlossen (CM_UI1_Spannung2_Schalt_Status_Cx2_defekt_geschlossen), 3=Cx3_defekt_offen (CM_UI1_Spannung2_Schalt_Status_Cx3_defekt_offen), 4=Cx4_nicht_schaltbar (CM_UI1_Spannung2_Schalt_Status_Cx4_nicht_schaltbar), 6=Cx6_Init (CM_UI1_Spannung2_Schalt_Status_Cx6_Init), 7=Cx7_Fehler (CM_UI1_Spannung2_Schalt_Status_Cx7_Fehler)}, range raw 0..7, to BMC_HV(timeout 0.5 s)  # Status des abschaltbaren Spannungsmesskanal2
          signal ISignalVoid_UI1_02_XIX_BMC_CAN01_0: start 63, 1 bit, little-endian, system signal SignalVoid_UI1_02_0, data-type-policy=OVERRIDE, i-signal-type=PRIMITIVE, base-type=BT_SignalVoid
          mapping SG_UI1_02_XIX_BMC_CAN01: i-signal-group=SG_UI1_02_XIX_BMC_CAN01, transfer-property=TRIGGERED-WITHOUT-REPETITION
      frame UI1_03_XIX_BMC_CAN01: id 0x2F2, to BMC_HV, frame-length=8, can-addressing-mode=STANDARD, can-frame-rx-behavior=CAN-20, can-frame-tx-behavior=CAN-20
        pdu UI1_03_XIX_BMC_CAN01: length=8, transmission-mode-true-timing=cyclic-timing={time-offset=0, time-period=0.01}, unused-bit-pattern=0
          signal UI1_Spannung4_XIX_UI1_03_XIX_BMC_CAN01: start 12, 15 bit, little-endian, data-type-policy=OVERRIDE, i-signal-type=PRIMITIVE, init-value=32766, base-type=BT_UI1_Spannung4, invalid-value=Invalid_UI1_Spannung4_XIX_UI1_03_XIX_BMC_CAN01:32767, compu {phys=raw*0.0625-1023 for raw 0..32763, 32764=Cx7ffc_nicht_messbar (CM_UI1_Spannung4_Cx7ffc_nicht_messbar), 32765=Cx7ffd_nicht_verfuegbar (CM_UI1_Spannung4_Cx7ffd_nicht_verfuegbar), 32766=Cx7ffe_Init (CM_UI1_Spannung4_Cx7ffe_Init), 32767=Cx7fff_Fehler (CM_UI1_Spannung4_Cx7fff_Fehler); unit Unit_Volt}, range phys -1023..1024.6875 Unit_Volt, raw 0..32767, unit=Unit_Volt, transfer-property=PENDING, to BMC_HV(timeout 0.5 s)  # Spannungsmesskanal 4
          signal UI1_Spannung5_XIX_UI1_03_XIX_BMC_CAN01: start 27, 15 bit, little-endian, data-type-policy=OVERRIDE, i-signal-type=PRIMITIVE, init-value=32766, base-type=BT_UI1_Spannung5, invalid-value=Invalid_UI1_Spannung5_XIX_UI1_03_XIX_BMC_CAN01:32767, compu {phys=raw*0.0625-1023 for raw 0..32763, 32764=Cx7ffc_nicht_messbar (CM_UI1_Spannung5_Cx7ffc_nicht_messbar), 32765=Cx7ffd_nicht_verfuegbar (CM_UI1_Spannung5_Cx7ffd_nicht_verfuegbar), 32766=Cx7ffe_Init (CM_UI1_Spannung5_Cx7ffe_Init), 32767=Cx7fff_Fehler (CM_UI1_Spannung5_Cx7fff_Fehler); unit Unit_Volt}, range phys -1023..1024.6875 Unit_Volt, raw 0..32767, unit=Unit_Volt, transfer-property=PENDING, to BMC_HV(timeout 0.5 s)  # Spannungsmesskanal 5
          signal UI1_Spannung6_XIX_UI1_03_XIX_BMC_CAN01: start 42, 15 bit, little-endian, data-type-policy=OVERRIDE, i-signal-type=PRIMITIVE, init-value=32766, base-type=BT_UI1_Spannung6, invalid-value=Invalid_UI1_Spannung6_XIX_UI1_03_XIX_BMC_CAN01:32767, compu {phys=raw*0.0625-1023 for raw 0..32763, 32764=Cx7ffc_nicht_messbar (CM_UI1_Spannung6_Cx7ffc_nicht_messbar), 32765=Cx7ffd_nicht_verfuegbar (CM_UI1_Spannung6_Cx7ffd_nicht_verfuegbar), 32766=Cx7ffe_Init (CM_UI1_Spannung6_Cx7ffe_Init), 32767=Cx7fff_Fehler (CM_UI1_Spannung6_Cx7fff_Fehler); unit Unit_Volt}, range phys -1023..1024.6875 Unit_Volt, raw 0..32767, unit=Unit_Volt, transfer-property=PENDING, to BMC_HV(timeout 0.5 s)  # Spannungsmesskanal 6
      frame UI1_04_XIX_BMC_CAN01: id 0x12DD545C, to BMC_HV, frame-length=8, can-addressing-mode=EXTENDED, can-frame-rx-behavior=CAN-20, can-frame-tx-behavior=CAN-20
        pdu UI1_04_XIX_BMC_CAN01: length=8, transmission-mode-true-timing=cyclic-timing={time-offset=0, time-period=0.1}, unused-bit-pattern=0
          signal UI2Sens01_ErrMem_State_XIX_UI1_04_XIX_BMC_CAN01: start 13, 2 bit, little-endian, data-type-policy=OVERRIDE, i-signal-type=PRIMITIVE, init-value=2, base-type=BT_UI2Sens01_ErrMem_State, compu {1=Cx1_ErrMem_Active (CM_UI2Sens01_ErrMem_State_Cx1_ErrMem_Active), 2=Cx2_ErrMem_Init_Progress (CM_UI2Sens01_ErrMem_State_Cx2_ErrMem_Init_Progress), 3=Cx3_ErrMem_Init_Done (CM_UI2Sens01_ErrMem_State_Cx3_ErrMem_Init_Done)}, range raw 1..3, transfer-property=PENDING, to BMC_HV(timeout 1 s)  # Error Memory State
          signal UI1_Status_XIX_UI1_04_XIX_BMC_CAN01: start 15, 1 bit, little-endian, data-type-policy=OVERRIDE, i-signal-type=PRIMITIVE, init-value=0, base-type=BT_UI1_Status, compu {0=Cx0_Init (CM_UI1_Status_Cx0_Init), 1=Cx1_Aktiv (CM_UI1_Status_Cx1_Aktiv)}, range raw 0..1, transfer-property=PENDING, to BMC_HV(timeout 1 s)  # dient zur Signalisierung Neustart oder Reset des UI-Sensors
          signal UI1_Temperatur_2_XIX_UI1_04_XIX_BMC_CAN01: start 16, 8 bit, little-endian, data-type-policy=OVERRIDE, i-signal-type=PRIMITIVE, init-value=254, base-type=BT_UI1_Temperatur_2, invalid-value=Invalid_UI1_Temperatur_2_XIX_UI1_04_XIX_BMC_CAN01:255, compu {phys=raw-40 for raw 0..252, 253=Cxfd_nicht_vorhanden (CM_UI1_Temperatur_2_Cxfd_nicht_vorhanden), 254=Cxfe_Init (CM_UI1_Temperatur_2_Cxfe_Init), 255=Cxff_Fehler (CM_UI1_Temperatur_2_Cxff_Fehler); unit Unit_DegreCelsi}, range phys -40..212 Unit_DegreCelsi, raw 0..255, unit=Unit_DegreCelsi, transfer-property=PENDING, to BMC_HV(timeout 1 s)  # Temperatur 2
          signal UI1_Temperatur_1_XIX_UI1_04_XIX_BMC_CAN01: start 24, 8 bit, little-endian, data-type-policy=OVERRIDE, i-signal-type=PRIMITIVE, init-value=254, base-type=BT_UI1_Temperatur_1, invalid-value=Invalid_UI1_Temperatur_1_XIX_UI1_04_XIX_BMC_CAN01:255, compu {phys=raw-40 for raw 0..252, 253=Cxfd_nicht_vorhanden (CM_UI1_Temperatur_1_Cxfd_nicht_vorhanden), 254=Cxfe_Init (CM_UI1_Temperatur_1_Cxfe_Init), 255=Cxff_Fehler (CM_UI1_Temperatur_1_Cxff_Fehler); unit Unit_DegreCelsi}, range phys -40..212 Unit_DegreCelsi, raw 0..255, unit=Unit_DegreCelsi, transfer-property=PENDING, to BMC_HV(timeout 1 s)  # Temperatur 1
          signal UI1_Stromintegral_Laden_XIX_UI1_04_XIX_BMC_CAN01: start 32, 16 bit, little-endian, data-type-policy=OVERRIDE, i-signal-type=PRIMITIVE, init-value=65534, base-type=BT_UI1_Stromintegral_Laden, invalid-value=Invalid_UI1_Stromintegral_Laden_XIX_UI1_04_XIX_BMC_CAN01:65535, compu {phys=raw for raw 0..65533, 65534=Cxfffe_Init (CM_UI1_Stromintegral_Laden_Cxfffe_Init), 65535=Cxffff_Fehler (CM_UI1_Stromintegral_Laden_Cxffff_Fehler); unit Unit_AmperSecon}, range phys 0..65533 Unit_AmperSecon, raw 0..65535, unit=Unit_AmperSecon, transfer-property=PENDING, to BMC_HV(timeout 1 s)  # Ladungszaehler des UI1 Sensors fuer Laden
          signal UI1_Stromintegral_Entladen_XIX_UI1_04_XIX_BMC_CAN01: start 48, 16 bit, little-endian, data-type-policy=OVERRIDE, i-signal-type=PRIMITIVE, init-value=65534, base-type=BT_UI1_Stromintegral_Entladen, invalid-value=Invalid_UI1_Stromintegral_Entladen_XIX_UI1_04_XIX_BMC_CAN01:65535, compu {phys=raw for raw 0..65533, 65534=Cxfffe_Init (CM_UI1_Stromintegral_Entladen_Cxfffe_Init), 65535=Cxffff_Fehler (CM_UI1_Stromintegral_Entladen_Cxffff_Fehler); unit Unit_AmperSecon}, range phys 0..65533 Unit_AmperSecon, raw 0..65535, unit=Unit_AmperSecon, transfer-property=PENDING, to BMC_HV(timeout 1 s)  # Ladungszaehler des UI1 Sensors fuer Entladen
      frame UI1_05_XIX_BMC_CAN01: id 0x12DD545D, to BMC_HV, frame-length=8, can-addressing-mode=EXTENDED, can-frame-rx-behavior=CAN-20, can-frame-tx-behavior=CAN-20
        pdu UI1_05_XIX_BMC_CAN01: length=8, transmission-mode-true-timing=cyclic-timing={time-offset=0, time-period=0.1}, unused-bit-pattern=0
          signal UI1_Iso_Status_XIX_UI1_05_XIX_BMC_CAN01: start 29, 3 bit, little-endian, data-type-policy=OVERRIDE, i-signal-type=PRIMITIVE, init-value=0, base-type=BT_UI1_Iso_Status, invalid-value=Invalid_UI1_Iso_Status_XIX_UI1_05_XIX_BMC_CAN01:1, compu {0=Cx0_Init (CM_UI1_Iso_Status_Cx0_Init), 1=Cx1_Fehler (CM_UI1_Iso_Status_Cx1_Fehler), 2=Cx2_zyklisch (CM_UI1_Iso_Status_Cx2_zyklisch), 3=Cx3_Einzelmessung (CM_UI1_Iso_Status_Cx3_Einzelmessung), 4=Cx4_Schnellmessung (CM_UI1_Iso_Status_Cx4_Schnellmessung), 5=Cx5_Aus (CM_UI1_Iso_Status_Cx5_Aus)}, range raw 0..5, transfer-property=PENDING, to BMC_HV(timeout 1 s)  # Rueckmeldung Status Isolationswaechter
          signal UI1_Iso_Pos_XIX_UI1_05_XIX_BMC_CAN01: start 32, 16 bit, little-endian, data-type-policy=OVERRIDE, i-signal-type=PRIMITIVE, init-value=65534, base-type=BT_UI1_Iso_Pos, invalid-value=Invalid_UI1_Iso_Pos_XIX_UI1_05_XIX_BMC_CAN01:65535, compu {phys=raw*100 for raw 0..65532, 65533=Cxfffd_nicht_verfuegbar (CM_UI1_Iso_Pos_Cxfffd_nicht_verfuegbar), 65534=Cxfffe_Init (CM_UI1_Iso_Pos_Cxfffe_Init), 65535=Cxffff_Fehler (CM_UI1_Iso_Pos_Cxffff_Fehler); unit Unit_Ohm}, range phys 0..6553200 Unit_Ohm, raw 0..65535, unit=Unit_Ohm, transfer-property=PENDING, to BMC_HV(timeout 1 s)  # Isolationswiderstandswert Plus
          signal UI1_Iso_Neg_XIX_UI1_05_XIX_BMC_CAN01: start 48, 16 bit, little-endian, data-type-policy=OVERRIDE, i-signal-type=PRIMITIVE, init-value=65534, base-type=BT_UI1_Iso_Neg, invalid-value=Invalid_UI1_Iso_Neg_XIX_UI1_05_XIX_BMC_CAN01:65535, compu {phys=raw*100 for raw 0..65532, 65533=Cxfffd_nicht_verfuegbar (CM_UI1_Iso_Neg_Cxfffd_nicht_verfuegbar), 65534=Cxfffe_Init (CM_UI1_Iso_Neg_Cxfffe_Init), 65535=Cxffff_Fehler (CM_UI1_Iso_Neg_Cxffff_Fehler); unit Unit_Ohm}, range phys 0..6553200 Unit_Ohm, raw 0..65535, unit=Unit_Ohm, transfer-property=PENDING, to BMC_HV(timeout 1 s)  # Isolationswiderstandswert Minus
      frame UI1_Komponentenfehler_01_XIX_BMC_CAN01: id 0x12DD551E, to BMC_HV, frame-length=8, can-addressing-mode=EXTENDED, can-frame-rx-behavior=CAN-20, can-frame-tx-behavior=CAN-20
        pdu UI1_Komponentenfehler_01_XIX_BMC_CAN01: length=8, transmission-mode-true-timing=cyclic-timing={time-offset=0, time-period=0.1}, unused-bit-pattern=0
          signal UI1_KompFehlerModus2_01_XIX_UI1_Komponentenfehler_01_XIX_BMC_CAN01: start 12, 2 bit, little-endian, data-type-policy=OVERRIDE, i-signal-type=PRIMITIVE, init-value=0, base-type=BT_UI1_KompFehlerModus2_01, compu {0=Cx0_TNCTOC (CM_UI1_KompFehlerModus2_01_Cx0_TNCTOC), 1=Cx1_TP_TC (CM_UI1_KompFehlerModus2_01_Cx1_TP_TC), 2=Cx2_TP_TC_WCMTL (CM_UI1_KompFehlerModus2_01_Cx2_TP_TC_WCMTL), 3=Cx3_TF_TC_Error (CM_UI1_KompFehlerModus2_01_Cx3_TF_TC_Error)}, range raw 0..3, transfer-property=PENDING, to BMC_HV(timeout 1 s)  # Uebertragung OBD relevanter Fehlerpfade vom Secondary zum Primary Steuergeraet. Zuordnung der generischen Komponentenfehler muss zwischen Sender und Empfaenger abgestimmt werden
          signal UI1_KompFehlerModus2_02_XIX_UI1_Komponentenfehler_01_XIX_BMC_CAN01: start 14, 2 bit, little-endian, data-type-policy=OVERRIDE, i-signal-type=PRIMITIVE, init-value=0, base-type=BT_UI1_KompFehlerModus2_02, compu {0=Cx0_TNCTOC (CM_UI1_KompFehlerModus2_02_Cx0_TNCTOC), 1=Cx1_TP_TC (CM_UI1_KompFehlerModus2_02_Cx1_TP_TC), 2=Cx2_TP_TC_WCMTL (CM_UI1_KompFehlerModus2_02_Cx2_TP_TC_WCMTL), 3=Cx3_TF_TC_Error (CM_UI1_KompFehlerModus2_02_Cx3_TF_TC_Error)}, range raw 0..3, transfer-property=PENDING, to BMC_HV(timeout 1 s)  # Uebertragung OBD relevanter Fehlerpfade vom Secondary zum Primary Steuergeraet. Zuordnung der generischen Komponentenfehler muss zwischen Sender und Empfaenger abgestimmt werden
          signal UI1_KompFehlerModus2_03_XIX_UI1_Komponentenfehler_01_XIX_BMC_CAN01: start 16, 2 bit, little-endian, data-type-policy=OVERRIDE, i-signal-type=PRIMITIVE, init-value=0, base-type=BT_UI1_KompFehlerModus2_03, compu {0=Cx0_TNCTOC (CM_UI1_KompFehlerModus2_03_Cx0_TNCTOC), 1=Cx1_TP_TC (CM_UI1_KompFehlerModus2_03_Cx1_TP_TC), 2=Cx2_TP_TC_WCMTL (CM_UI1_KompFehlerModus2_03_Cx2_TP_TC_WCMTL), 3=Cx3_TF_TC_Error (CM_UI1_KompFehlerModus2_03_Cx3_TF_TC_Error)}, range raw 0..3, transfer-property=PENDING, to BMC_HV(timeout 1 s)  # Uebertragung OBD relevanter Fehlerpfade vom Secondary zum Primary Steuergeraet. Zuordnung der generischen Komponentenfehler muss zwischen Sender und Empfaenger abgestimmt werden
          signal UI1_KompFehlerModus2_04_XIX_UI1_Komponentenfehler_01_XIX_BMC_CAN01: start 18, 2 bit, little-endian, data-type-policy=OVERRIDE, i-signal-type=PRIMITIVE, init-value=0, base-type=BT_UI1_KompFehlerModus2_04, compu {0=Cx0_TNCTOC (CM_UI1_KompFehlerModus2_04_Cx0_TNCTOC), 1=Cx1_TP_TC (CM_UI1_KompFehlerModus2_04_Cx1_TP_TC), 2=Cx2_TP_TC_WCMTL (CM_UI1_KompFehlerModus2_04_Cx2_TP_TC_WCMTL), 3=Cx3_TF_TC_Error (CM_UI1_KompFehlerModus2_04_Cx3_TF_TC_Error)}, range raw 0..3, transfer-property=PENDING, to BMC_HV(timeout 1 s)  # Uebertragung OBD relevanter Fehlerpfade vom Secondary zum Primary Steuergeraet. Zuordnung der generischen Komponentenfehler muss zwischen Sender und Empfaenger abgestimmt werden
          signal UI1_KompFehlerModus2_05_XIX_UI1_Komponentenfehler_01_XIX_BMC_CAN01: start 20, 2 bit, little-endian, data-type-policy=OVERRIDE, i-signal-type=PRIMITIVE, init-value=0, base-type=BT_UI1_KompFehlerModus2_05, compu {0=Cx0_TNCTOC (CM_UI1_KompFehlerModus2_05_Cx0_TNCTOC), 1=Cx1_TP_TC (CM_UI1_KompFehlerModus2_05_Cx1_TP_TC), 2=Cx2_TP_TC_WCMTL (CM_UI1_KompFehlerModus2_05_Cx2_TP_TC_WCMTL), 3=Cx3_TF_TC_Error (CM_UI1_KompFehlerModus2_05_Cx3_TF_TC_Error)}, range raw 0..3, transfer-property=PENDING, to BMC_HV(timeout 1 s)  # Uebertragung OBD relevanter Fehlerpfade vom Secondary zum Primary Steuergeraet. Zuordnung der generischen Komponentenfehler muss zwischen Sender und Empfaenger abgestimmt werden
          signal UI1_KompFehlerModus2_06_XIX_UI1_Komponentenfehler_01_XIX_BMC_CAN01: start 22, 2 bit, little-endian, data-type-policy=OVERRIDE, i-signal-type=PRIMITIVE, init-value=0, base-type=BT_UI1_KompFehlerModus2_06, compu {0=Cx0_TNCTOC (CM_UI1_KompFehlerModus2_06_Cx0_TNCTOC), 1=Cx1_TP_TC (CM_UI1_KompFehlerModus2_06_Cx1_TP_TC), 2=Cx2_TP_TC_WCMTL (CM_UI1_KompFehlerModus2_06_Cx2_TP_TC_WCMTL), 3=Cx3_TF_TC_Error (CM_UI1_KompFehlerModus2_06_Cx3_TF_TC_Error)}, range raw 0..3, transfer-property=PENDING, to BMC_HV(timeout 1 s)  # Uebertragung OBD relevanter Fehlerpfade vom Secondary zum Primary Steuergeraet. Zuordnung der generischen Komponentenfehler muss zwischen Sender und Empfaenger abgestimmt werden
          signal UI1_KompFehlerModus2_07_XIX_UI1_Komponentenfehler_01_XIX_BMC_CAN01: start 24, 2 bit, little-endian, data-type-policy=OVERRIDE, i-signal-type=PRIMITIVE, init-value=0, base-type=BT_UI1_KompFehlerModus2_07, compu {0=Cx0_TNCTOC (CM_UI1_KompFehlerModus2_07_Cx0_TNCTOC), 1=Cx1_TP_TC (CM_UI1_KompFehlerModus2_07_Cx1_TP_TC), 2=Cx2_TP_TC_WCMTL (CM_UI1_KompFehlerModus2_07_Cx2_TP_TC_WCMTL), 3=Cx3_TF_TC_Error (CM_UI1_KompFehlerModus2_07_Cx3_TF_TC_Error)}, range raw 0..3, transfer-property=PENDING, to BMC_HV(timeout 1 s)  # Uebertragung OBD relevanter Fehlerpfade vom Secondary zum Primary Steuergeraet. Zuordnung der generischen Komponentenfehler muss zwischen Sender und Empfaenger abgestimmt werden
          signal UI1_KompFehlerModus2_08_XIX_UI1_Komponentenfehler_01_XIX_BMC_CAN01: start 26, 2 bit, little-endian, data-type-policy=OVERRIDE, i-signal-type=PRIMITIVE, init-value=0, base-type=BT_UI1_KompFehlerModus2_08, compu {0=Cx0_TNCTOC (CM_UI1_KompFehlerModus2_08_Cx0_TNCTOC), 1=Cx1_TP_TC (CM_UI1_KompFehlerModus2_08_Cx1_TP_TC), 2=Cx2_TP_TC_WCMTL (CM_UI1_KompFehlerModus2_08_Cx2_TP_TC_WCMTL), 3=Cx3_TF_TC_Error (CM_UI1_KompFehlerModus2_08_Cx3_TF_TC_Error)}, range raw 0..3, transfer-property=PENDING, to BMC_HV(timeout 1 s)  # Uebertragung OBD relevanter Fehlerpfade vom Secondary zum Primary Steuergeraet. Zuordnung der generischen Komponentenfehler muss zwischen Sender und Empfaenger abgestimmt werden
          signal UI1_KompFehlerModus2_09_XIX_UI1_Komponentenfehler_01_XIX_BMC_CAN01: start 28, 2 bit, little-endian, data-type-policy=OVERRIDE, i-signal-type=PRIMITIVE, init-value=0, base-type=BT_UI1_KompFehlerModus2_09, compu {0=Cx0_TNCTOC (CM_UI1_KompFehlerModus2_09_Cx0_TNCTOC), 1=Cx1_TP_TC (CM_UI1_KompFehlerModus2_09_Cx1_TP_TC), 2=Cx2_TP_TC_WCMTL (CM_UI1_KompFehlerModus2_09_Cx2_TP_TC_WCMTL), 3=Cx3_TF_TC_Error (CM_UI1_KompFehlerModus2_09_Cx3_TF_TC_Error)}, range raw 0..3, transfer-property=PENDING, to BMC_HV(timeout 1 s)  # Uebertragung OBD relevanter Fehlerpfade vom Secondary zum Primary Steuergeraet. Zuordnung der generischen Komponentenfehler muss zwischen Sender und Empfaenger abgestimmt werden
          signal UI1_KompFehlerModus2_10_XIX_UI1_Komponentenfehler_01_XIX_BMC_CAN01: start 30, 2 bit, little-endian, data-type-policy=OVERRIDE, i-signal-type=PRIMITIVE, init-value=0, base-type=BT_UI1_KompFehlerModus2_10, compu {0=Cx0_TNCTOC (CM_UI1_KompFehlerModus2_10_Cx0_TNCTOC), 1=Cx1_TP_TC (CM_UI1_KompFehlerModus2_10_Cx1_TP_TC), 2=Cx2_TP_TC_WCMTL (CM_UI1_KompFehlerModus2_10_Cx2_TP_TC_WCMTL), 3=Cx3_TF_TC_Error (CM_UI1_KompFehlerModus2_10_Cx3_TF_TC_Error)}, range raw 0..3, transfer-property=PENDING, to BMC_HV(timeout 1 s)  # Uebertragung OBD relevanter Fehlerpfade vom Secondary zum Primary Steuergeraet. Zuordnung der generischen Komponentenfehler muss zwischen Sender und Empfaenger abgestimmt werden
          signal UI1_KompFehlerModus2_11_XIX_UI1_Komponentenfehler_01_XIX_BMC_CAN01: start 32, 2 bit, little-endian, data-type-policy=OVERRIDE, i-signal-type=PRIMITIVE, init-value=0, base-type=BT_UI1_KompFehlerModus2_11, compu {0=Cx0_TNCTOC (CM_UI1_KompFehlerModus2_11_Cx0_TNCTOC), 1=Cx1_TP_TC (CM_UI1_KompFehlerModus2_11_Cx1_TP_TC), 2=Cx2_TP_TC_WCMTL (CM_UI1_KompFehlerModus2_11_Cx2_TP_TC_WCMTL), 3=Cx3_TF_TC_Error (CM_UI1_KompFehlerModus2_11_Cx3_TF_TC_Error)}, range raw 0..3, transfer-property=PENDING, to BMC_HV(timeout 1 s)  # Uebertragung OBD relevanter Fehlerpfade vom Secondary zum Primary Steuergeraet. Zuordnung der generischen Komponentenfehler muss zwischen Sender und Empfaenger abgestimmt werden
          signal UI1_KompFehlerModus2_12_XIX_UI1_Komponentenfehler_01_XIX_BMC_CAN01: start 34, 2 bit, little-endian, data-type-policy=OVERRIDE, i-signal-type=PRIMITIVE, init-value=0, base-type=BT_UI1_KompFehlerModus2_12, compu {0=Cx0_TNCTOC (CM_UI1_KompFehlerModus2_12_Cx0_TNCTOC), 1=Cx1_TP_TC (CM_UI1_KompFehlerModus2_12_Cx1_TP_TC), 2=Cx2_TP_TC_WCMTL (CM_UI1_KompFehlerModus2_12_Cx2_TP_TC_WCMTL), 3=Cx3_TF_TC_Error (CM_UI1_KompFehlerModus2_12_Cx3_TF_TC_Error)}, range raw 0..3, transfer-property=PENDING, to BMC_HV(timeout 1 s)  # Uebertragung OBD relevanter Fehlerpfade vom Secondary zum Primary Steuergeraet. Zuordnung der generischen Komponentenfehler muss zwischen Sender und Empfaenger abgestimmt werden
          signal UI1_KompFehlerModus2_13_XIX_UI1_Komponentenfehler_01_XIX_BMC_CAN01: start 36, 2 bit, little-endian, data-type-policy=OVERRIDE, i-signal-type=PRIMITIVE, init-value=0, base-type=BT_UI1_KompFehlerModus2_13, compu {0=Cx0_TNCTOC (CM_UI1_KompFehlerModus2_13_Cx0_TNCTOC), 1=Cx1_TP_TC (CM_UI1_KompFehlerModus2_13_Cx1_TP_TC), 2=Cx2_TP_TC_WCMTL (CM_UI1_KompFehlerModus2_13_Cx2_TP_TC_WCMTL), 3=Cx3_TF_TC_Error (CM_UI1_KompFehlerModus2_13_Cx3_TF_TC_Error)}, range raw 0..3, transfer-property=PENDING, to BMC_HV(timeout 1 s)  # Uebertragung OBD relevanter Fehlerpfade vom Secondary zum Primary Steuergeraet. Zuordnung der generischen Komponentenfehler muss zwischen Sender und Empfaenger abgestimmt werden
          signal UI1_KompFehlerModus2_14_XIX_UI1_Komponentenfehler_01_XIX_BMC_CAN01: start 38, 2 bit, little-endian, data-type-policy=OVERRIDE, i-signal-type=PRIMITIVE, init-value=0, base-type=BT_UI1_KompFehlerModus2_14, compu {0=Cx0_TNCTOC (CM_UI1_KompFehlerModus2_14_Cx0_TNCTOC), 1=Cx1_TP_TC (CM_UI1_KompFehlerModus2_14_Cx1_TP_TC), 2=Cx2_TP_TC_WCMTL (CM_UI1_KompFehlerModus2_14_Cx2_TP_TC_WCMTL), 3=Cx3_TF_TC_Error (CM_UI1_KompFehlerModus2_14_Cx3_TF_TC_Error)}, range raw 0..3, transfer-property=PENDING, to BMC_HV(timeout 1 s)  # Uebertragung OBD relevanter Fehlerpfade vom Secondary zum Primary Steuergeraet. Zuordnung der generischen Komponentenfehler muss zwischen Sender und Empfaenger abgestimmt werden
          signal UI1_KompFehlerModus2_15_XIX_UI1_Komponentenfehler_01_XIX_BMC_CAN01: start 40, 2 bit, little-endian, data-type-policy=OVERRIDE, i-signal-type=PRIMITIVE, init-value=0, base-type=BT_UI1_KompFehlerModus2_15, compu {0=Cx0_TNCTOC (CM_UI1_KompFehlerModus2_15_Cx0_TNCTOC), 1=Cx1_TP_TC (CM_UI1_KompFehlerModus2_15_Cx1_TP_TC), 2=Cx2_TP_TC_WCMTL (CM_UI1_KompFehlerModus2_15_Cx2_TP_TC_WCMTL), 3=Cx3_TF_TC_Error (CM_UI1_KompFehlerModus2_15_Cx3_TF_TC_Error)}, range raw 0..3, transfer-property=PENDING, to BMC_HV(timeout 1 s)  # Uebertragung OBD relevanter Fehlerpfade vom Secondary zum Primary Steuergeraet. Zuordnung der generischen Komponentenfehler muss zwischen Sender und Empfaenger abgestimmt werden
          signal UI1_KompFehlerModus2_16_XIX_UI1_Komponentenfehler_01_XIX_BMC_CAN01: start 42, 2 bit, little-endian, data-type-policy=OVERRIDE, i-signal-type=PRIMITIVE, init-value=0, base-type=BT_UI1_KompFehlerModus2_16, compu {0=Cx0_TNCTOC (CM_UI1_KompFehlerModus2_16_Cx0_TNCTOC), 1=Cx1_TP_TC (CM_UI1_KompFehlerModus2_16_Cx1_TP_TC), 2=Cx2_TP_TC_WCMTL (CM_UI1_KompFehlerModus2_16_Cx2_TP_TC_WCMTL), 3=Cx3_TF_TC_Error (CM_UI1_KompFehlerModus2_16_Cx3_TF_TC_Error)}, range raw 0..3, transfer-property=PENDING, to BMC_HV(timeout 1 s)  # Uebertragung OBD relevanter Fehlerpfade vom Secondary zum Primary Steuergeraet. Zuordnung der generischen Komponentenfehler muss zwischen Sender und Empfaenger abgestimmt werden
          signal UI1_KompFehlerModus2_17_XIX_UI1_Komponentenfehler_01_XIX_BMC_CAN01: start 44, 2 bit, little-endian, data-type-policy=OVERRIDE, i-signal-type=PRIMITIVE, init-value=0, base-type=BT_UI1_KompFehlerModus2_17, compu {0=Cx0_TNCTOC (CM_UI1_KompFehlerModus2_17_Cx0_TNCTOC), 1=Cx1_TP_TC (CM_UI1_KompFehlerModus2_17_Cx1_TP_TC), 2=Cx2_TP_TC_WCMTL (CM_UI1_KompFehlerModus2_17_Cx2_TP_TC_WCMTL), 3=Cx3_TF_TC_Error (CM_UI1_KompFehlerModus2_17_Cx3_TF_TC_Error)}, range raw 0..3, transfer-property=PENDING, to BMC_HV(timeout 1 s)  # Uebertragung OBD relevanter Fehlerpfade vom Secondary zum Primary Steuergeraet. Zuordnung der generischen Komponentenfehler muss zwischen Sender und Empfaenger abgestimmt werden
          signal UI1_KompFehlerModus2_18_XIX_UI1_Komponentenfehler_01_XIX_BMC_CAN01: start 46, 2 bit, little-endian, data-type-policy=OVERRIDE, i-signal-type=PRIMITIVE, init-value=0, base-type=BT_UI1_KompFehlerModus2_18, compu {0=Cx0_TNCTOC (CM_UI1_KompFehlerModus2_18_Cx0_TNCTOC), 1=Cx1_TP_TC (CM_UI1_KompFehlerModus2_18_Cx1_TP_TC), 2=Cx2_TP_TC_WCMTL (CM_UI1_KompFehlerModus2_18_Cx2_TP_TC_WCMTL), 3=Cx3_TF_TC_Error (CM_UI1_KompFehlerModus2_18_Cx3_TF_TC_Error)}, range raw 0..3, transfer-property=PENDING, to BMC_HV(timeout 1 s)  # Uebertragung OBD relevanter Fehlerpfade vom Secondary zum Primary Steuergeraet. Zuordnung der generischen Komponentenfehler muss zwischen Sender und Empfaenger abgestimmt werden
          signal UI1_KompFehlerModus2_19_XIX_UI1_Komponentenfehler_01_XIX_BMC_CAN01: start 48, 2 bit, little-endian, data-type-policy=OVERRIDE, i-signal-type=PRIMITIVE, init-value=0, base-type=BT_UI1_KompFehlerModus2_19, compu {0=Cx0_TNCTOC (CM_UI1_KompFehlerModus2_19_Cx0_TNCTOC), 1=Cx1_TP_TC (CM_UI1_KompFehlerModus2_19_Cx1_TP_TC), 2=Cx2_TP_TC_WCMTL (CM_UI1_KompFehlerModus2_19_Cx2_TP_TC_WCMTL), 3=Cx3_TF_TC_Error (CM_UI1_KompFehlerModus2_19_Cx3_TF_TC_Error)}, range raw 0..3, transfer-property=PENDING, to BMC_HV(timeout 1 s)  # Uebertragung OBD relevanter Fehlerpfade vom Secondary zum Primary Steuergeraet. Zuordnung der generischen Komponentenfehler muss zwischen Sender und Empfaenger abgestimmt werden
          signal UI1_KompFehlerModus2_20_XIX_UI1_Komponentenfehler_01_XIX_BMC_CAN01: start 50, 2 bit, little-endian, data-type-policy=OVERRIDE, i-signal-type=PRIMITIVE, init-value=0, base-type=BT_UI1_KompFehlerModus2_20, compu {0=Cx0_TNCTOC (CM_UI1_KompFehlerModus2_20_Cx0_TNCTOC), 1=Cx1_TP_TC (CM_UI1_KompFehlerModus2_20_Cx1_TP_TC), 2=Cx2_TP_TC_WCMTL (CM_UI1_KompFehlerModus2_20_Cx2_TP_TC_WCMTL), 3=Cx3_TF_TC_Error (CM_UI1_KompFehlerModus2_20_Cx3_TF_TC_Error)}, range raw 0..3, transfer-property=PENDING, to BMC_HV(timeout 1 s)  # Uebertragung OBD relevanter Fehlerpfade vom Secondary zum Primary Steuergeraet. Zuordnung der generischen Komponentenfehler muss zwischen Sender und Empfaenger abgestimmt werden
          signal UI1_KompFehlerModus2_21_XIX_UI1_Komponentenfehler_01_XIX_BMC_CAN01: start 52, 2 bit, little-endian, data-type-policy=OVERRIDE, i-signal-type=PRIMITIVE, init-value=0, base-type=BT_UI1_KompFehlerModus2_21, compu {0=Cx0_TNCTOC (CM_UI1_KompFehlerModus2_21_Cx0_TNCTOC), 1=Cx1_TP_TC (CM_UI1_KompFehlerModus2_21_Cx1_TP_TC), 2=Cx2_TP_TC_WCMTL (CM_UI1_KompFehlerModus2_21_Cx2_TP_TC_WCMTL), 3=Cx3_TF_TC_Error (CM_UI1_KompFehlerModus2_21_Cx3_TF_TC_Error)}, range raw 0..3, transfer-property=PENDING, to BMC_HV(timeout 1 s)  # Uebertragung OBD relevanter Fehlerpfade vom Secondary zum Primary Steuergeraet. Zuordnung der generischen Komponentenfehler muss zwischen Sender und Empfaenger abgestimmt werden
          signal UI1_KompFehlerModus2_22_XIX_UI1_Komponentenfehler_01_XIX_BMC_CAN01: start 54, 2 bit, little-endian, data-type-policy=OVERRIDE, i-signal-type=PRIMITIVE, init-value=0, base-type=BT_UI1_KompFehlerModus2_22, compu {0=Cx0_TNCTOC (CM_UI1_KompFehlerModus2_22_Cx0_TNCTOC), 1=Cx1_TP_TC (CM_UI1_KompFehlerModus2_22_Cx1_TP_TC), 2=Cx2_TP_TC_WCMTL (CM_UI1_KompFehlerModus2_22_Cx2_TP_TC_WCMTL), 3=Cx3_TF_TC_Error (CM_UI1_KompFehlerModus2_22_Cx3_TF_TC_Error)}, range raw 0..3, transfer-property=PENDING, to BMC_HV(timeout 1 s)  # Uebertragung OBD relevanter Fehlerpfade vom Secondary zum Primary Steuergeraet. Zuordnung der generischen Komponentenfehler muss zwischen Sender und Empfaenger abgestimmt werden
          signal UI1_KompFehlerModus2_23_XIX_UI1_Komponentenfehler_01_XIX_BMC_CAN01: start 56, 2 bit, little-endian, data-type-policy=OVERRIDE, i-signal-type=PRIMITIVE, init-value=0, base-type=BT_UI1_KompFehlerModus2_23, compu {0=Cx0_TNCTOC (CM_UI1_KompFehlerModus2_23_Cx0_TNCTOC), 1=Cx1_TP_TC (CM_UI1_KompFehlerModus2_23_Cx1_TP_TC), 2=Cx2_TP_TC_WCMTL (CM_UI1_KompFehlerModus2_23_Cx2_TP_TC_WCMTL), 3=Cx3_TF_TC_Error (CM_UI1_KompFehlerModus2_23_Cx3_TF_TC_Error)}, range raw 0..3, transfer-property=PENDING, to BMC_HV(timeout 1 s)  # Uebertragung OBD relevanter Fehlerpfade vom Secondary zum Primary Steuergeraet. Zuordnung der generischen Komponentenfehler muss zwischen Sender und Empfaenger abgestimmt werden
          signal UI1_KompFehlerModus2_24_XIX_UI1_Komponentenfehler_01_XIX_BMC_CAN01: start 58, 2 bit, little-endian, data-type-policy=OVERRIDE, i-signal-type=PRIMITIVE, init-value=0, base-type=BT_UI1_KompFehlerModus2_24, compu {0=Cx0_TNCTOC (CM_UI1_KompFehlerModus2_24_Cx0_TNCTOC), 1=Cx1_TP_TC (CM_UI1_KompFehlerModus2_24_Cx1_TP_TC), 2=Cx2_TP_TC_WCMTL (CM_UI1_KompFehlerModus2_24_Cx2_TP_TC_WCMTL), 3=Cx3_TF_TC_Error (CM_UI1_KompFehlerModus2_24_Cx3_TF_TC_Error)}, range raw 0..3, transfer-property=PENDING, to BMC_HV(timeout 1 s)  # Uebertragung OBD relevanter Fehlerpfade vom Secondary zum Primary Steuergeraet. Zuordnung der generischen Komponentenfehler muss zwischen Sender und Empfaenger abgestimmt werden
          signal UI1_KompFehlerModus2_25_XIX_UI1_Komponentenfehler_01_XIX_BMC_CAN01: start 60, 2 bit, little-endian, data-type-policy=OVERRIDE, i-signal-type=PRIMITIVE, init-value=0, base-type=BT_UI1_KompFehlerModus2_25, compu {0=Cx0_TNCTOC (CM_UI1_KompFehlerModus2_25_Cx0_TNCTOC), 1=Cx1_TP_TC (CM_UI1_KompFehlerModus2_25_Cx1_TP_TC), 2=Cx2_TP_TC_WCMTL (CM_UI1_KompFehlerModus2_25_Cx2_TP_TC_WCMTL), 3=Cx3_TF_TC_Error (CM_UI1_KompFehlerModus2_25_Cx3_TF_TC_Error)}, range raw 0..3, transfer-property=PENDING, to BMC_HV(timeout 1 s)  # Uebertragung OBD relevanter Fehlerpfade vom Secondary zum Primary Steuergeraet. Zuordnung der generischen Komponentenfehler muss zwischen Sender und Empfaenger abgestimmt werden
          signal UI1_KompFehlerModus2_26_XIX_UI1_Komponentenfehler_01_XIX_BMC_CAN01: start 62, 2 bit, little-endian, data-type-policy=OVERRIDE, i-signal-type=PRIMITIVE, init-value=0, base-type=BT_UI1_KompFehlerModus2_26, compu {0=Cx0_TNCTOC (CM_UI1_KompFehlerModus2_26_Cx0_TNCTOC), 1=Cx1_TP_TC (CM_UI1_KompFehlerModus2_26_Cx1_TP_TC), 2=Cx2_TP_TC_WCMTL (CM_UI1_KompFehlerModus2_26_Cx2_TP_TC_WCMTL), 3=Cx3_TF_TC_Error (CM_UI1_KompFehlerModus2_26_Cx3_TF_TC_Error)}, range raw 0..3, transfer-property=PENDING, to BMC_HV(timeout 1 s)  # Uebertragung OBD relevanter Fehlerpfade vom Secondary zum Primary Steuergeraet. Zuordnung der generischen Komponentenfehler muss zwischen Sender und Empfaenger abgestimmt werden
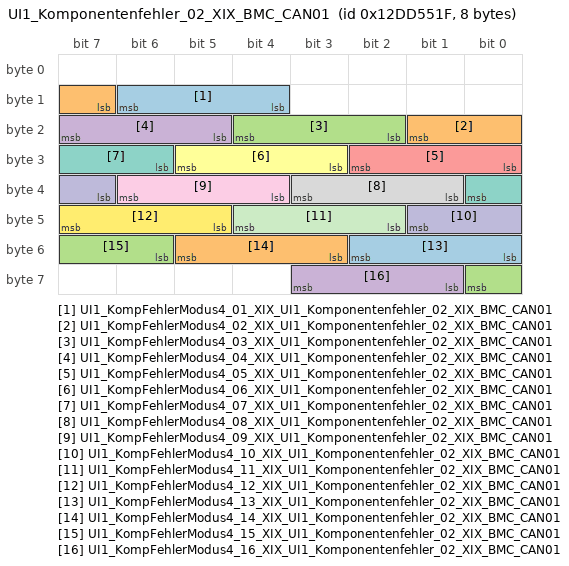
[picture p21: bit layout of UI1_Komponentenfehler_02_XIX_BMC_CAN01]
      frame UI1_Komponentenfehler_02_XIX_BMC_CAN01: id 0x12DD551F, to BMC_HV, frame-length=8, can-addressing-mode=EXTENDED, can-frame-rx-behavior=CAN-20, can-frame-tx-behavior=CAN-20
        pdu UI1_Komponentenfehler_02_XIX_BMC_CAN01: length=8, transmission-mode-true-timing=cyclic-timing={time-offset=0, time-period=0.1}, unused-bit-pattern=0
          signal UI1_KompFehlerModus4_01_XIX_UI1_Komponentenfehler_02_XIX_BMC_CAN01: start 12, 3 bit, little-endian, data-type-policy=OVERRIDE, i-signal-type=PRIMITIVE, init-value=0, base-type=BT_UI1_KompFehlerModus4_01, compu {0=Cx0_TNCTOC (CM_UI1_KompFehlerModus4_01_Cx0_TNCTOC), 1=Cx1_TP_TC (CM_UI1_KompFehlerModus4_01_Cx1_TP_TC), 2=Cx2_TP_TC_WCMTL (CM_UI1_KompFehlerModus4_01_Cx2_TP_TC_WCMTL), 3=Cx3_TF_TC_Error_1 (CM_UI1_KompFehlerModus4_01_Cx3_TF_TC_Error_1), 4=Cx4_TF_TC_Error_2 (CM_UI1_KompFehlerModus4_01_Cx4_TF_TC_Error_2), 5=Cx5_TF_TC_Error_3 (CM_UI1_KompFehlerModus4_01_Cx5_TF_TC_Error_3), 6=Cx6_TF_TC_Error_4 (CM_UI1_KompFehlerModus4_01_Cx6_TF_TC_Error_4), 7=Cx7_TF_TC_Error_5 (CM_UI1_KompFehlerModus4_01_Cx7_TF_TC_Error_5)}, range raw 0..7, transfer-property=PENDING, to BMC_HV(timeout 1 s)  # Uebertragung OBD relevanter Fehlerpfade vom Secondary zum Primary Steuergeraet. Zuordnung der generischen Komponentenfehler muss zwischen Sender und Empfaenger abgestimmt werden (3bit Struktur)
          signal UI1_KompFehlerModus4_02_XIX_UI1_Komponentenfehler_02_XIX_BMC_CAN01: start 15, 3 bit, little-endian, data-type-policy=OVERRIDE, i-signal-type=PRIMITIVE, init-value=0, base-type=BT_UI1_KompFehlerModus4_02, compu {0=Cx0_TNCTOC (CM_UI1_KompFehlerModus4_02_Cx0_TNCTOC), 1=Cx1_TP_TC (CM_UI1_KompFehlerModus4_02_Cx1_TP_TC), 2=Cx2_TP_TC_WCMTL (CM_UI1_KompFehlerModus4_02_Cx2_TP_TC_WCMTL), 3=Cx3_TF_TC_Error_1 (CM_UI1_KompFehlerModus4_02_Cx3_TF_TC_Error_1), 4=Cx4_TF_TC_Error_2 (CM_UI1_KompFehlerModus4_02_Cx4_TF_TC_Error_2), 5=Cx5_TF_TC_Error_3 (CM_UI1_KompFehlerModus4_02_Cx5_TF_TC_Error_3), 6=Cx6_TF_TC_Error_4 (CM_UI1_KompFehlerModus4_02_Cx6_TF_TC_Error_4), 7=Cx7_TF_TC_Error_5 (CM_UI1_KompFehlerModus4_02_Cx7_TF_TC_Error_5)}, range raw 0..7, transfer-property=PENDING, to BMC_HV(timeout 1 s)  # Uebertragung OBD relevanter Fehlerpfade vom Secondary zum Primary Steuergeraet. Zuordnung der generischen Komponentenfehler muss zwischen Sender und Empfaenger abgestimmt werden (3bit Struktur)
          signal UI1_KompFehlerModus4_03_XIX_UI1_Komponentenfehler_02_XIX_BMC_CAN01: start 18, 3 bit, little-endian, data-type-policy=OVERRIDE, i-signal-type=PRIMITIVE, init-value=0, base-type=BT_UI1_KompFehlerModus4_03, compu {0=Cx0_TNCTOC (CM_UI1_KompFehlerModus4_03_Cx0_TNCTOC), 1=Cx1_TP_TC (CM_UI1_KompFehlerModus4_03_Cx1_TP_TC), 2=Cx2_TP_TC_WCMTL (CM_UI1_KompFehlerModus4_03_Cx2_TP_TC_WCMTL), 3=Cx3_TF_TC_Error_1 (CM_UI1_KompFehlerModus4_03_Cx3_TF_TC_Error_1), 4=Cx4_TF_TC_Error_2 (CM_UI1_KompFehlerModus4_03_Cx4_TF_TC_Error_2), 5=Cx5_TF_TC_Error_3 (CM_UI1_KompFehlerModus4_03_Cx5_TF_TC_Error_3), 6=Cx6_TF_TC_Error_4 (CM_UI1_KompFehlerModus4_03_Cx6_TF_TC_Error_4), 7=Cx7_TF_TC_Error_5 (CM_UI1_KompFehlerModus4_03_Cx7_TF_TC_Error_5)}, range raw 0..7, transfer-property=PENDING, to BMC_HV(timeout 1 s)  # Uebertragung OBD relevanter Fehlerpfade vom Secondary zum Primary Steuergeraet. Zuordnung der generischen Komponentenfehler muss zwischen Sender und Empfaenger abgestimmt werden (3bit Struktur)
          signal UI1_KompFehlerModus4_04_XIX_UI1_Komponentenfehler_02_XIX_BMC_CAN01: start 21, 3 bit, little-endian, data-type-policy=OVERRIDE, i-signal-type=PRIMITIVE, init-value=0, base-type=BT_UI1_KompFehlerModus4_04, compu {0=Cx0_TNCTOC (CM_UI1_KompFehlerModus4_04_Cx0_TNCTOC), 1=Cx1_TP_TC (CM_UI1_KompFehlerModus4_04_Cx1_TP_TC), 2=Cx2_TP_TC_WCMTL (CM_UI1_KompFehlerModus4_04_Cx2_TP_TC_WCMTL), 3=Cx3_TF_TC_Error_1 (CM_UI1_KompFehlerModus4_04_Cx3_TF_TC_Error_1), 4=Cx4_TF_TC_Error_2 (CM_UI1_KompFehlerModus4_04_Cx4_TF_TC_Error_2), 5=Cx5_TF_TC_Error_3 (CM_UI1_KompFehlerModus4_04_Cx5_TF_TC_Error_3), 6=Cx6_TF_TC_Error_4 (CM_UI1_KompFehlerModus4_04_Cx6_TF_TC_Error_4), 7=Cx7_TF_TC_Error_5 (CM_UI1_KompFehlerModus4_04_Cx7_TF_TC_Error_5)}, range raw 0..7, transfer-property=PENDING, to BMC_HV(timeout 1 s)  # Uebertragung OBD relevanter Fehlerpfade vom Secondary zum Primary Steuergeraet. Zuordnung der generischen Komponentenfehler muss zwischen Sender und Empfaenger abgestimmt werden (3bit Struktur)
          signal UI1_KompFehlerModus4_05_XIX_UI1_Komponentenfehler_02_XIX_BMC_CAN01: start 24, 3 bit, little-endian, data-type-policy=OVERRIDE, i-signal-type=PRIMITIVE, init-value=0, base-type=BT_UI1_KompFehlerModus4_05, compu {0=Cx0_TNCTOC (CM_UI1_KompFehlerModus4_05_Cx0_TNCTOC), 1=Cx1_TP_TC (CM_UI1_KompFehlerModus4_05_Cx1_TP_TC), 2=Cx2_TP_TC_WCMTL (CM_UI1_KompFehlerModus4_05_Cx2_TP_TC_WCMTL), 3=Cx3_TF_TC_Error_1 (CM_UI1_KompFehlerModus4_05_Cx3_TF_TC_Error_1), 4=Cx4_TF_TC_Error_2 (CM_UI1_KompFehlerModus4_05_Cx4_TF_TC_Error_2), 5=Cx5_TF_TC_Error_3 (CM_UI1_KompFehlerModus4_05_Cx5_TF_TC_Error_3), 6=Cx6_TF_TC_Error_4 (CM_UI1_KompFehlerModus4_05_Cx6_TF_TC_Error_4), 7=Cx7_TF_TC_Error_5 (CM_UI1_KompFehlerModus4_05_Cx7_TF_TC_Error_5)}, range raw 0..7, transfer-property=PENDING, to BMC_HV(timeout 1 s)  # Uebertragung OBD relevanter Fehlerpfade vom Secondary zum Primary Steuergeraet. Zuordnung der generischen Komponentenfehler muss zwischen Sender und Empfaenger abgestimmt werden (3bit Struktur)
          signal UI1_KompFehlerModus4_06_XIX_UI1_Komponentenfehler_02_XIX_BMC_CAN01: start 27, 3 bit, little-endian, data-type-policy=OVERRIDE, i-signal-type=PRIMITIVE, init-value=0, base-type=BT_UI1_KompFehlerModus4_06, compu {0=Cx0_TNCTOC (CM_UI1_KompFehlerModus4_06_Cx0_TNCTOC), 1=Cx1_TP_TC (CM_UI1_KompFehlerModus4_06_Cx1_TP_TC), 2=Cx2_TP_TC_WCMTL (CM_UI1_KompFehlerModus4_06_Cx2_TP_TC_WCMTL), 3=Cx3_TF_TC_Error_1 (CM_UI1_KompFehlerModus4_06_Cx3_TF_TC_Error_1), 4=Cx4_TF_TC_Error_2 (CM_UI1_KompFehlerModus4_06_Cx4_TF_TC_Error_2), 5=Cx5_TF_TC_Error_3 (CM_UI1_KompFehlerModus4_06_Cx5_TF_TC_Error_3), 6=Cx6_TF_TC_Error_4 (CM_UI1_KompFehlerModus4_06_Cx6_TF_TC_Error_4), 7=Cx7_TF_TC_Error_5 (CM_UI1_KompFehlerModus4_06_Cx7_TF_TC_Error_5)}, range raw 0..7, transfer-property=PENDING, to BMC_HV(timeout 1 s)  # Uebertragung OBD relevanter Fehlerpfade vom Secondary zum Primary Steuergeraet. Zuordnung der generischen Komponentenfehler muss zwischen Sender und Empfaenger abgestimmt werden (3bit Struktur)
          signal UI1_KompFehlerModus4_07_XIX_UI1_Komponentenfehler_02_XIX_BMC_CAN01: start 30, 3 bit, little-endian, data-type-policy=OVERRIDE, i-signal-type=PRIMITIVE, init-value=0, base-type=BT_UI1_KompFehlerModus4_07, compu {0=Cx0_TNCTOC (CM_UI1_KompFehlerModus4_07_Cx0_TNCTOC), 1=Cx1_TP_TC (CM_UI1_KompFehlerModus4_07_Cx1_TP_TC), 2=Cx2_TP_TC_WCMTL (CM_UI1_KompFehlerModus4_07_Cx2_TP_TC_WCMTL), 3=Cx3_TF_TC_Error_1 (CM_UI1_KompFehlerModus4_07_Cx3_TF_TC_Error_1), 4=Cx4_TF_TC_Error_2 (CM_UI1_KompFehlerModus4_07_Cx4_TF_TC_Error_2), 5=Cx5_TF_TC_Error_3 (CM_UI1_KompFehlerModus4_07_Cx5_TF_TC_Error_3), 6=Cx6_TF_TC_Error_4 (CM_UI1_KompFehlerModus4_07_Cx6_TF_TC_Error_4), 7=Cx7_TF_TC_Error_5 (CM_UI1_KompFehlerModus4_07_Cx7_TF_TC_Error_5)}, range raw 0..7, transfer-property=PENDING, to BMC_HV(timeout 1 s)  # Uebertragung OBD relevanter Fehlerpfade vom Secondary zum Primary Steuergeraet. Zuordnung der generischen Komponentenfehler muss zwischen Sender und Empfaenger abgestimmt werden (3bit Struktur)
          signal UI1_KompFehlerModus4_08_XIX_UI1_Komponentenfehler_02_XIX_BMC_CAN01: start 33, 3 bit, little-endian, data-type-policy=OVERRIDE, i-signal-type=PRIMITIVE, init-value=0, base-type=BT_UI1_KompFehlerModus4_08, compu {0=Cx0_TNCTOC (CM_UI1_KompFehlerModus4_08_Cx0_TNCTOC), 1=Cx1_TP_TC (CM_UI1_KompFehlerModus4_08_Cx1_TP_TC), 2=Cx2_TP_TC_WCMTL (CM_UI1_KompFehlerModus4_08_Cx2_TP_TC_WCMTL), 3=Cx3_TF_TC_Error_1 (CM_UI1_KompFehlerModus4_08_Cx3_TF_TC_Error_1), 4=Cx4_TF_TC_Error_2 (CM_UI1_KompFehlerModus4_08_Cx4_TF_TC_Error_2), 5=Cx5_TF_TC_Error_3 (CM_UI1_KompFehlerModus4_08_Cx5_TF_TC_Error_3), 6=Cx6_TF_TC_Error_4 (CM_UI1_KompFehlerModus4_08_Cx6_TF_TC_Error_4), 7=Cx7_TF_TC_Error_5 (CM_UI1_KompFehlerModus4_08_Cx7_TF_TC_Error_5)}, range raw 0..7, transfer-property=PENDING, to BMC_HV(timeout 1 s)  # Uebertragung OBD relevanter Fehlerpfade vom Secondary zum Primary Steuergeraet. Zuordnung der generischen Komponentenfehler muss zwischen Sender und Empfaenger abgestimmt werden (3bit Struktur)
          signal UI1_KompFehlerModus4_09_XIX_UI1_Komponentenfehler_02_XIX_BMC_CAN01: start 36, 3 bit, little-endian, data-type-policy=OVERRIDE, i-signal-type=PRIMITIVE, init-value=0, base-type=BT_UI1_KompFehlerModus4_09, compu {0=Cx0_TNCTOC (CM_UI1_KompFehlerModus4_09_Cx0_TNCTOC), 1=Cx1_TP_TC (CM_UI1_KompFehlerModus4_09_Cx1_TP_TC), 2=Cx2_TP_TC_WCMTL (CM_UI1_KompFehlerModus4_09_Cx2_TP_TC_WCMTL), 3=Cx3_TF_TC_Error_1 (CM_UI1_KompFehlerModus4_09_Cx3_TF_TC_Error_1), 4=Cx4_TF_TC_Error_2 (CM_UI1_KompFehlerModus4_09_Cx4_TF_TC_Error_2), 5=Cx5_TF_TC_Error_3 (CM_UI1_KompFehlerModus4_09_Cx5_TF_TC_Error_3), 6=Cx6_TF_TC_Error_4 (CM_UI1_KompFehlerModus4_09_Cx6_TF_TC_Error_4), 7=Cx7_TF_TC_Error_5 (CM_UI1_KompFehlerModus4_09_Cx7_TF_TC_Error_5)}, range raw 0..7, transfer-property=PENDING, to BMC_HV(timeout 1 s)  # Uebertragung OBD relevanter Fehlerpfade vom Secondary zum Primary Steuergeraet. Zuordnung der generischen Komponentenfehler muss zwischen Sender und Empfaenger abgestimmt werden (3bit Struktur)
          signal UI1_KompFehlerModus4_10_XIX_UI1_Komponentenfehler_02_XIX_BMC_CAN01: start 39, 3 bit, little-endian, data-type-policy=OVERRIDE, i-signal-type=PRIMITIVE, init-value=0, base-type=BT_UI1_KompFehlerModus4_10, compu {0=Cx0_TNCTOC (CM_UI1_KompFehlerModus4_10_Cx0_TNCTOC), 1=Cx1_TP_TC (CM_UI1_KompFehlerModus4_10_Cx1_TP_TC), 2=Cx2_TP_TC_WCMTL (CM_UI1_KompFehlerModus4_10_Cx2_TP_TC_WCMTL), 3=Cx3_TF_TC_Error_1 (CM_UI1_KompFehlerModus4_10_Cx3_TF_TC_Error_1), 4=Cx4_TF_TC_Error_2 (CM_UI1_KompFehlerModus4_10_Cx4_TF_TC_Error_2), 5=Cx5_TF_TC_Error_3 (CM_UI1_KompFehlerModus4_10_Cx5_TF_TC_Error_3), 6=Cx6_TF_TC_Error_4 (CM_UI1_KompFehlerModus4_10_Cx6_TF_TC_Error_4), 7=Cx7_TF_TC_Error_5 (CM_UI1_KompFehlerModus4_10_Cx7_TF_TC_Error_5)}, range raw 0..7, transfer-property=PENDING, to BMC_HV(timeout 1 s)  # Uebertragung OBD relevanter Fehlerpfade vom Secondary zum Primary Steuergeraet. Zuordnung der generischen Komponentenfehler muss zwischen Sender und Empfaenger abgestimmt werden (3bit Struktur)
          signal UI1_KompFehlerModus4_11_XIX_UI1_Komponentenfehler_02_XIX_BMC_CAN01: start 42, 3 bit, little-endian, data-type-policy=OVERRIDE, i-signal-type=PRIMITIVE, init-value=0, base-type=BT_UI1_KompFehlerModus4_11, compu {0=Cx0_TNCTOC (CM_UI1_KompFehlerModus4_11_Cx0_TNCTOC), 1=Cx1_TP_TC (CM_UI1_KompFehlerModus4_11_Cx1_TP_TC), 2=Cx2_TP_TC_WCMTL (CM_UI1_KompFehlerModus4_11_Cx2_TP_TC_WCMTL), 3=Cx3_TF_TC_Error_1 (CM_UI1_KompFehlerModus4_11_Cx3_TF_TC_Error_1), 4=Cx4_TF_TC_Error_2 (CM_UI1_KompFehlerModus4_11_Cx4_TF_TC_Error_2), 5=Cx5_TF_TC_Error_3 (CM_UI1_KompFehlerModus4_11_Cx5_TF_TC_Error_3), 6=Cx6_TF_TC_Error_4 (CM_UI1_KompFehlerModus4_11_Cx6_TF_TC_Error_4), 7=Cx7_TF_TC_Error_5 (CM_UI1_KompFehlerModus4_11_Cx7_TF_TC_Error_5)}, range raw 0..7, transfer-property=PENDING, to BMC_HV(timeout 1 s)  # Uebertragung OBD relevanter Fehlerpfade vom Secondary zum Primary Steuergeraet. Zuordnung der generischen Komponentenfehler muss zwischen Sender und Empfaenger abgestimmt werden (3bit Struktur)
          signal UI1_KompFehlerModus4_12_XIX_UI1_Komponentenfehler_02_XIX_BMC_CAN01: start 45, 3 bit, little-endian, data-type-policy=OVERRIDE, i-signal-type=PRIMITIVE, init-value=0, base-type=BT_UI1_KompFehlerModus4_12, compu {0=Cx0_TNCTOC (CM_UI1_KompFehlerModus4_12_Cx0_TNCTOC), 1=Cx1_TP_TC (CM_UI1_KompFehlerModus4_12_Cx1_TP_TC), 2=Cx2_TP_TC_WCMTL (CM_UI1_KompFehlerModus4_12_Cx2_TP_TC_WCMTL), 3=Cx3_TF_TC_Error_1 (CM_UI1_KompFehlerModus4_12_Cx3_TF_TC_Error_1), 4=Cx4_TF_TC_Error_2 (CM_UI1_KompFehlerModus4_12_Cx4_TF_TC_Error_2), 5=Cx5_TF_TC_Error_3 (CM_UI1_KompFehlerModus4_12_Cx5_TF_TC_Error_3), 6=Cx6_TF_TC_Error_4 (CM_UI1_KompFehlerModus4_12_Cx6_TF_TC_Error_4), 7=Cx7_TF_TC_Error_5 (CM_UI1_KompFehlerModus4_12_Cx7_TF_TC_Error_5)}, range raw 0..7, transfer-property=PENDING, to BMC_HV(timeout 1 s)  # Uebertragung OBD relevanter Fehlerpfade vom Secondary zum Primary Steuergeraet. Zuordnung der generischen Komponentenfehler muss zwischen Sender und Empfaenger abgestimmt werden (3bit Struktur)
          signal UI1_KompFehlerModus4_13_XIX_UI1_Komponentenfehler_02_XIX_BMC_CAN01: start 48, 3 bit, little-endian, data-type-policy=OVERRIDE, i-signal-type=PRIMITIVE, init-value=0, base-type=BT_UI1_KompFehlerModus4_13, compu {0=Cx0_TNCTOC (CM_UI1_KompFehlerModus4_13_Cx0_TNCTOC), 1=Cx1_TP_TC (CM_UI1_KompFehlerModus4_13_Cx1_TP_TC), 2=Cx2_TP_TC_WCMTL (CM_UI1_KompFehlerModus4_13_Cx2_TP_TC_WCMTL), 3=Cx3_TF_TC_Error_1 (CM_UI1_KompFehlerModus4_13_Cx3_TF_TC_Error_1), 4=Cx4_TF_TC_Error_2 (CM_UI1_KompFehlerModus4_13_Cx4_TF_TC_Error_2), 5=Cx5_TF_TC_Error_3 (CM_UI1_KompFehlerModus4_13_Cx5_TF_TC_Error_3), 6=Cx6_TF_TC_Error_4 (CM_UI1_KompFehlerModus4_13_Cx6_TF_TC_Error_4), 7=Cx7_TF_TC_Error_5 (CM_UI1_KompFehlerModus4_13_Cx7_TF_TC_Error_5)}, range raw 0..7, transfer-property=PENDING, to BMC_HV(timeout 1 s)  # Uebertragung OBD relevanter Fehlerpfade vom Secondary zum Primary Steuergeraet. Zuordnung der generischen Komponentenfehler muss zwischen Sender und Empfaenger abgestimmt werden (3bit Struktur)
          signal UI1_KompFehlerModus4_14_XIX_UI1_Komponentenfehler_02_XIX_BMC_CAN01: start 51, 3 bit, little-endian, data-type-policy=OVERRIDE, i-signal-type=PRIMITIVE, init-value=0, base-type=BT_UI1_KompFehlerModus4_14, compu {0=Cx0_TNCTOC (CM_UI1_KompFehlerModus4_14_Cx0_TNCTOC), 1=Cx1_TP_TC (CM_UI1_KompFehlerModus4_14_Cx1_TP_TC), 2=Cx2_TP_TC_WCMTL (CM_UI1_KompFehlerModus4_14_Cx2_TP_TC_WCMTL), 3=Cx3_TF_TC_Error_1 (CM_UI1_KompFehlerModus4_14_Cx3_TF_TC_Error_1), 4=Cx4_TF_TC_Error_2 (CM_UI1_KompFehlerModus4_14_Cx4_TF_TC_Error_2), 5=Cx5_TF_TC_Error_3 (CM_UI1_KompFehlerModus4_14_Cx5_TF_TC_Error_3), 6=Cx6_TF_TC_Error_4 (CM_UI1_KompFehlerModus4_14_Cx6_TF_TC_Error_4), 7=Cx7_TF_TC_Error_5 (CM_UI1_KompFehlerModus4_14_Cx7_TF_TC_Error_5)}, range raw 0..7, transfer-property=PENDING, to BMC_HV(timeout 1 s)  # Uebertragung OBD relevanter Fehlerpfade vom Secondary zum Primary Steuergeraet. Zuordnung der generischen Komponentenfehler muss zwischen Sender und Empfaenger abgestimmt werden (3bit Struktur)
          signal UI1_KompFehlerModus4_15_XIX_UI1_Komponentenfehler_02_XIX_BMC_CAN01: start 54, 3 bit, little-endian, data-type-policy=OVERRIDE, i-signal-type=PRIMITIVE, init-value=0, base-type=BT_UI1_KompFehlerModus4_15, compu {0=Cx0_TNCTOC (CM_UI1_KompFehlerModus4_15_Cx0_TNCTOC), 1=Cx1_TP_TC (CM_UI1_KompFehlerModus4_15_Cx1_TP_TC), 2=Cx2_TP_TC_WCMTL (CM_UI1_KompFehlerModus4_15_Cx2_TP_TC_WCMTL), 3=Cx3_TF_TC_Error_1 (CM_UI1_KompFehlerModus4_15_Cx3_TF_TC_Error_1), 4=Cx4_TF_TC_Error_2 (CM_UI1_KompFehlerModus4_15_Cx4_TF_TC_Error_2), 5=Cx5_TF_TC_Error_3 (CM_UI1_KompFehlerModus4_15_Cx5_TF_TC_Error_3), 6=Cx6_TF_TC_Error_4 (CM_UI1_KompFehlerModus4_15_Cx6_TF_TC_Error_4), 7=Cx7_TF_TC_Error_5 (CM_UI1_KompFehlerModus4_15_Cx7_TF_TC_Error_5)}, range raw 0..7, transfer-property=PENDING, to BMC_HV(timeout 1 s)  # Uebertragung OBD relevanter Fehlerpfade vom Secondary zum Primary Steuergeraet. Zuordnung der generischen Komponentenfehler muss zwischen Sender und Empfaenger abgestimmt werden (3bit Struktur)
          signal UI1_KompFehlerModus4_16_XIX_UI1_Komponentenfehler_02_XIX_BMC_CAN01: start 57, 3 bit, little-endian, data-type-policy=OVERRIDE, i-signal-type=PRIMITIVE, init-value=0, base-type=BT_UI1_KompFehlerModus4_16, compu {0=Cx0_TNCTOC (CM_UI1_KompFehlerModus4_16_Cx0_TNCTOC), 1=Cx1_TP_TC (CM_UI1_KompFehlerModus4_16_Cx1_TP_TC), 2=Cx2_TP_TC_WCMTL (CM_UI1_KompFehlerModus4_16_Cx2_TP_TC_WCMTL), 3=Cx3_TF_TC_Error_1 (CM_UI1_KompFehlerModus4_16_Cx3_TF_TC_Error_1), 4=Cx4_TF_TC_Error_2 (CM_UI1_KompFehlerModus4_16_Cx4_TF_TC_Error_2), 5=Cx5_TF_TC_Error_3 (CM_UI1_KompFehlerModus4_16_Cx5_TF_TC_Error_3), 6=Cx6_TF_TC_Error_4 (CM_UI1_KompFehlerModus4_16_Cx6_TF_TC_Error_4), 7=Cx7_TF_TC_Error_5 (CM_UI1_KompFehlerModus4_16_Cx7_TF_TC_Error_5)}, range raw 0..7, transfer-property=PENDING, to BMC_HV(timeout 1 s)  # Uebertragung OBD relevanter Fehlerpfade vom Secondary zum Primary Steuergeraet. Zuordnung der generischen Komponentenfehler muss zwischen Sender und Empfaenger abgestimmt werden (3bit Struktur)
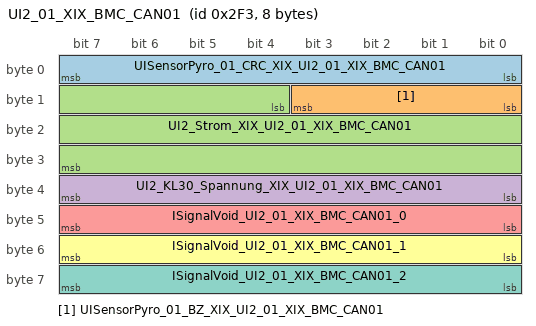
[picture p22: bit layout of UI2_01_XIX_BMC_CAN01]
      frame UI2_01_XIX_BMC_CAN01: id 0x2F3, to BMC_HV, frame-length=8, can-addressing-mode=STANDARD, can-frame-rx-behavior=CAN-20, can-frame-tx-behavior=CAN-20
        pdu UI2_01_XIX_BMC_CAN01_E2E: length=8, transmission-mode-true-timing=event-controlled-timing={number-of-repetitions=0, repetition-period=0}, unused-bit-pattern=0  # Fuer die Botschaft ist das Cyclic-Timing 0.01 zu verwenden.
          signal UISensorPyro_01_CRC_XIX_UI2_01_XIX_BMC_CAN01: start 0, 8 bit, little-endian, data-type-policy=OVERRIDE, i-signal-type=PRIMITIVE, init-value=0, base-type=BT_UISensorPyro_01_CRC, compu {phys=raw for raw 0..255}, range phys 0..255, raw 0..255, to BMC_HV(timeout 0.5 s)
          signal UISensorPyro_01_BZ_XIX_UI2_01_XIX_BMC_CAN01: start 8, 4 bit, little-endian, data-type-policy=OVERRIDE, i-signal-type=PRIMITIVE, init-value=0, base-type=BT_UISensorPyro_01_BZ, compu {phys=raw for raw 0..15}, range phys 0..15, raw 0..15, to BMC_HV(timeout 0.5 s)
          signal UI2_Strom_XIX_UI2_01_XIX_BMC_CAN01: start 12, 20 bit, little-endian, data-type-policy=OVERRIDE, i-signal-type=PRIMITIVE, init-value=1048574, base-type=BT_UI2_Strom, invalid-value=Invalid_UI2_Strom_XIX_UI2_01_XIX_BMC_CAN01:1048575, compu {phys=raw*0.005-2621 for raw 0..1048573, 1048574=Cxffffe_Init (CM_UI2_Strom_Cxffffe_Init), 1048575=Cxfffff_Fehler (CM_UI2_Strom_Cxfffff_Fehler); unit Unit_Amper}, range phys -2621..2621.865 Unit_Amper, raw 0..1048575, unit=Unit_Amper, to BMC_HV(timeout 0.5 s)  # "Momentanwert: Batteriestrom Stromrichtung: ein Ladestrom wird mit positiven, ein Entladestrom mit negativen Werten angegeben"
          signal UI2_KL30_Spannung_XIX_UI2_01_XIX_BMC_CAN01: start 32, 8 bit, little-endian, data-type-policy=OVERRIDE, i-signal-type=PRIMITIVE, init-value=254, base-type=BT_UI2_KL30_Spannung, invalid-value=Invalid_UI2_KL30_Spannung_XIX_UI2_01_XIX_BMC_CAN01:255, compu {phys=raw*0.1 for raw 0..253, 254=Cxfe_Init (CM_UI2_KL30_Spannung_Cxfe_Init), 255=Cxff_Fehler (CM_UI2_KL30_Spannung_Cxff_Fehler); unit Unit_Volt}, range phys 0..25.3 Unit_Volt, raw 0..255, unit=Unit_Volt, to BMC_HV(timeout 0.5 s)  # Momentanwert: gemessene Klemme30-Spannung am UI-Sensor
          signal ISignalVoid_UI2_01_XIX_BMC_CAN01_0: start 40, 8 bit, little-endian, system signal SignalVoid_UI2_01_0, data-type-policy=OVERRIDE, i-signal-type=PRIMITIVE, base-type=BT_SignalVoid
          signal ISignalVoid_UI2_01_XIX_BMC_CAN01_1: start 48, 8 bit, little-endian, system signal SignalVoid_UI2_01_1, data-type-policy=OVERRIDE, i-signal-type=PRIMITIVE, base-type=BT_SignalVoid
          signal ISignalVoid_UI2_01_XIX_BMC_CAN01_2: start 56, 8 bit, little-endian, system signal SignalVoid_UI2_01_2, data-type-policy=OVERRIDE, i-signal-type=PRIMITIVE, base-type=BT_SignalVoid
          mapping SG_UI2_01_XIX_BMC_CAN01: i-signal-group=SG_UI2_01_XIX_BMC_CAN01, transfer-property=TRIGGERED-WITHOUT-REPETITION
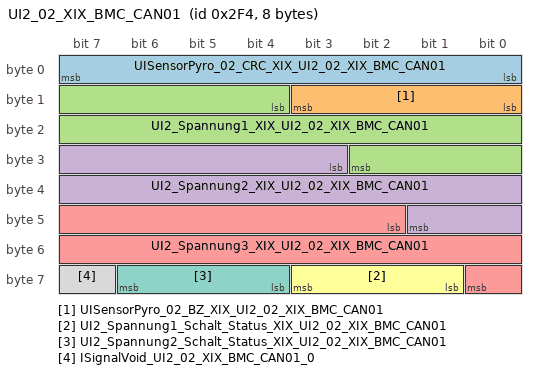
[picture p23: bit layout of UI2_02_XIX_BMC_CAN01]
      frame UI2_02_XIX_BMC_CAN01: id 0x2F4, to BMC_HV, frame-length=8, can-addressing-mode=STANDARD, can-frame-rx-behavior=CAN-20, can-frame-tx-behavior=CAN-20
        pdu UI2_02_XIX_BMC_CAN01_E2E: length=8, transmission-mode-true-timing=event-controlled-timing={number-of-repetitions=0, repetition-period=0}, unused-bit-pattern=0  # Fuer die Botschaft ist das Cyclic-Timing 0.01 zu verwenden.
          signal UISensorPyro_02_CRC_XIX_UI2_02_XIX_BMC_CAN01: start 0, 8 bit, little-endian, data-type-policy=OVERRIDE, i-signal-type=PRIMITIVE, init-value=0, base-type=BT_UISensorPyro_02_CRC, compu {phys=raw for raw 0..255}, range phys 0..255, raw 0..255, to BMC_HV(timeout 0.5 s)
          signal UISensorPyro_02_BZ_XIX_UI2_02_XIX_BMC_CAN01: start 8, 4 bit, little-endian, data-type-policy=OVERRIDE, i-signal-type=PRIMITIVE, init-value=0, base-type=BT_UISensorPyro_02_BZ, compu {phys=raw for raw 0..15}, range phys 0..15, raw 0..15, to BMC_HV(timeout 0.5 s)
          signal UI2_Spannung1_XIX_UI2_02_XIX_BMC_CAN01: start 12, 15 bit, little-endian, data-type-policy=OVERRIDE, i-signal-type=PRIMITIVE, init-value=32766, base-type=BT_UI2_Spannung1, invalid-value=Invalid_UI2_Spannung1_XIX_UI2_02_XIX_BMC_CAN01:32767, compu {phys=raw*0.0625-1023 for raw 0..32763, 32764=Cx7ffc_nicht_messbar (CM_UI2_Spannung1_Cx7ffc_nicht_messbar), 32765=Cx7ffd_nicht_verfuegbar (CM_UI2_Spannung1_Cx7ffd_nicht_verfuegbar), 32766=Cx7ffe_Init (CM_UI2_Spannung1_Cx7ffe_Init), 32767=Cx7fff_Fehler (CM_UI2_Spannung1_Cx7fff_Fehler); unit Unit_Volt}, range phys -1023..1024.6875 Unit_Volt, raw 0..32767, unit=Unit_Volt, to BMC_HV(timeout 0.5 s)  # Spannungsmesskanal 1
          signal UI2_Spannung2_XIX_UI2_02_XIX_BMC_CAN01: start 27, 15 bit, little-endian, data-type-policy=OVERRIDE, i-signal-type=PRIMITIVE, init-value=32766, base-type=BT_UI2_Spannung2, invalid-value=Invalid_UI2_Spannung2_XIX_UI2_02_XIX_BMC_CAN01:32767, compu {phys=raw*0.0625-1023 for raw 0..32763, 32764=Cx7ffc_nicht_messbar (CM_UI2_Spannung2_Cx7ffc_nicht_messbar), 32765=Cx7ffd_nicht_verfuegbar (CM_UI2_Spannung2_Cx7ffd_nicht_verfuegbar), 32766=Cx7ffe_Init (CM_UI2_Spannung2_Cx7ffe_Init), 32767=Cx7fff_Fehler (CM_UI2_Spannung2_Cx7fff_Fehler); unit Unit_Volt}, range phys -1023..1024.6875 Unit_Volt, raw 0..32767, unit=Unit_Volt, to BMC_HV(timeout 0.5 s)  # Spannungsmesskanal 2
          signal UI2_Spannung3_XIX_UI2_02_XIX_BMC_CAN01: start 42, 15 bit, little-endian, data-type-policy=OVERRIDE, i-signal-type=PRIMITIVE, init-value=32766, base-type=BT_UI2_Spannung3, invalid-value=Invalid_UI2_Spannung3_XIX_UI2_02_XIX_BMC_CAN01:32767, compu {phys=raw*0.0625-1023 for raw 0..32763, 32764=Cx7ffc_nicht_messbar (CM_UI2_Spannung3_Cx7ffc_nicht_messbar), 32765=Cx7ffd_nicht_verfuegbar (CM_UI2_Spannung3_Cx7ffd_nicht_verfuegbar), 32766=Cx7ffe_Init (CM_UI2_Spannung3_Cx7ffe_Init), 32767=Cx7fff_Fehler (CM_UI2_Spannung3_Cx7fff_Fehler); unit Unit_Volt}, range phys -1023..1024.6875 Unit_Volt, raw 0..32767, unit=Unit_Volt, to BMC_HV(timeout 0.5 s)  # Spannungsmesskanal 3
          signal UI2_Spannung1_Schalt_Status_XIX_UI2_02_XIX_BMC_CAN01: start 57, 3 bit, little-endian, data-type-policy=OVERRIDE, i-signal-type=PRIMITIVE, init-value=6, base-type=BT_UI2_Spannung1_Schalt_Status, invalid-value=Invalid_UI2_Spannung1_Schalt_Status_XIX_UI2_02_XIX_BMC_CAN01:7, compu {0=Cx0_offen (CM_UI2_Spannung1_Schalt_Status_Cx0_offen), 1=Cx1_geschlossen (CM_UI2_Spannung1_Schalt_Status_Cx1_geschlossen), 2=Cx2_defekt_geschlossen (CM_UI2_Spannung1_Schalt_Status_Cx2_defekt_geschlossen), 3=Cx3_defekt_offen (CM_UI2_Spannung1_Schalt_Status_Cx3_defekt_offen), 4=Cx4_nicht_schaltbar (CM_UI2_Spannung1_Schalt_Status_Cx4_nicht_schaltbar), 6=Cx6_Init (CM_UI2_Spannung1_Schalt_Status_Cx6_Init), 7=Cx7_Fehler (CM_UI2_Spannung1_Schalt_Status_Cx7_Fehler)}, range raw 0..7, to BMC_HV(timeout 0.5 s)  # Status des abschaltbaren Spannungsmesskanal1
          signal UI2_Spannung2_Schalt_Status_XIX_UI2_02_XIX_BMC_CAN01: start 60, 3 bit, little-endian, data-type-policy=OVERRIDE, i-signal-type=PRIMITIVE, init-value=6, base-type=BT_UI2_Spannung2_Schalt_Status, invalid-value=Invalid_UI2_Spannung2_Schalt_Status_XIX_UI2_02_XIX_BMC_CAN01:7, compu {0=Cx0_offen (CM_UI2_Spannung2_Schalt_Status_Cx0_offen), 1=Cx1_geschlossen (CM_UI2_Spannung2_Schalt_Status_Cx1_geschlossen), 2=Cx2_defekt_geschlossen (CM_UI2_Spannung2_Schalt_Status_Cx2_defekt_geschlossen), 3=Cx3_defekt_offen (CM_UI2_Spannung2_Schalt_Status_Cx3_defekt_offen), 4=Cx4_nicht_schaltbar (CM_UI2_Spannung2_Schalt_Status_Cx4_nicht_schaltbar), 6=Cx6_Init (CM_UI2_Spannung2_Schalt_Status_Cx6_Init), 7=Cx7_Fehler (CM_UI2_Spannung2_Schalt_Status_Cx7_Fehler)}, range raw 0..7, to BMC_HV(timeout 0.5 s)  # Status des abschaltbaren Spannungsmesskanal2
          signal ISignalVoid_UI2_02_XIX_BMC_CAN01_0: start 63, 1 bit, little-endian, system signal SignalVoid_UI2_02_0, data-type-policy=OVERRIDE, i-signal-type=PRIMITIVE, base-type=BT_SignalVoid
          mapping SG_UI2_02_XIX_BMC_CAN01: i-signal-group=SG_UI2_02_XIX_BMC_CAN01, transfer-property=TRIGGERED-WITHOUT-REPETITION
